VERSION "HIPBNNNYNNNNNNNNNNNNNNNNNNNNNNNNNNYYNNNNNN/4>%%%/4/'%**4NNN///"

NS_ :

BS_:

BU_: ADC BDF BDL BDR BGW CDC DDM VNC Vector_XXX

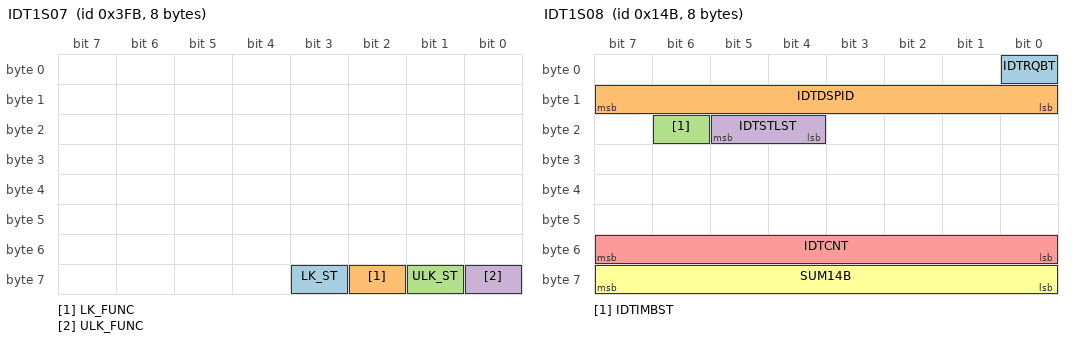
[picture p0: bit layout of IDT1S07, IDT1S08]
BO_ 1019 IDT1S07: 8 BDL
 SG_ LK_ST : 59|1@0+ (1,0) [0|0] "-"  CDC
 SG_ LK_FUNC : 58|1@0+ (1,0) [0|0] "-"  CDC
 SG_ ULK_ST : 57|1@0+ (1,0) [0|0] "-"  CDC
 SG_ ULK_FUNC : 56|1@0+ (1,0) [0|0] "-"  CDC

BO_ 331 IDT1S08: 8 BDL
 SG_ IDTRQBT : 0|1@0+ (1,0) [0|0] "-"  BGW,CDC,DDM
 SG_ IDTDSPID : 15|8@0+ (1,0) [0|0] "-"  BGW,CDC,DDM
 SG_ IDTIMBST : 22|1@0+ (1,0) [0|0] "-"  BGW,CDC,DDM
 SG_ IDTSTLST : 21|2@0+ (1,0) [0|0] "-"  BGW,CDC,DDM
 SG_ IDTCNT : 55|8@0+ (1,0) [0|0] "-"  BGW,CDC,DDM
 SG_ SUM14B : 63|8@0+ (1,0) [0|0] "-"  BGW,CDC,DDM

BO_ 1330 IDT1S15: 8 BDL
 SG_ RSISIDME : 7|2@0+ (1,0) [0|0] "-"  CDC
 SG_ RSISIDID : 5|5@0+ (1,0) [0|0] "-"  CDC

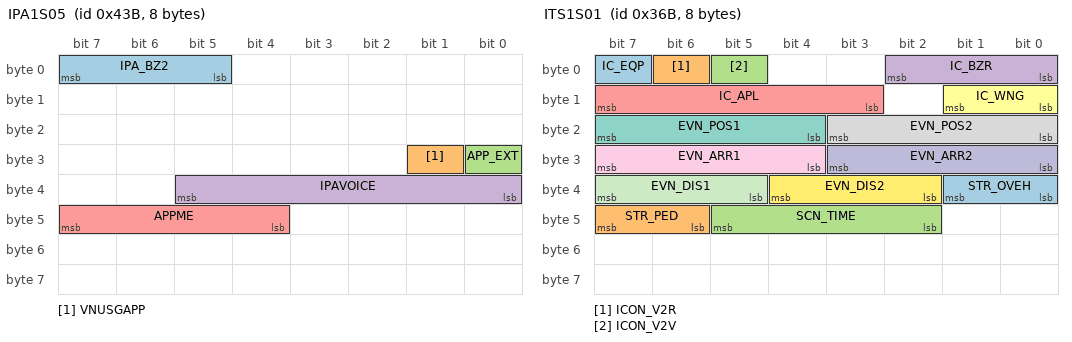
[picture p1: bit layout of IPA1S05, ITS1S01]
BO_ 1083 IPA1S05: 8 ADC
 SG_ IPA_BZ2 : 7|3@0+ (1,0) [0|0] "-"  CDC
 SG_ VNUSGAPP : 25|1@0+ (1,0) [0|0] "-"  CDC
 SG_ APP_EXT : 24|1@0+ (1,0) [0|0] "-"  CDC
 SG_ IPAVOICE : 37|6@0+ (1,0) [0|0] "-"  CDC
 SG_ APPME : 47|4@0+ (1,0) [0|0] "-"  CDC

BO_ 875 ITS1S01: 8 BGW
 SG_ IC_EQP : 7|1@0+ (1,0) [0|0] "-"  CDC
 SG_ ICON_V2R : 6|1@0+ (1,0) [0|0] "-"  CDC
 SG_ ICON_V2V : 5|1@0+ (1,0) [0|0] "-"  CDC
 SG_ IC_BZR : 2|3@0+ (1,0) [0|0] "-"  CDC
 SG_ IC_APL : 15|5@0+ (1,0) [0|0] "-"  CDC
 SG_ IC_WNG : 9|2@0+ (1,0) [0|0] "-"  CDC
 SG_ EVN_POS1 : 23|4@0+ (1,0) [0|0] "-"  CDC
 SG_ EVN_POS2 : 19|4@0+ (1,0) [0|0] "-"  CDC
 SG_ EVN_ARR1 : 31|4@0+ (1,0) [0|0] "-"  CDC
 SG_ EVN_ARR2 : 27|4@0+ (1,0) [0|0] "-"  CDC
 SG_ EVN_DIS1 : 39|3@0+ (1,0) [0|0] "-"  CDC
 SG_ EVN_DIS2 : 36|3@0+ (1,0) [0|0] "-"  CDC
 SG_ STR_OVEH : 33|2@0+ (1,0) [0|0] "-"  CDC
 SG_ STR_PED : 47|2@0+ (1,0) [0|0] "-"  CDC
 SG_ SCN_TIME : 45|4@0+ (1,0) [0|0] "-"  CDC

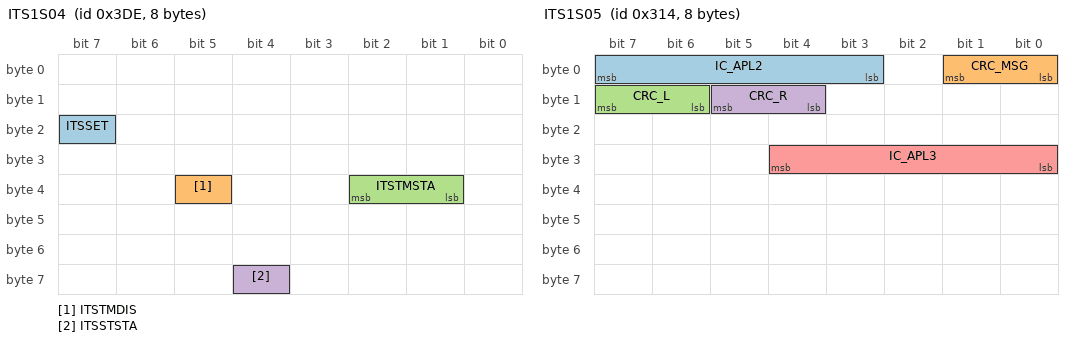
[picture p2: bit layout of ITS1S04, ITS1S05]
BO_ 990 ITS1S04: 8 BGW
 SG_ ITSSET : 23|1@0+ (1,0) [0|0] "-"  CDC
 SG_ ITSTMDIS : 37|1@0+ (1,0) [0|0] "-"  CDC
 SG_ ITSTMSTA : 34|2@0+ (1,0) [0|0] "-"  CDC
 SG_ ITSSTSTA : 60|1@0+ (1,0) [0|0] "-"  CDC

BO_ 788 ITS1S05: 8 BGW
 SG_ IC_APL2 : 7|5@0+ (1,0) [0|0] "-"  CDC
 SG_ CRC_MSG : 1|2@0+ (1,0) [0|0] "-"  CDC
 SG_ CRC_L : 15|2@0+ (1,0) [0|0] "-"  CDC
 SG_ CRC_R : 13|2@0+ (1,0) [0|0] "-"  CDC
 SG_ IC_APL3 : 28|5@0+ (1,0) [0|0] "-"  CDC

BO_ 635 ITS1S08: 8 BGW
 SG_ ITSVOI01 : 40|2@0+ (1,0) [0|0] "-"  CDC

BO_ 371 LRS1S01: 8 BDL
 SG_ LR_RC_PS : 46|8@0+ (0.5,0) [0|0] "deg"  CDC

BO_ 377 LRS1S03: 8 BDL
 SG_ LR_SL_PS : 7|10@0+ (1,0) [0|0] "mm"  CDC

BO_ 378 LRS1S04: 8 BDL
 SG_ LR_LF_PS : 7|8@0+ (0.5,0) [0|0] "deg"  CDC

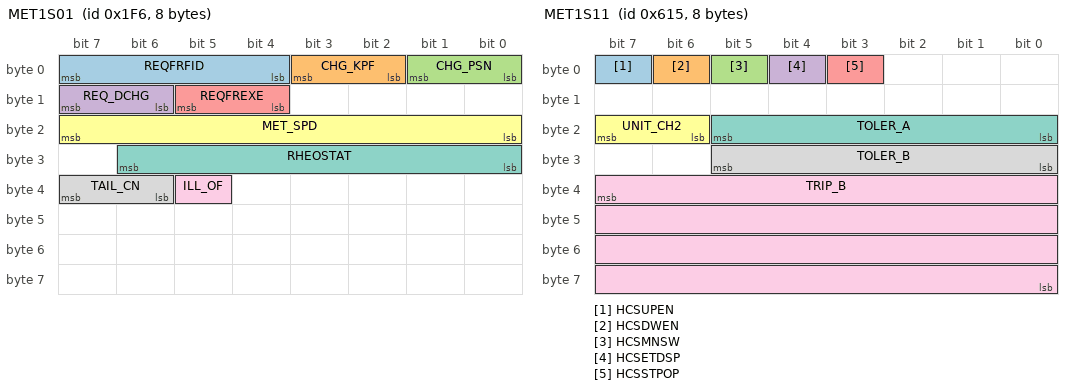
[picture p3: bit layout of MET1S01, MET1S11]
BO_ 502 MET1S01: 8 CDC
 SG_ REQFRFID : 7|4@0+ (1,0) [0|0] "-"  BDL,BGW,DDM
 SG_ CHG_KPF : 3|2@0+ (1,0) [0|0] "-"  BDL,BGW,DDM
 SG_ CHG_PSN : 1|2@0+ (1,0) [0|0] "-"  BDL,BGW,DDM
 SG_ REQ_DCHG : 15|2@0+ (1,0) [0|0] "-"  BDL,BGW,DDM
 SG_ REQFREXE : 13|2@0+ (1,0) [0|0] "-"  BDL,BGW,DDM
 SG_ MET_SPD : 23|8@0+ (1,0) [0|0] "km/h"  BDF,BDL,BDR,BGW,DDM
 SG_ RHEOSTAT : 30|7@0+ (1,0) [0|0] "%"  BDF,BDL,BGW,DDM
 SG_ TAIL_CN : 39|2@0+ (1,0) [0|0] "-"  BDF,BDL,BGW,DDM
 SG_ ILL_OF : 37|1@0+ (1,0) [0|0] "-"  BDF,BDL,BGW,DDM

BO_ 1553 MET1S02: 8 CDC
 SG_ ODO_UNIT : 29|2@0+ (1,0) [0|0] "-"  ADC,BDF,BDL,BGW,DDM,VNC
 SG_ ODO : 39|32@0+ (1,0) [0|0] "km/mile"  ADC,BDF,BDL,BGW,DDM,VNC

BO_ 1560 MET1S03: 8 CDC
 SG_ AS_DT : 47|16@0+ (0.1,0) [0|0] "km,mile"  BGW
 SG_ UNIT_2 : 63|2@0+ (1,0) [0|0] "-"  BGW

BO_ 1556 MET1S10: 8 CDC
 SG_ TRIP_A : 39|32@0+ (0.1,0) [0|0] "km/mile"  BGW

BO_ 1557 MET1S11: 8 CDC
 SG_ HCSUPEN : 7|1@0+ (1,0) [0|0] "-"  BGW,DDM
 SG_ HCSDWEN : 6|1@0+ (1,0) [0|0] "-"  BGW,DDM
 SG_ HCSMNSW : 5|1@0+ (1,0) [0|0] "-"  BGW,DDM
 SG_ HCSETDSP : 4|1@0+ (1,0) [0|0] "-"  BGW,DDM
 SG_ HCSSTPOP : 3|1@0+ (1,0) [0|0] "-"  BGW,DDM
 SG_ UNIT_CH2 : 23|2@0+ (1,0) [0|0] "-"  ADC,BGW,DDM
 SG_ TOLER_A : 21|6@0+ (0.002,0.94) [0|0] "-"  ADC,BGW,DDM
 SG_ TOLER_B : 29|6@0- (0.2,0) [0|0] "km/h"  ADC,BGW,DDM
 SG_ TRIP_B : 39|32@0+ (0.1,0) [0|0] "km/mile"  BGW,DDM

BO_ 1421 MET1S25: 8 CDC
 SG_ PSRSP1 : 23|8@0+ (1,0) [0|0] "-"  BDL
 SG_ PSRSP2 : 31|8@0+ (1,0) [0|0] "-"  BDL
 SG_ PSRSP3 : 39|8@0+ (1,0) [0|0] "-"  BDL

BO_ 1002 MET1S27: 8 CDC
 SG_ CSR_MUTE : 7|1@0+ (1,0) [0|0] "-"  ADC,BGW
 SG_ SW_LTC01 : 2|1@0+ (1,0) [0|0] "-"  ADC,BGW
 SG_ SW_RCD01 : 0|1@0+ (1,0) [0|0] "-"  ADC,BGW
 SG_ TSR_OSL : 13|3@0+ (1,0) [0|0] "-"  ADC,BGW
 SG_ TSR_SNM : 18|2@0+ (1,0) [0|0] "-"  ADC,BGW
 SG_ FCMUSER : 27|1@0+ (1,0) [0|0] "-"  ADC,BGW
 SG_ ITSSETSW : 26|1@0+ (1,0) [0|0] "-"  BGW
 SG_ RCTAMSW : 39|1@0+ (1,0) [0|0] "-"  ADC,BGW
 SG_ ICSMSW : 38|1@0+ (1,0) [0|0] "-"  ADC,BGW
 SG_ BSMMSW : 37|1@0+ (1,0) [0|0] "-"  ADC,BGW
 SG_ CSRMSW : 34|1@0+ (1,0) [0|0] "-"  ADC,BGW
 SG_ SW_ITS04 : 33|1@0+ (1,0) [0|0] "-"  BGW
 SG_ TSR_MAIN : 32|1@0+ (1,0) [0|0] "-"  ADC,BGW
 SG_ LDAMCUS : 47|2@0+ (1,0) [0|0] "-"  ADC,BGW
 SG_ PCSMSW : 40|1@0+ (1,0) [0|0] "-"  ADC,BGW
 SG_ FCMMSW : 52|1@0+ (1,0) [0|0] "-"  ADC,BGW
 SG_ LDA_SFB : 50|3@0+ (1,0) [0|0] "-"  ADC,BGW

BO_ 894 MET1S28: 8 CDC
 SG_ ACINV_SW : 7|1@0+ (1,0) [0|0] "-"  DDM
 SG_ RSCSW_OP : 8|1@0+ (1,0) [0|0] "-"  DDM

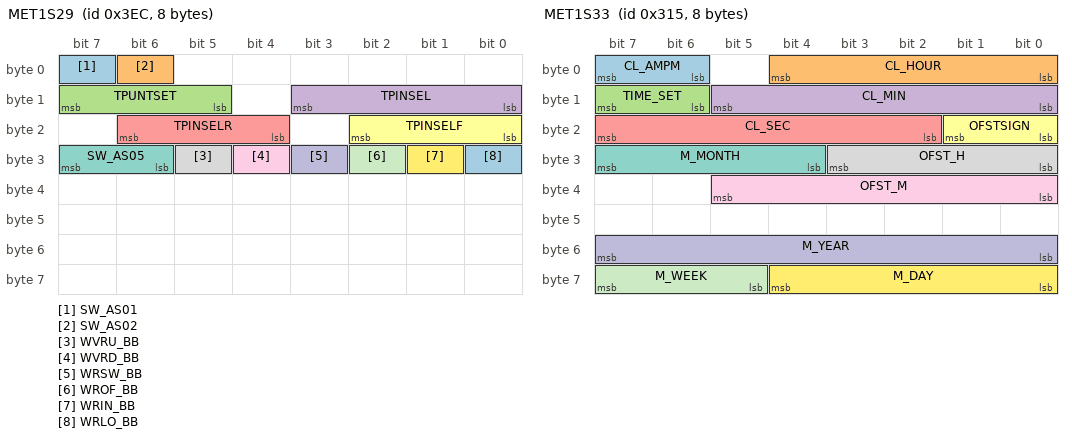
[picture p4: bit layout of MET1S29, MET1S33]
BO_ 1004 MET1S29: 8 CDC
 SG_ SW_AS01 : 7|1@0+ (1,0) [0|0] "-"  BDL,DDM
 SG_ SW_AS02 : 6|1@0+ (1,0) [0|0] "-"  BDL,DDM
 SG_ TPUNTSET : 15|3@0+ (1,0) [0|0] "-"  BDL,DDM
 SG_ TPINSEL : 11|4@0+ (1,0) [0|0] "-"  BDL,DDM
 SG_ TPINSELR : 22|3@0+ (1,0) [0|0] "-"  BDL,DDM
 SG_ TPINSELF : 18|3@0+ (1,0) [0|0] "-"  BDL,DDM
 SG_ SW_AS05 : 31|2@0+ (1,0) [0|0] "-"  BDL,DDM
 SG_ WVRU_BB : 29|1@0+ (1,0) [0|0] "-"  BDL,DDM
 SG_ WVRD_BB : 28|1@0+ (1,0) [0|0] "-"  BDL,DDM
 SG_ WRSW_BB : 27|1@0+ (1,0) [0|0] "-"  BDL,DDM
 SG_ WROF_BB : 26|1@0+ (1,0) [0|0] "-"  BDL,DDM
 SG_ WRIN_BB : 25|1@0+ (1,0) [0|0] "-"  BDL,DDM
 SG_ WRLO_BB : 24|1@0+ (1,0) [0|0] "-"  BDL,DDM

BO_ 1006 MET1S30: 8 CDC
 SG_ PBDKSW : 6|1@0+ (1,0) [0|0] "-"  BDL
 SG_ TITE_BB : 5|4@0+ (1,0) [0|0] "-"  BDL
 SG_ ASD_CANC : 1|1@0+ (1,0) [0|0] "-"  BDL
 SG_ ASD_CONT : 0|1@0+ (1,0) [0|0] "-"  BDL
 SG_ RSRMSW : 15|1@0+ (1,0) [0|0] "-"  BDL
 SG_ SRPMSW : 14|1@0+ (1,0) [0|0] "-"  ADC
 SG_ RSRCANSW : 13|1@0+ (1,0) [0|0] "-"  BDL
 SG_ VRAPRDIS : 12|1@0+ (1,0) [0|0] "-"  ADC
 SG_ PWLSW : 11|1@0+ (1,0) [0|0] "-"  BDL
 SG_ MLR_BB : 10|2@0+ (1,0) [0|0] "-"  BDL
 SG_ DPMS_BB : 8|1@0+ (1,0) [0|0] "-"  BDL
 SG_ LSW_BB : 23|3@0+ (1,0) [0|0] "-"  BDL
 SG_ WSVS_BB : 20|1@0+ (1,0) [0|0] "-"  BDL
 SG_ M_BB : 19|3@0+ (1,0) [0|0] "-"  BDL
 SG_ VRESTPSW : 31|1@0+ (1,0) [0|0] "-"  BDL
 SG_ MRT_BB : 30|2@0+ (1,0) [0|0] "-"  BDL
 SG_ RLM_BB : 28|2@0+ (1,0) [0|0] "-"  BDL
 SG_ FOG_BB : 26|2@0+ (1,0) [0|0] "-"  BDL
 SG_ MINTRSOF : 39|1@0+ (1,0) [0|0] "-"  BDL
 SG_ RFG_BB : 38|2@0+ (1,0) [0|0] "-"  BDL
 SG_ ART_BB : 36|2@0+ (1,0) [0|0] "-"  BDL
 SG_ PBD_BB : 34|3@0+ (1,0) [0|0] "-"  BDL
 SG_ POS_REG : 47|2@0+ (1,0) [0|0] "-"  BDL
 SG_ PBDBZMVL : 45|2@0+ (1,0) [0|0] "-"  BDL
 SG_ POS_CALL : 43|2@0+ (1,0) [0|0] "-"  BDL
 SG_ PBDMSW : 55|1@0+ (1,0) [0|0] "-"  BDL
 SG_ PBDMCUS : 54|3@0+ (1,0) [0|0] "-"  BDL
 SG_ ULKMSW : 51|1@0+ (1,0) [0|0] "-"  BDL
 SG_ LKMSW : 50|1@0+ (1,0) [0|0] "-"  BDL
 SG_ VRAPRMSW : 63|2@0+ (1,0) [0|0] "-"  ADC

BO_ 789 MET1S33: 8 CDC
 SG_ CL_AMPM : 7|2@0+ (1,0) [0|0] "-"  BDL,DDM
 SG_ CL_HOUR : 4|5@0+ (1,0) [0|0] "hour"  BDL,DDM
 SG_ TIME_SET : 15|2@0+ (1,0) [0|0] "-"  BDL
 SG_ CL_MIN : 13|6@0+ (1,0) [0|0] "minute"  BDL,DDM
 SG_ CL_SEC : 23|6@0+ (1,0) [0|0] "sec"  BDL,DDM
 SG_ OFSTSIGN : 17|2@0+ (1,0) [0|0] "-"  BDL
 SG_ M_MONTH : 31|4@0+ (1,0) [0|0] "-"  BDL
 SG_ OFST_H : 27|4@0+ (1,0) [0|0] "hour"  BDL
 SG_ OFST_M : 37|6@0+ (1,0) [0|0] "minute"  BDL
 SG_ M_YEAR : 55|8@0+ (1,2000) [0|0] "year"  BDL
 SG_ M_WEEK : 63|3@0+ (1,0) [0|0] "-"  BDL,DDM
 SG_ M_DAY : 60|5@0+ (1,0) [0|0] "-"  BDL

BO_ 1316 MET1S38: 32 CDC
 SG_ AS_TM : 7|16@0+ (1,0) [0|0] "min"  BGW
 SG_ EC_SCL : 20|3@0+ (1,0) [0|0] "-"  BGW
 SG_ TR2_DUTY : 17|10@0+ (0.1,0) [0|0] "%"  BDL,BGW
 SG_ IL2_DUTY : 55|10@0+ (0.1,0) [0|0] "%"  BDL,BGW
 SG_ RANGE : 71|16@0+ (1,0) [0|0] "Note"  BGW
 SG_ AS_SP : 87|16@0+ (0.1,0) [0|0] "km/h,mph"  BGW
 SG_ UNIT_1 : 103|2@0+ (1,0) [0|0] "-"  BGW
 SG_ UNIT_6 : 101|3@0+ (1,0) [0|0] "-"  BGW
 SG_ NFCS : 98|2@0+ (1,0) [0|0] "-"  BGW
 SG_ RHEO_POS : 96|5@0+ (1,0) [0|0] "-"  BDL,BGW

BO_ 1319 MET1S41: 8 CDC
 SG_ ST_ACOFF : 32|1@0+ (1,0) [0|0] "-"  BDF,BDL
 SG_ ST_TDEF : 55|1@0+ (1,0) [0|0] "-"  BDF,BDL
 SG_ ST_TAUTO : 54|1@0+ (1,0) [0|0] "-"  BDF,BDL

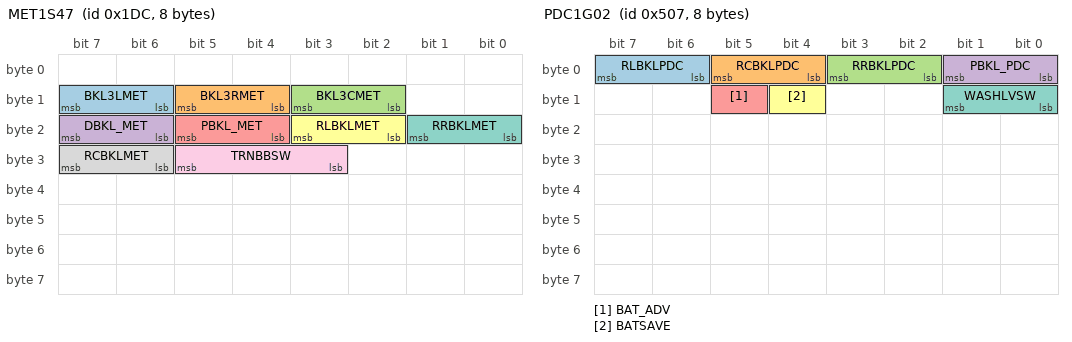
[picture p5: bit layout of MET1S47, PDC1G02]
BO_ 476 MET1S47: 8 CDC
 SG_ BKL3LMET : 15|2@0+ (1,0) [0|0] "-"  BGW,DDM
 SG_ BKL3RMET : 13|2@0+ (1,0) [0|0] "-"  BGW,DDM
 SG_ BKL3CMET : 11|2@0+ (1,0) [0|0] "-"  BGW,DDM
 SG_ DBKL_MET : 23|2@0+ (1,0) [0|0] "-"  ADC,BDL,BDR,BGW,DDM,VNC
 SG_ PBKL_MET : 21|2@0+ (1,0) [0|0] "-"  ADC,BDL,BDR,BGW,DDM,VNC
 SG_ RLBKLMET : 19|2@0+ (1,0) [0|0] "-"  BDL,BDR,BGW,DDM,VNC
 SG_ RRBKLMET : 17|2@0+ (1,0) [0|0] "-"  BDL,BDR,BGW,DDM,VNC
 SG_ RCBKLMET : 31|2@0+ (1,0) [0|0] "-"  BGW,DDM,VNC
 SG_ TRNBBSW : 29|3@0+ (1,0) [0|0] "-"  ADC,BGW,DDM

BO_ 781 MET1S52: 8 CDC
 SG_ ODO_UNI2 : 31|2@0+ (1,0) [0|0] "-"  BGW
 SG_ ODO_01 : 39|32@0+ (0.1,0) [0|0] "km"  BGW

BO_ 503 MET1S55: 32 CDC
 SG_ IN_EC : 7|16@0+ (0.1,0) [0|0] "Note"  BGW
 SG_ M1_EC1 : 23|16@0+ (0.1,0) [0|0] "km/kW, mile/kW(US), mile/kW(UK),"  BGW
 SG_ M1_EC_R : 55|1@0+ (1,0) [0|0] "-"  BGW
 SG_ EV_RANGE : 63|16@0+ (1,0) [0|0] "Note"  BGW,VNC
 SG_ TO_EC : 79|16@0+ (0.1,0) [0|0] "km/kW, mile/kW(US), mile/kW(UK),"  BGW
 SG_ AS_EC : 95|16@0+ (0.1,0) [0|0] "km/kW, mile/kW(US), mile/kW(UK),"  BGW
 SG_ AS_TOEC : 111|16@0+ (0.1,0) [0|0] "kWh"  BGW
 SG_ AS_EVDT : 127|16@0+ (0.1,0) [0|0] "km,mile"  BGW

BO_ 1050 MET1S62: 8 CDC
 SG_ RNGMSW : 35|1@0+ (1,0) [0|0] "-"  DDM
 SG_ TBCSW : 41|1@0+ (1,0) [0|0] "-"  DDM
 SG_ TBWSW : 40|1@0+ (1,0) [0|0] "-"  DDM

BO_ 957 PCN1S01: 32 DDM
 SG_ MSG_NSFT : 9|2@0+ (1,0) [0|0] "-"  CDC
 SG_ MSG_CHK : 21|1@0+ (1,0) [0|0] "-"  CDC
 SG_ MSG_SFTF : 31|1@0+ (1,0) [0|0] "-"  CDC
 SG_ B_SLUP_S : 30|1@0+ (1,0) [0|0] "-"  CDC
 SG_ B_SLDN_S : 29|1@0+ (1,0) [0|0] "-"  CDC
 SG_ MSG_RI_S : 28|5@0+ (1,0) [0|0] "-"  CDC
 SG_ BZR_SFT1 : 55|4@0+ (1,0) [0|0] "-"  CDC
 SG_ B_GEAR_S : 51|4@0+ (1,0) [0|0] "-"  CDC
 SG_ MSG_SFPF : 61|1@0+ (1,0) [0|0] "-"  CDC
 SG_ SBWFUNC : 60|1@0+ (1,0) [0|0] "-"  CDC
 SG_ SFT_BLKS : 59|2@0+ (1,0) [0|0] "-"  CDC
 SG_ SFT_METS : 57|4@0+ (1,0) [0|0] "-"  CDC
 SG_ SILUASBW : 69|1@0+ (1,0) [0|0] "-"  CDC
 SG_ MSG_DAP : 68|1@0+ (1,0) [0|0] "-"  CDC
 SG_ MSG_ACCN : 67|1@0+ (1,0) [0|0] "-"  CDC
 SG_ FV3BD : 175|56@0+ (1,0) [0|0] "-"  CDC
 SG_ KZK3BD : 231|32@0+ (1,0) [0|0] "-"  CDC

BO_ 460 PDC1G01: 8 BDL
 SG_ BAOF_PDC : 25|1@0+ (1,0) [0|0] "-"  CDC,DDM

BO_ 1287 PDC1G02: 8 BDF
 SG_ RLBKLPDC : 7|2@0+ (1,0) [0|0] "-"  CDC
 SG_ RCBKLPDC : 5|2@0+ (1,0) [0|0] "-"  CDC
 SG_ RRBKLPDC : 3|2@0+ (1,0) [0|0] "-"  CDC
 SG_ PBKL_PDC : 1|2@0+ (1,0) [0|0] "-"  CDC
 SG_ BAT_ADV : 13|1@0+ (1,0) [0|0] "-"  CDC
 SG_ BATSAVE : 12|1@0+ (1,0) [0|0] "-"  CDC
 SG_ WASHLVSW : 9|2@0+ (1,0) [0|0] "-"  CDC

BO_ 661 PLG1G15: 32 DDM
 SG_ OTACHGWT : 31|2@0+ (1,0) [0|0] "-"  BGW,CDC
 SG_ P_SPLNSO : 47|1@0+ (1,0) [0|0] "-"  BGW,CDC
 SG_ P_DVOAVA : 71|2@0+ (1,0) [0|0] "-"  BGW,CDC
 SG_ P_DVOSL1 : 69|1@0+ (1,0) [0|0] "-"  BGW,CDC
 SG_ P_WLCEQP : 72|1@0+ (1,0) [0|0] "-"  BGW,CDC
 SG_ P_SETID : 87|6@0+ (1,0) [0|0] "-"  BGW,CDC
 SG_ P_SETON : 95|1@0+ (1,0) [0|0] "-"  BGW,CDC
 SG_ P_SETWKD : 94|7@0+ (1,0) [0|0] "-"  BGW,CDC
 SG_ P_SETTYP : 103|4@0+ (1,0) [0|0] "-"  BGW,CDC
 SG_ P_SETSTM : 96|9@0+ (5,0) [0|0] "min"  BGW,CDC
 SG_ P_SETNXT : 119|6@0+ (1,0) [0|0] "-"  BGW,CDC
 SG_ P_SETFTM : 112|9@0+ (5,0) [0|0] "min"  BGW,CDC
 SG_ P_TMPID : 135|6@0+ (1,0) [0|0] "-"  BGW,CDC
 SG_ P_TMPSWK : 142|7@0+ (1,0) [0|0] "-"  BGW,CDC
 SG_ P_TMPSTM : 151|9@0+ (5,0) [0|0] "min"  BGW,CDC
 SG_ P_ADDDSP : 158|1@0+ (1,0) [0|0] "-"  BGW,CDC
 SG_ PCNOWDSP : 155|2@0+ (1,0) [0|0] "-"  BGW,CDC
 SG_ P_EDTDSP : 153|1@0+ (1,0) [0|0] "-"  BGW,CDC
 SG_ P_TMPTYP : 167|4@0+ (1,0) [0|0] "-"  BGW,CDC
 SG_ P_TMPNWK : 163|3@0+ (1,0) [0|0] "-"  BGW,CDC
 SG_ P_TMPFTM : 160|9@0+ (5,0) [0|0] "min"  BGW,CDC
 SG_ P_DPWAVA : 177|2@0+ (1,0) [0|0] "-"  BGW,CDC
 SG_ P_DPWSL : 198|4@0+ (1,0) [0|0] "-"  BGW,CDC

BO_ 662 PLG1G16: 32 DDM
 SG_ PLGSTS : 103|8@0+ (1,0) [0|0] "-"  BGW,CDC
 SG_ PIINFD08 : 111|8@0+ (1,0) [0|0] "-"  BGW,CDC
 SG_ PIINFDSP : 119|1@0+ (1,0) [0|0] "-"  BGW,CDC
 SG_ PSDSPRQ2 : 118|1@0+ (1,0) [0|0] "-"  BGW,CDC
 SG_ PSDSPRQ : 117|1@0+ (1,0) [0|0] "-"  BGW,CDC
 SG_ P_CLCSL4 : 115|1@0+ (1,0) [0|0] "-"  BGW,CDC
 SG_ P_CLCSL3 : 114|1@0+ (1,0) [0|0] "-"  BGW,CDC
 SG_ P_CLCSL2 : 113|1@0+ (1,0) [0|0] "-"  BGW,CDC
 SG_ P_CLCSL1 : 112|1@0+ (1,0) [0|0] "-"  BGW,CDC
 SG_ P_LMDAVA : 126|2@0+ (1,0) [0|0] "-"  BGW,CDC
 SG_ PLID_DSP : 124|1@0+ (1,0) [0|0] "-"  BGW,CDC
 SG_ P_LMDNW : 123|1@0+ (1,0) [0|0] "-"  BGW,CDC
 SG_ DCRCKDSP : 122|3@0+ (1,0) [0|0] "-"  BGW,CDC
 SG_ P_SETSTS : 131|4@0+ (1,0) [0|0] "-"  BGW,CDC
 SG_ P_DPW : 139|4@0+ (1,0) [0|0] "-"  BGW,CDC
 SG_ P_NCTYP : 151|4@0+ (1,0) [0|0] "-"  BGW,CDC
 SG_ P_NCWKD : 147|3@0+ (1,0) [0|0] "-"  BGW,CDC
 SG_ P_NCSTM : 144|9@0+ (5,0) [0|0] "min"  BGW,CDC
 SG_ P_SLMSL1 : 166|1@0+ (1,0) [0|0] "-"  BGW,CDC
 SG_ P_NCDSP : 162|2@0+ (1,0) [0|0] "-"  BGW,CDC
 SG_ P_NCFTM : 160|9@0+ (5,0) [0|0] "min"  BGW,CDC
 SG_ P_SLMSL3 : 183|1@0+ (1,0) [0|0] "-"  BGW,CDC
 SG_ P_SLMSL2 : 182|1@0+ (1,0) [0|0] "-"  BGW,CDC
 SG_ P_NCLMT : 181|3@0+ (1,0) [0|0] "-"  BGW,CDC
 SG_ P_NCCUR : 178|3@0+ (1,0) [0|0] "-"  BGW,CDC
 SG_ P_SLMSL5 : 191|1@0+ (1,0) [0|0] "-"  BGW,CDC
 SG_ P_SLMSL4 : 190|1@0+ (1,0) [0|0] "-"  BGW,CDC
 SG_ P_SLMNOW : 186|3@0+ (1,0) [0|0] "-"  BGW,CDC
 SG_ PCHGTM07 : 199|16@0+ (1,0) [0|0] "min"  BGW,CDC
 SG_ P_TMRAVA : 215|2@0+ (1,0) [0|0] "-"  BGW,CDC
 SG_ P_CURAVA : 213|2@0+ (1,0) [0|0] "-"  BGW,CDC
 SG_ P_LMTAVA : 211|2@0+ (1,0) [0|0] "-"  BGW,CDC
 SG_ P_CLCAVA : 209|2@0+ (1,0) [0|0] "-"  BGW,CDC
 SG_ P_LMTDSP : 222|3@0+ (1,0) [0|0] "-"  BGW,CDC
 SG_ P_SPLAVA : 219|2@0+ (1,0) [0|0] "-"  BGW,CDC
 SG_ P_SLMAVA : 217|2@0+ (1,0) [0|0] "-"  BGW,CDC
 SG_ P_TMRSTR : 231|2@0+ (1,0) [0|0] "-"  BGW,CDC
 SG_ P_TMRSST : 227|2@0+ (1,0) [0|0] "-"  BGW,CDC
 SG_ P_SPLEVA : 239|2@0+ (1,0) [0|0] "-"  BGW,CDC
 SG_ P_SPLHVA : 247|2@0+ (1,0) [0|0] "-"  BGW,CDC
 SG_ P_LMTSEL : 245|3@0+ (1,0) [0|0] "-"  BGW,CDC
 SG_ P_LMTNOW : 242|3@0+ (1,0) [0|0] "-"  BGW,CDC
 SG_ P_SPLDSP : 255|2@0+ (1,0) [0|0] "-"  BGW,CDC
 SG_ P_SPLEVW : 253|1@0+ (1,0) [0|0] "-"  BGW,CDC
 SG_ P_SPLACA : 252|1@0+ (1,0) [0|0] "-"  BGW,CDC
 SG_ P_SPLDCA : 251|1@0+ (1,0) [0|0] "-"  BGW,CDC

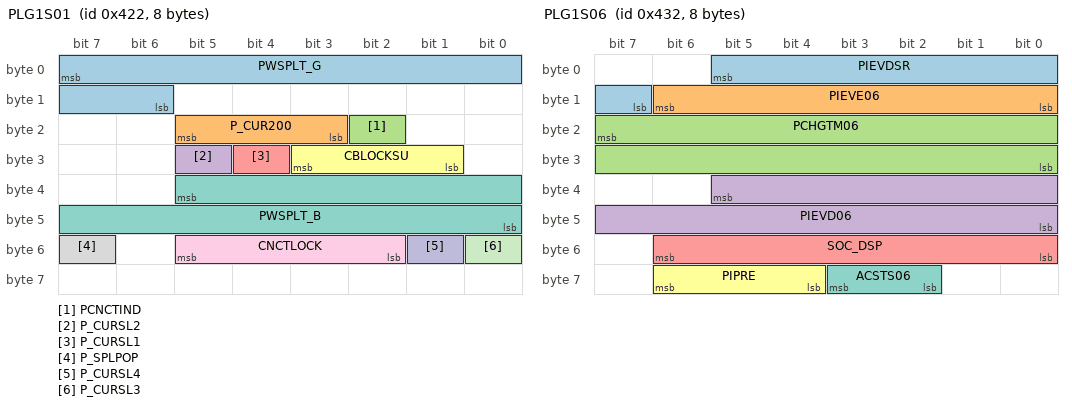
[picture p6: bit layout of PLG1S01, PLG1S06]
BO_ 1058 PLG1S01: 8 DDM
 SG_ PWSPLT_G : 7|10@0+ (1,0) [0|0] "hour"  BGW,CDC
 SG_ P_CUR200 : 21|3@0+ (1,0) [0|0] "-"  BGW,CDC
 SG_ PCNCTIND : 18|1@0+ (1,0) [0|0] "-"  BGW,CDC
 SG_ P_CURSL2 : 29|1@0+ (1,0) [0|0] "-"  BGW,CDC
 SG_ P_CURSL1 : 28|1@0+ (1,0) [0|0] "-"  BGW,CDC
 SG_ CBLOCKSU : 27|3@0+ (1,0) [0|0] "-"  BGW,CDC
 SG_ PWSPLT_B : 37|14@0+ (10,0) [0|0] "min"  BGW,CDC
 SG_ P_SPLPOP : 55|1@0+ (1,0) [0|0] "-"  BGW,CDC
 SG_ CNCTLOCK : 53|4@0+ (1,0) [0|0] "-"  BGW,CDC
 SG_ P_CURSL4 : 49|1@0+ (1,0) [0|0] "-"  BGW,CDC
 SG_ P_CURSL3 : 48|1@0+ (1,0) [0|0] "-"  BGW,CDC

BO_ 1073 PLG1S05: 8 DDM
 SG_ MRMMSG : 20|3@0+ (1,0) [0|0] "-"  CDC

BO_ 1074 PLG1S06: 8 DDM
 SG_ PIEVDSR : 5|7@0+ (1,0) [0|0] "%"  BGW,CDC
 SG_ PIEVE06 : 14|7@0+ (1,0) [0|0] "%"  BGW,CDC
 SG_ PCHGTM06 : 23|16@0+ (1,0) [0|0] "min"  BGW,CDC
 SG_ PIEVD06 : 37|14@0+ (0.1,0) [0|0] "km"  BGW,CDC
 SG_ SOC_DSP : 54|7@0+ (1,0) [0|0] "%"  BGW,CDC
 SG_ PIPRE : 62|3@0+ (1,0) [0|0] "-"  BGW,CDC
 SG_ ACSTS06 : 59|2@0+ (1,0) [0|0] "-"  BGW,CDC

BO_ 678 PLG1S20: 32 DDM
 SG_ R_NBPSET : 7|1@0+ (1,0) [0|0] "-"  BGW,CDC
 SG_ R_NACSET : 6|1@0+ (1,0) [0|0] "-"  BGW,CDC
 SG_ R_ADDDSP : 5|1@0+ (1,0) [0|0] "-"  BGW,CDC
 SG_ R_BPEXST : 4|1@0+ (1,0) [0|0] "-"  BGW,CDC
 SG_ R_BPON : 3|1@0+ (1,0) [0|0] "-"  BGW,CDC
 SG_ R_BPSET : 2|1@0+ (1,0) [0|0] "-"  BGW,CDC
 SG_ R_ACSET : 1|1@0+ (1,0) [0|0] "-"  BGW,CDC
 SG_ R_NDEPTM : 0|9@0+ (5,0) [0|0] "min"  BGW,CDC
 SG_ P_VPAVST : 23|1@0+ (1,0) [0|0] "-"  BGW,CDC
 SG_ R_NBPWKD : 22|3@0+ (1,0) [0|0] "-"  BGW,CDC
 SG_ R_BPID : 19|3@0+ (1,0) [0|0] "-"  BGW,CDC
 SG_ R_DEPTM : 16|9@0+ (5,0) [0|0] "min"  BGW,CDC
 SG_ R_BPWKD : 39|7@0+ (1,0) [0|0] "-"  BGW,CDC
 SG_ P_VPVGST : 32|1@0+ (1,0) [0|0] "-"  BGW,CDC
 SG_ P_OCTAVA : 47|3@0+ (1,0) [0|0] "-"  BGW,CDC
 SG_ P_OCTID : 41|2@0+ (1,0) [0|0] "-"  BGW,CDC
 SG_ P_LMTNO2 : 55|3@0+ (1,0) [0|0] "-"  BGW,CDC
 SG_ P_OCTON : 52|1@0+ (1,0) [0|0] "-"  BGW,CDC
 SG_ P_OCTTYP : 51|2@0+ (1,0) [0|0] "-"  BGW,CDC
 SG_ P_OCTON2 : 49|1@0+ (1,0) [0|0] "-"  BGW,CDC
 SG_ P_OCTSTM : 48|9@0+ (5,0) [0|0] "minute"  BGW,CDC
 SG_ P_OCTWKD : 71|7@0+ (1,0) [0|0] "-"  BGW,CDC
 SG_ P_OCTFTM : 64|9@0+ (5,0) [0|0] "minute"  BGW,CDC
 SG_ P_OCTWK2 : 87|7@0+ (1,0) [0|0] "-"  BGW,CDC
 SG_ P_OCTST2 : 80|9@0+ (5,0) [0|0] "minute"  BGW,CDC
 SG_ P_USOC2A : 103|7@0+ (1,0) [0|0] "percent"  BGW,CDC
 SG_ P_OCTFT2 : 96|9@0+ (5,0) [0|0] "minute"  BGW,CDC
 SG_ P_USOC1A : 119|7@0+ (1,0) [0|0] "percent"  BGW,CDC
 SG_ P_LMDSTM : 112|9@0+ (5,0) [0|0] "minute"  BGW,CDC
 SG_ P_USOC0A : 135|7@0+ (1,0) [0|0] "percent"  BGW,CDC
 SG_ P_LMDFTM : 128|9@0+ (5,0) [0|0] "minute"  BGW,CDC
 SG_ P_LMDLMT : 151|7@0+ (1,0) [0|0] "percent"  BGW,CDC
 SG_ P_LMDST2 : 144|9@0+ (5,0) [0|0] "minute"  BGW,CDC
 SG_ P_LMDWKD : 167|7@0+ (1,0) [0|0] "-"  BGW,CDC
 SG_ P_LMDFT2 : 160|9@0+ (5,0) [0|0] "minute"  BGW,CDC
 SG_ P_LMDLM2 : 183|7@0+ (1,0) [0|0] "percent"  BGW,CDC
 SG_ P_OCADFL : 176|1@0+ (1,0) [0|0] "-"  BGW,CDC
 SG_ P_LMDWK2 : 191|7@0+ (1,0) [0|0] "-"  BGW,CDC
 SG_ P_OCFLFL : 184|1@0+ (1,0) [0|0] "-"  BGW,CDC
 SG_ P_OCTTY2 : 199|2@0+ (1,0) [0|0] "-"  BGW,CDC
 SG_ P_OCRQFL : 197|2@0+ (1,0) [0|0] "-"  BGW,CDC
 SG_ P_OCNFFL : 195|1@0+ (1,0) [0|0] "-"  BGW,CDC
 SG_ EV_CON_N : 207|4@0+ (1,0) [0|0] "-"  BGW,CDC
 SG_ EV_CON_Q : 203|4@0+ (1,0) [0|0] "-"  BGW,CDC
 SG_ P_VPSOCT : 222|7@0+ (1,0) [0|0] "%"  BGW,CDC
 SG_ P_VPSOCL : 230|7@0+ (1,0) [0|0] "%"  BGW,CDC

BO_ 516 PLG1S21: 32 DDM
 SG_ P_PNC : 7|1@0+ (1,0) [0|0] "-"  BGW,CDC
 SG_ P_ACINST : 12|3@0+ (1,0) [0|0] "-"  BGW,CDC
 SG_ P_PNCAVA : 9|2@0+ (1,0) [0|0] "-"  BGW,CDC
 SG_ P_CEIBRQ : 23|2@0+ (1,0) [0|0] "-"  BGW,CDC
 SG_ P_CEEXPD : 21|5@0+ (1,0) [0|0] "-"  BGW,CDC
 SG_ ACTCHGRT : 37|14@0+ (0.05,0) [0|0] "kW"  BGW,CDC
 SG_ CRTDSPRQ : 55|2@0+ (0.05,0) [0|0] "kW"  BGW,CDC
 SG_ MXCHGRT : 53|14@0+ (0.05,0) [0|0] "kW"  BGW,CDC
 SG_ ACTOPSPW : 71|8@0+ (0.1,0) [0|0] "kW"  BGW,CDC
 SG_ MXOPSPW : 79|8@0+ (0.1,0) [0|0] "kW"  BGW,CDC
 SG_ SPWDSPRQ : 84|2@0+ (1,0) [0|0] "-"  BGW,CDC
 SG_ PSPLTAVA : 82|3@0+ (1,0) [0|0] "-"  BGW,CDC
 SG_ P_CEEXPY : 95|8@0+ (1,0) [0|0] "-"  BGW,CDC
 SG_ P_CEEXPM : 103|4@0+ (1,0) [0|0] "-"  BGW,CDC

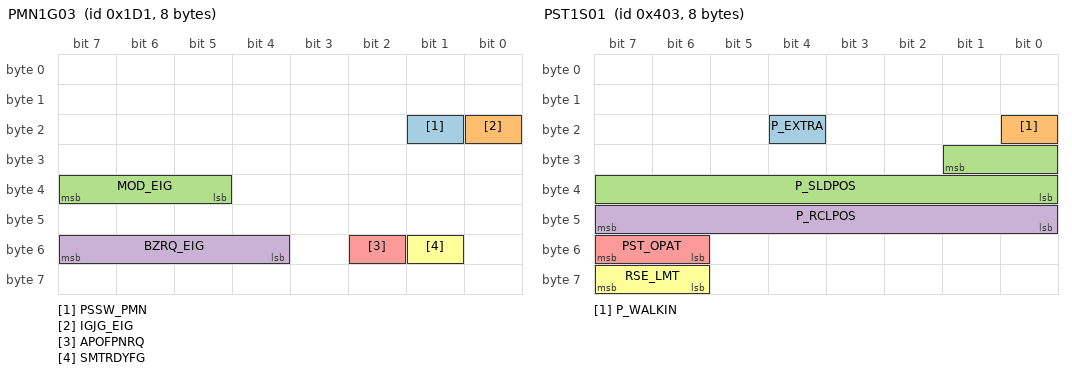
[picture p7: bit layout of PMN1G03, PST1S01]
BO_ 465 PMN1G03: 8 BDL
 SG_ PSSW_PMN : 17|1@0+ (1,0) [0|0] "-"  BGW,CDC
 SG_ IGJG_EIG : 16|1@0+ (1,0) [0|0] "-"  BGW,CDC,DDM
 SG_ MOD_EIG : 39|3@0+ (1,0) [0|0] "-"  BGW,CDC,DDM
 SG_ BZRQ_EIG : 55|4@0+ (1,0) [0|0] "-"  BGW,CDC,DDM
 SG_ APOFPNRQ : 50|1@0+ (1,0) [0|0] "-"  BGW,CDC,DDM
 SG_ SMTRDYFG : 49|1@0+ (1,0) [0|0] "-"  BGW,CDC,DDM

BO_ 1027 PST1S01: 8 BDL
 SG_ P_EXTRA : 20|1@0+ (1,0) [0|0] "-"  CDC
 SG_ P_WALKIN : 16|1@0+ (1,0) [0|0] "-"  CDC
 SG_ P_SLDPOS : 25|10@0+ (1,0) [0|0] "mm"  CDC
 SG_ P_RCLPOS : 47|8@0+ (0.5,0) [0|0] "deg"  CDC
 SG_ PST_OPAT : 55|2@0+ (1,0) [0|0] "-"  CDC
 SG_ RSE_LMT : 63|2@0+ (1,0) [0|0] "-"  CDC

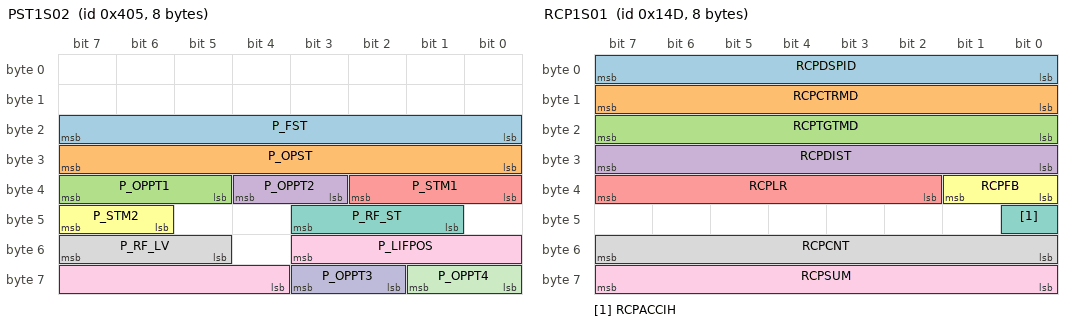
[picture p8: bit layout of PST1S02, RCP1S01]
BO_ 1029 PST1S02: 8 BDL
 SG_ P_FST : 23|8@0+ (1,0) [0|0] "-"  CDC
 SG_ P_OPST : 31|8@0+ (1,0) [0|0] "-"  CDC
 SG_ P_OPPT1 : 39|3@0+ (1,0) [0|0] "-"  CDC
 SG_ P_OPPT2 : 36|2@0+ (1,0) [0|0] "-"  CDC
 SG_ P_STM1 : 34|3@0+ (1,0) [0|0] "-"  CDC
 SG_ P_STM2 : 47|2@0+ (1,0) [0|0] "-"  CDC
 SG_ P_RF_ST : 43|3@0+ (1,0) [0|0] "-"  CDC
 SG_ P_RF_LV : 55|3@0+ (1,0) [0|0] "-"  CDC
 SG_ P_LIFPOS : 51|8@0+ (1,0) [0|0] "mm"  CDC
 SG_ P_OPPT3 : 59|2@0+ (1,0) [0|0] "-"  CDC
 SG_ P_OPPT4 : 57|2@0+ (1,0) [0|0] "-"  CDC

BO_ 333 RCP1S01: 8 ADC
 SG_ RCPDSPID : 7|8@0+ (1,0) [0|0] "-"  BGW,CDC
 SG_ RCPCTRMD : 15|8@0+ (1,0) [0|0] "-"  BGW,CDC
 SG_ RCPTGTMD : 23|8@0+ (1,0) [0|0] "-"  BGW,CDC
 SG_ RCPDIST : 31|8@0+ (1,0) [0|0] "-"  BGW,CDC
 SG_ RCPLR : 39|6@0+ (1,0) [0|0] "-"  BGW,CDC
 SG_ RCPFB : 33|2@0+ (1,0) [0|0] "-"  BGW,CDC
 SG_ RCPACCIH : 40|1@0+ (1,0) [0|0] "-"  BGW,CDC
 SG_ RCPCNT : 55|8@0+ (1,0) [0|0] "-"  BGW,CDC
 SG_ RCPSUM : 63|8@0+ (1,0) [0|0] "-"  BGW,CDC

BO_ 335 RCP1S03: 8 ADC
 SG_ RCPMD : 31|3@0+ (1,0) [0|0] "-"  CDC
 SG_ RCPFAIL : 27|1@0+ (1,0) [0|0] "-"  CDC
 SG_ RCPONST : 36|1@0+ (1,0) [0|0] "-"  CDC

BO_ 386 RRS1S01: 8 BDL
 SG_ RR_RC_PS : 46|8@0+ (0.5,0) [0|0] "deg"  CDC

BO_ 393 RRS1S03: 8 BDL
 SG_ RR_SL_PS : 7|10@0+ (1,0) [0|0] "mm"  CDC

BO_ 396 RRS1S04: 8 BDL
 SG_ RR_LF_PS : 7|8@0+ (0.5,0) [0|0] "deg"  CDC

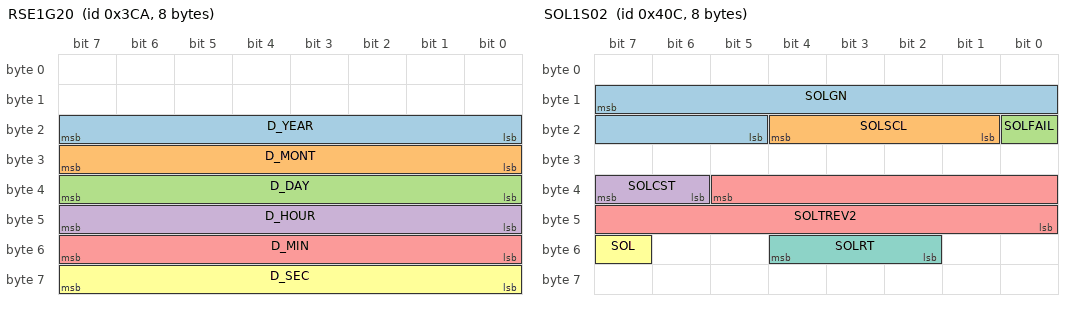
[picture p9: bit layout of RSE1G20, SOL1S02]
BO_ 970 RSE1G20: 8 BGW
 SG_ D_YEAR : 23|8@0+ (1,0) [0|0] "-"  CDC
 SG_ D_MONT : 31|8@0+ (1,0) [0|0] "-"  CDC
 SG_ D_DAY : 39|8@0+ (1,0) [0|0] "-"  CDC
 SG_ D_HOUR : 47|8@0+ (1,0) [0|0] "-"  CDC
 SG_ D_MIN : 55|8@0+ (1,0) [0|0] "-"  CDC
 SG_ D_SEC : 63|8@0+ (1,0) [0|0] "-"  CDC

BO_ 815 RSE1G24: 8 BGW
 SG_ LATUDE : 13|1@0+ (1,0) [0|0] "-"  CDC,DDM
 SG_ LOTUDE1 : 12|1@0+ (1,0) [0|0] "-"  CDC,DDM
 SG_ D_LAT1 : 39|8@0+ (1,0) [0|0] "deg"  CDC,DDM
 SG_ D_LAT2 : 47|24@0+ (5.96046447753906E-008,0) [0|0] "deg"  CDC,DDM

BO_ 822 RSE1G25: 8 BGW
 SG_ D_LON1 : 39|8@0+ (1,0) [0|0] "deg"  CDC,DDM
 SG_ D_LON2 : 47|24@0+ (5.96046447753906E-008,0) [0|0] "deg"  CDC,DDM

BO_ 845 RSE1G26: 8 BGW
 SG_ ALTITUDE : 47|24@0- (0.01,0) [0|0] "m"  CDC,DDM

BO_ 901 RSE1G29: 8 BGW
 SG_ OTADTYPE : 7|4@0+ (1,0) [0|0] "-"  CDC
 SG_ OTADSTAT : 3|4@0+ (1,0) [0|0] "-"  CDC
 SG_ OTADPROG : 15|8@0+ (1,0) [0|0] "%"  CDC
 SG_ OTADERR : 23|8@0+ (1,0) [0|0] "-"  CDC

BO_ 968 RSE1S02: 8 BGW
 SG_ RSCYCL11 : 23|8@0+ (1,0) [0|0] "-"  CDC,DDM
 SG_ RSCYCL12 : 31|8@0+ (1,0) [0|0] "-"  CDC,DDM
 SG_ RSCYCL13 : 39|8@0+ (1,0) [0|0] "-"  CDC,DDM
 SG_ RSCYCL14 : 47|8@0+ (1,0) [0|0] "-"  CDC,DDM
 SG_ RSCYCL15 : 55|8@0+ (1,0) [0|0] "-"  CDC,DDM
 SG_ RSCYCL16 : 63|8@0+ (1,0) [0|0] "-"  CDC,DDM

BO_ 808 RST1S03: 8 BDL
 SG_ S_RTST_L : 31|1@0+ (1,0) [0|0] "-"  CDC
 SG_ S_RTST_R : 30|1@0+ (1,0) [0|0] "-"  CDC
 SG_ RR_FST : 29|2@0+ (1,0) [0|0] "-"  CDC
 SG_ RL_FST : 27|2@0+ (1,0) [0|0] "-"  CDC
 SG_ RR_OPST : 25|2@0+ (1,0) [0|0] "-"  CDC
 SG_ RL_OPST : 39|2@0+ (1,0) [0|0] "-"  CDC
 SG_ RR_STM1 : 37|3@0+ (1,0) [0|0] "-"  CDC
 SG_ RL_STM1 : 34|3@0+ (1,0) [0|0] "-"  CDC
 SG_ SEAR_ST1 : 46|2@0+ (1,0) [0|0] "-"  CDC
 SG_ SEAR_ST2 : 44|2@0+ (1,0) [0|0] "-"  CDC
 SG_ SEAT_AR : 42|3@0+ (1,0) [0|0] "-"  CDC
 SG_ WIR_ST : 55|2@0+ (1,0) [0|0] "-"  CDC
 SG_ WIR_OPST : 53|2@0+ (1,0) [0|0] "-"  CDC
 SG_ WIL_ST : 51|2@0+ (1,0) [0|0] "-"  CDC
 SG_ WIL_OPST : 49|2@0+ (1,0) [0|0] "-"  CDC
 SG_ FOR_ST : 63|2@0+ (1,0) [0|0] "-"  CDC
 SG_ FOR_OPST : 61|2@0+ (1,0) [0|0] "-"  CDC
 SG_ FOL_ST : 59|2@0+ (1,0) [0|0] "-"  CDC
 SG_ FOL_OPST : 57|2@0+ (1,0) [0|0] "-"  CDC

BO_ 1081 SCN1S01: 8 BDL
 SG_ DRVCLS : 23|3@0+ (1,0) [0|0] "-"  CDC,DDM

BO_ 885 SCN1S02: 8 BDL
 SG_ PARK_S : 15|6@0+ (1,0) [0|0] "-"  CDC,DDM

BO_ 765 SCS1S11: 32 DDM
 SG_ ASCEXT : 7|3@0+ (1,0) [0|0] "-"  CDC
 SG_ ASCMINF : 3|4@0+ (1,0) [0|0] "-"  CDC
 SG_ ASCVFST : 15|2@0+ (1,0) [0|0] "-"  CDC
 SG_ ASCVHIST : 13|3@0+ (1,0) [0|0] "-"  CDC
 SG_ ASCVHCST : 9|2@0+ (1,0) [0|0] "-"  CDC
 SG_ ASCUPST : 23|2@0+ (1,0) [0|0] "-"  CDC
 SG_ ASCDNST : 21|2@0+ (1,0) [0|0] "-"  CDC
 SG_ ASCOFFST : 19|2@0+ (1,0) [0|0] "-"  CDC
 SG_ ASCMST : 17|2@0+ (1,0) [0|0] "-"  CDC
 SG_ B_LSUS10 : 31|2@0+ (1,0) [0|0] "-"  CDC
 SG_ B_LSUS18 : 29|2@0+ (1,0) [0|0] "-"  CDC
 SG_ LFTIND : 25|2@0+ (1,0) [0|0] "-"  CDC
 SG_ ASCCUSF : 39|1@0+ (1,0) [0|0] "-"  CDC
 SG_ ASCCUS : 38|2@0+ (1,0) [0|0] "-"  CDC
 SG_ ASCSTPF1 : 36|1@0+ (1,0) [0|0] "-"  CDC
 SG_ ASCSTOP1 : 35|1@0+ (1,0) [0|0] "-"  CDC
 SG_ ASCSTPF2 : 34|1@0+ (1,0) [0|0] "-"  CDC
 SG_ ASCSTOP2 : 33|1@0+ (1,0) [0|0] "-"  CDC
 SG_ REGSELRQ : 54|3@0+ (1,0) [0|0] "-"  CDC
 SG_ GPSSWRQ : 51|1@0+ (1,0) [0|0] "-"  CDC
 SG_ GPSCHGRQ : 50|1@0+ (1,0) [0|0] "-"  CDC
 SG_ ALLDELRQ : 49|2@0+ (1,0) [0|0] "-"  CDC
 SG_ VHUPSWST : 71|2@0+ (1,0) [0|0] "-"  CDC
 SG_ VHDWSWST : 69|2@0+ (1,0) [0|0] "-"  CDC
 SG_ MASWRQ : 67|1@0+ (1,0) [0|0] "-"  CDC
 SG_ MASWST : 66|2@0+ (1,0) [0|0] "-"  CDC
 SG_ HCOPMEXT : 64|1@0+ (1,0) [0|0] "-"  CDC
 SG_ METFSIRQ : 79|1@0+ (1,0) [0|0] "-"  CDC
 SG_ VHDFSINF : 78|3@0+ (1,0) [0|0] "-"  CDC
 SG_ VHSMINF : 74|3@0+ (1,0) [0|0] "-"  CDC
 SG_ VHSVINF : 87|8@0- (1,0) [0|0] "mm"  CDC
 SG_ VEVWDTYP : 95|2@0+ (1,0) [0|0] "-"  CDC
 SG_ HCOPSD : 93|2@0+ (1,0) [0|0] "-"  CDC
 SG_ CPUPMDRQ : 91|4@0+ (1,0) [0|0] "-"  CDC

BO_ 1036 SOL1S02: 8 BDL
 SG_ SOLGN : 15|11@0+ (1,0) [0|0] "W"  BGW,CDC
 SG_ SOLSCL : 20|4@0+ (1,0) [0|0] "-"  BGW,CDC
 SG_ SOLFAIL : 16|1@0+ (1,0) [0|0] "-"  BGW,CDC
 SG_ SOLCST : 39|2@0+ (1,0) [0|0] "-"  BGW,CDC
 SG_ SOLTREV2 : 37|14@0+ (0.1,0) [0|0] "km"  BGW,CDC
 SG_ SOL : 55|1@0+ (1,0) [0|0] "-"  BGW,CDC
 SG_ SOLRT : 52|3@0+ (1,0) [0|0] "-"  BGW,CDC

BO_ 1037 SOL1S03: 8 BDL
 SG_ SOLAGN : 7|32@0+ (1,0) [0|0] "Wh"  BGW,CDC
 SG_ SOLEV : 39|32@0+ (0.1,0) [0|0] "km"  BGW,CDC

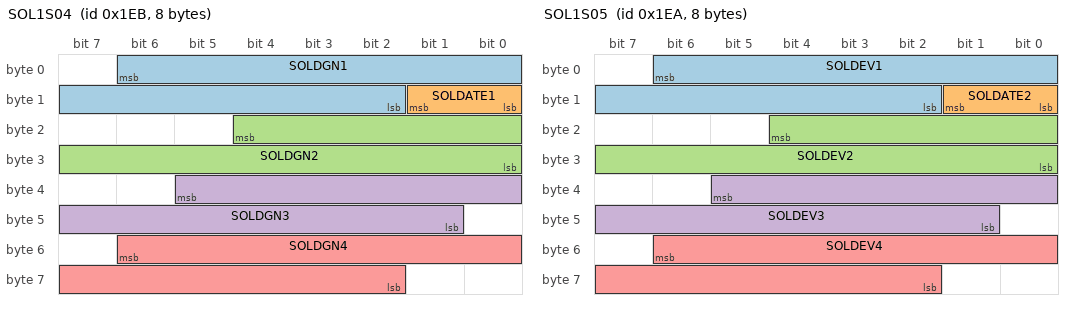
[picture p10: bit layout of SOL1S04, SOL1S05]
BO_ 491 SOL1S04: 8 BDL
 SG_ SOLDGN1 : 6|13@0+ (1,0) [0|0] "Wh"  BGW,CDC
 SG_ SOLDATE1 : 9|2@0+ (1,0) [0|0] "-"  BGW,CDC
 SG_ SOLDGN2 : 20|13@0+ (1,0) [0|0] "Wh"  BGW,CDC
 SG_ SOLDGN3 : 37|13@0+ (1,0) [0|0] "Wh"  BGW,CDC
 SG_ SOLDGN4 : 54|13@0+ (1,0) [0|0] "Wh"  BGW,CDC

BO_ 490 SOL1S05: 8 BDL
 SG_ SOLDEV1 : 6|13@0+ (0.1,0) [0|0] "km"  BGW,CDC
 SG_ SOLDATE2 : 9|2@0+ (1,0) [0|0] "-"  BGW,CDC
 SG_ SOLDEV2 : 20|13@0+ (0.1,0) [0|0] "km"  BGW,CDC
 SG_ SOLDEV3 : 37|13@0+ (0.1,0) [0|0] "km"  BGW,CDC
 SG_ SOLDEV4 : 54|13@0+ (0.1,0) [0|0] "km"  BGW,CDC

BO_ 443 SOL1S06: 8 BDL
 SG_ SOLRT2 : 7|7@0+ (1,0) [0|0] "%"  CDC

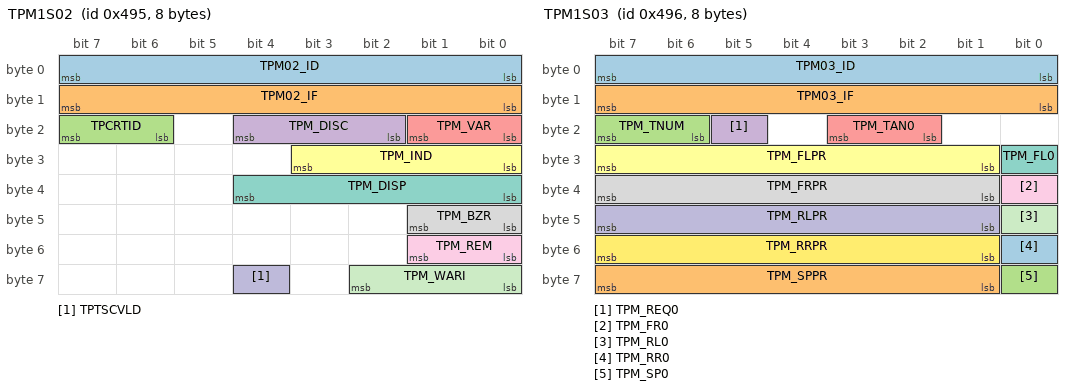
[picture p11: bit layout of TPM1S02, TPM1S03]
BO_ 1173 TPM1S02: 8 BDL
 SG_ TPM02_ID : 7|8@0+ (1,0) [0|0] "-"  CDC,DDM
 SG_ TPM02_IF : 15|8@0+ (1,0) [0|0] "-"  CDC,DDM
 SG_ TPCRTID : 23|2@0+ (1,0) [0|0] "-"  CDC,DDM
 SG_ TPM_DISC : 20|3@0+ (1,0) [0|0] "-"  CDC,DDM
 SG_ TPM_VAR : 17|2@0+ (1,0) [0|0] "-"  CDC,DDM
 SG_ TPM_IND : 27|4@0+ (1,0) [0|0] "-"  CDC,DDM
 SG_ TPM_DISP : 36|5@0+ (1,0) [0|0] "-"  CDC,DDM
 SG_ TPM_BZR : 41|2@0+ (1,0) [0|0] "-"  CDC,DDM
 SG_ TPM_REM : 49|2@0+ (1,0) [0|0] "-"  CDC,DDM
 SG_ TPTSCVLD : 60|1@0+ (1,0) [0|0] "-"  CDC,DDM
 SG_ TPM_WARI : 58|3@0+ (1,0) [0|0] "-"  CDC,DDM

BO_ 1174 TPM1S03: 8 BDL
 SG_ TPM03_ID : 7|8@0+ (1,0) [0|0] "-"  BGW,CDC
 SG_ TPM03_IF : 15|8@0+ (1,0) [0|0] "-"  BGW,CDC
 SG_ TPM_TNUM : 23|2@0+ (1,0) [0|0] "-"  BGW,CDC
 SG_ TPM_REQ0 : 21|1@0+ (1,0) [0|0] "-"  BGW,CDC
 SG_ TPM_TAN0 : 19|2@0+ (1,0) [0|0] "-"  BGW,CDC
 SG_ TPM_FLPR : 31|7@0+ (1,0) [0|0] "kpa/psi/bar"  BGW,CDC
 SG_ TPM_FL0 : 24|1@0+ (1,0) [0|0] "-"  BGW,CDC
 SG_ TPM_FRPR : 39|7@0+ (1,0) [0|0] "kpa/psi/bar"  BGW,CDC
 SG_ TPM_FR0 : 32|1@0+ (1,0) [0|0] "-"  BGW,CDC
 SG_ TPM_RLPR : 47|7@0+ (1,0) [0|0] "kpa/psi/bar"  BGW,CDC
 SG_ TPM_RL0 : 40|1@0+ (1,0) [0|0] "-"  BGW,CDC
 SG_ TPM_RRPR : 55|7@0+ (1,0) [0|0] "kpa/psi/bar"  BGW,CDC
 SG_ TPM_RR0 : 48|1@0+ (1,0) [0|0] "-"  BGW,CDC
 SG_ TPM_SPPR : 63|7@0+ (1,0) [0|0] "kpa/psi/bar"  BGW,CDC
 SG_ TPM_SP0 : 56|1@0+ (1,0) [0|0] "-"  BGW,CDC

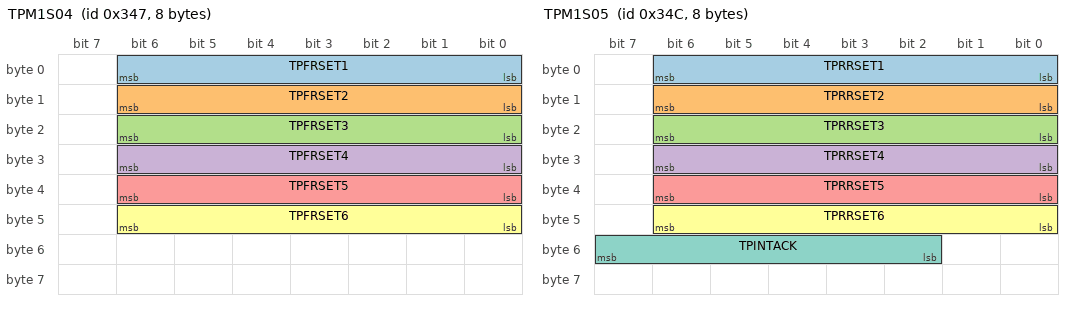
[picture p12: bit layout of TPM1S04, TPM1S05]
BO_ 839 TPM1S04: 8 BDL
 SG_ TPFRSET1 : 6|7@0+ (1,0) [0|0] "-"  CDC
 SG_ TPFRSET2 : 14|7@0+ (1,0) [0|0] "-"  CDC
 SG_ TPFRSET3 : 22|7@0+ (1,0) [0|0] "-"  CDC
 SG_ TPFRSET4 : 30|7@0+ (1,0) [0|0] "-"  CDC
 SG_ TPFRSET5 : 38|7@0+ (1,0) [0|0] "-"  CDC
 SG_ TPFRSET6 : 46|7@0+ (1,0) [0|0] "-"  CDC

BO_ 844 TPM1S05: 8 BDL
 SG_ TPRRSET1 : 6|7@0+ (1,0) [0|0] "-"  CDC
 SG_ TPRRSET2 : 14|7@0+ (1,0) [0|0] "-"  CDC
 SG_ TPRRSET3 : 22|7@0+ (1,0) [0|0] "-"  CDC
 SG_ TPRRSET4 : 30|7@0+ (1,0) [0|0] "-"  CDC
 SG_ TPRRSET5 : 38|7@0+ (1,0) [0|0] "-"  CDC
 SG_ TPRRSET6 : 46|7@0+ (1,0) [0|0] "-"  CDC
 SG_ TPINTACK : 55|6@0+ (1,0) [0|0] "-"  CDC

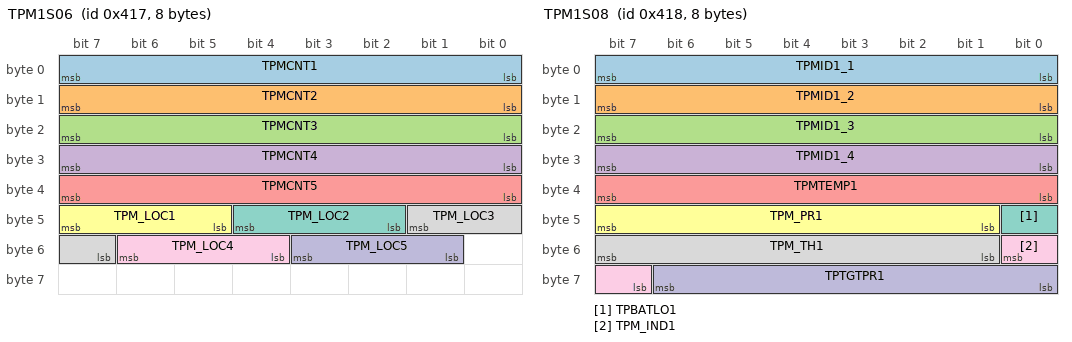
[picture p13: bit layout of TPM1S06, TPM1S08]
BO_ 1047 TPM1S06: 8 BDL
 SG_ TPMCNT1 : 7|8@0+ (1,0) [0|0] "-"  CDC
 SG_ TPMCNT2 : 15|8@0+ (1,0) [0|0] "-"  CDC
 SG_ TPMCNT3 : 23|8@0+ (1,0) [0|0] "-"  CDC
 SG_ TPMCNT4 : 31|8@0+ (1,0) [0|0] "-"  CDC
 SG_ TPMCNT5 : 39|8@0+ (1,0) [0|0] "-"  CDC
 SG_ TPM_LOC1 : 47|3@0+ (1,0) [0|0] "-"  CDC
 SG_ TPM_LOC2 : 44|3@0+ (1,0) [0|0] "-"  CDC
 SG_ TPM_LOC3 : 41|3@0+ (1,0) [0|0] "-"  CDC
 SG_ TPM_LOC4 : 54|3@0+ (1,0) [0|0] "-"  CDC
 SG_ TPM_LOC5 : 51|3@0+ (1,0) [0|0] "-"  CDC

BO_ 879 TPM1S07: 8 BDL
 SG_ TPTEMPFL : 7|8@0+ (1,-40) [0|0] "-"  CDC
 SG_ TPTEMPFR : 15|8@0+ (1,-40) [0|0] "-"  CDC
 SG_ TPTEMPRL : 23|8@0+ (1,-40) [0|0] "-"  CDC
 SG_ TPTEMPRR : 31|8@0+ (1,-40) [0|0] "-"  CDC
 SG_ TPTEMPSP : 39|8@0+ (1,-40) [0|0] "-"  CDC

BO_ 1048 TPM1S08: 8 BDL
 SG_ TPMID1_1 : 7|8@0+ (1,0) [0|0] "-"  CDC
 SG_ TPMID1_2 : 15|8@0+ (1,0) [0|0] "-"  CDC
 SG_ TPMID1_3 : 23|8@0+ (1,0) [0|0] "-"  CDC
 SG_ TPMID1_4 : 31|8@0+ (1,0) [0|0] "-"  CDC
 SG_ TPMTEMP1 : 39|8@0+ (1,-40) [0|0] "-"  CDC
 SG_ TPM_PR1 : 47|7@0+ (1,0) [0|0] "kpa/psi/bar"  CDC
 SG_ TPBATLO1 : 40|1@0+ (1,0) [0|0] "-"  CDC
 SG_ TPM_TH1 : 55|7@0+ (1,0) [0|0] "kpa/psi/bar"  CDC
 SG_ TPM_IND1 : 48|2@0+ (1,0) [0|0] "-"  CDC
 SG_ TPTGTPR1 : 62|7@0+ (1,0) [0|0] "kpa/psi/bar"  CDC

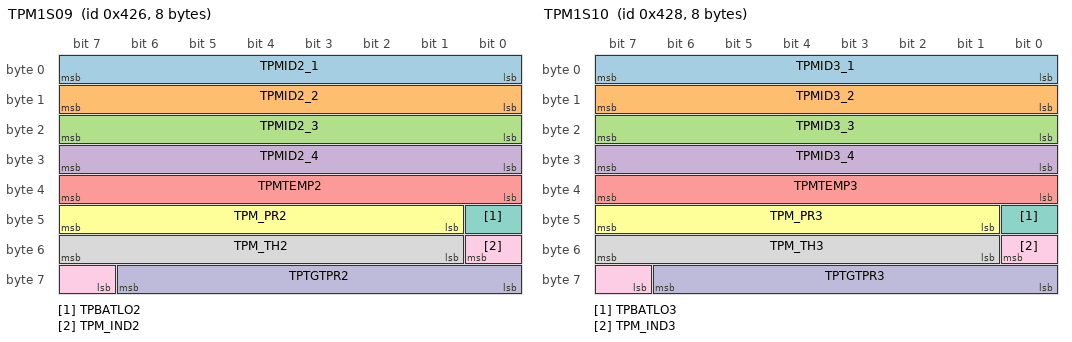
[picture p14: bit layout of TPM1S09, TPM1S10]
BO_ 1062 TPM1S09: 8 BDL
 SG_ TPMID2_1 : 7|8@0+ (1,0) [0|0] "-"  CDC
 SG_ TPMID2_2 : 15|8@0+ (1,0) [0|0] "-"  CDC
 SG_ TPMID2_3 : 23|8@0+ (1,0) [0|0] "-"  CDC
 SG_ TPMID2_4 : 31|8@0+ (1,0) [0|0] "-"  CDC
 SG_ TPMTEMP2 : 39|8@0+ (1,-40) [0|0] "-"  CDC
 SG_ TPM_PR2 : 47|7@0+ (1,0) [0|0] "kpa/psi/bar"  CDC
 SG_ TPBATLO2 : 40|1@0+ (1,0) [0|0] "-"  CDC
 SG_ TPM_TH2 : 55|7@0+ (1,0) [0|0] "kpa/psi/bar"  CDC
 SG_ TPM_IND2 : 48|2@0+ (1,0) [0|0] "-"  CDC
 SG_ TPTGTPR2 : 62|7@0+ (1,0) [0|0] "kpa/psi/bar"  CDC

BO_ 1064 TPM1S10: 8 BDL
 SG_ TPMID3_1 : 7|8@0+ (1,0) [0|0] "-"  CDC
 SG_ TPMID3_2 : 15|8@0+ (1,0) [0|0] "-"  CDC
 SG_ TPMID3_3 : 23|8@0+ (1,0) [0|0] "-"  CDC
 SG_ TPMID3_4 : 31|8@0+ (1,0) [0|0] "-"  CDC
 SG_ TPMTEMP3 : 39|8@0+ (1,-40) [0|0] "-"  CDC
 SG_ TPM_PR3 : 47|7@0+ (1,0) [0|0] "kpa/psi/bar"  CDC
 SG_ TPBATLO3 : 40|1@0+ (1,0) [0|0] "-"  CDC
 SG_ TPM_TH3 : 55|7@0+ (1,0) [0|0] "kpa/psi/bar"  CDC
 SG_ TPM_IND3 : 48|2@0+ (1,0) [0|0] "-"  CDC
 SG_ TPTGTPR3 : 62|7@0+ (1,0) [0|0] "kpa/psi/bar"  CDC

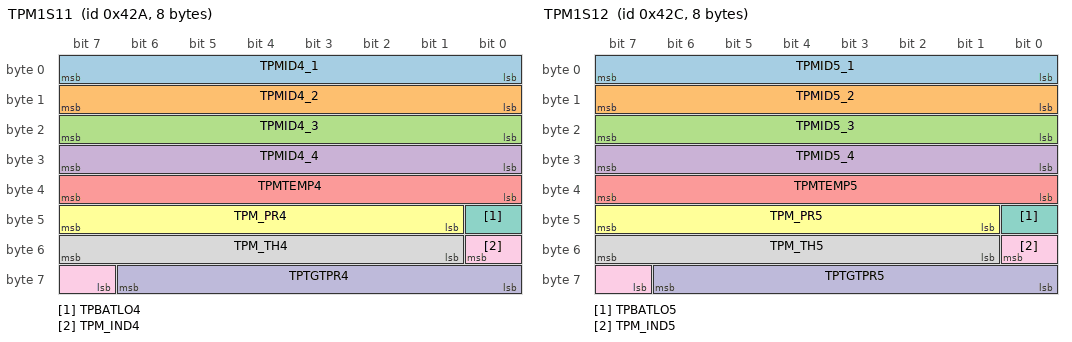
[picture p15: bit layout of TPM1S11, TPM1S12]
BO_ 1066 TPM1S11: 8 BDL
 SG_ TPMID4_1 : 7|8@0+ (1,0) [0|0] "-"  CDC
 SG_ TPMID4_2 : 15|8@0+ (1,0) [0|0] "-"  CDC
 SG_ TPMID4_3 : 23|8@0+ (1,0) [0|0] "-"  CDC
 SG_ TPMID4_4 : 31|8@0+ (1,0) [0|0] "-"  CDC
 SG_ TPMTEMP4 : 39|8@0+ (1,-40) [0|0] "-"  CDC
 SG_ TPM_PR4 : 47|7@0+ (1,0) [0|0] "kpa/psi/bar"  CDC
 SG_ TPBATLO4 : 40|1@0+ (1,0) [0|0] "-"  CDC
 SG_ TPM_TH4 : 55|7@0+ (1,0) [0|0] "kpa/psi/bar"  CDC
 SG_ TPM_IND4 : 48|2@0+ (1,0) [0|0] "-"  CDC
 SG_ TPTGTPR4 : 62|7@0+ (1,0) [0|0] "kpa/psi/bar"  CDC

BO_ 1068 TPM1S12: 8 BDL
 SG_ TPMID5_1 : 7|8@0+ (1,0) [0|0] "-"  CDC
 SG_ TPMID5_2 : 15|8@0+ (1,0) [0|0] "-"  CDC
 SG_ TPMID5_3 : 23|8@0+ (1,0) [0|0] "-"  CDC
 SG_ TPMID5_4 : 31|8@0+ (1,0) [0|0] "-"  CDC
 SG_ TPMTEMP5 : 39|8@0+ (1,-40) [0|0] "-"  CDC
 SG_ TPM_PR5 : 47|7@0+ (1,0) [0|0] "kpa/psi/bar"  CDC
 SG_ TPBATLO5 : 40|1@0+ (1,0) [0|0] "-"  CDC
 SG_ TPM_TH5 : 55|7@0+ (1,0) [0|0] "kpa/psi/bar"  CDC
 SG_ TPM_IND5 : 48|2@0+ (1,0) [0|0] "-"  CDC
 SG_ TPTGTPR5 : 62|7@0+ (1,0) [0|0] "kpa/psi/bar"  CDC

BO_ 999 UCB1S01: 32 BDL
 SG_ SPDL_SR : 23|1@0+ (1,0) [0|0] "-"  CDC
 SG_ SPDL_MR : 22|1@0+ (1,0) [0|0] "-"  CDC
 SG_ SFTL_SR : 21|1@0+ (1,0) [0|0] "-"  CDC
 SG_ SFTL_MR : 20|1@0+ (1,0) [0|0] "-"  CDC
 SG_ DOUL_SR : 17|1@0+ (1,0) [0|0] "-"  CDC
 SG_ DOUL_MR : 16|1@0+ (1,0) [0|0] "-"  CDC
 SG_ A_L_SR : 31|1@0+ (1,0) [0|0] "-"  CDC
 SG_ A_L_MR : 30|2@0+ (1,0) [0|0] "-"  CDC
 SG_ A_UL_SR : 28|1@0+ (1,0) [0|0] "-"  CDC
 SG_ A_UL_MR : 27|2@0+ (1,0) [0|0] "-"  CDC
 SG_ R2PUL_SR : 25|1@0+ (1,0) [0|0] "-"  CDC
 SG_ R2PUL_MR : 24|1@0+ (1,0) [0|0] "-"  CDC
 SG_ WLDO_SR : 39|1@0+ (1,0) [0|0] "-"  CDC
 SG_ WLDO_MR : 38|1@0+ (1,0) [0|0] "-"  CDC
 SG_ LU_FL_SR : 37|1@0+ (1,0) [0|0] "-"  CDC
 SG_ LU_FL_MR : 36|1@0+ (1,0) [0|0] "-"  CDC
 SG_ ARL_T_SR : 35|1@0+ (1,0) [0|0] "-"  CDC
 SG_ ARL_T_MR : 34|3@0+ (1,0) [0|0] "-"  CDC
 SG_ LU_FT_SR : 47|1@0+ (1,0) [0|0] "-"  CDC
 SG_ LU_FT_MR : 46|3@0+ (1,0) [0|0] "-"  CDC
 SG_ SDU_SR : 43|1@0+ (1,0) [0|0] "-"  CDC
 SG_ SDU_MR : 42|2@0+ (1,0) [0|0] "-"  CDC
 SG_ SESS_SR : 40|1@0+ (1,0) [0|0] "-"  CDC
 SG_ SESS_MR : 55|1@0+ (1,0) [0|0] "-"  CDC
 SG_ LSS_SR : 54|1@0+ (1,0) [0|0] "-"  CDC
 SG_ LSS_MR : 53|3@0+ (1,0) [0|0] "-"  CDC
 SG_ HL_T_SR : 50|1@0+ (1,0) [0|0] "-"  CDC
 SG_ HL_T_MR : 49|2@0+ (1,0) [0|0] "-"  CDC
 SG_ DRL_SR : 63|1@0+ (1,0) [0|0] "-"  CDC
 SG_ DRL_MR : 62|1@0+ (1,0) [0|0] "-"  CDC
 SG_ IL_T_SR : 61|1@0+ (1,0) [0|0] "-"  CDC
 SG_ IL_T_MR : 60|2@0+ (1,0) [0|0] "-"  CDC
 SG_ TITEC1SR : 71|1@0+ (1,0) [0|0] "-"  CDC
 SG_ TITEC1MR : 70|3@0+ (1,0) [0|0] "-"  CDC
 SG_ DSEE_SR : 67|1@0+ (1,0) [0|0] "-"  CDC
 SG_ DSEE_MR : 66|2@0+ (1,0) [0|0] "-"  CDC
 SG_ PBDOA_SR : 64|1@0+ (1,0) [0|0] "-"  CDC
 SG_ PBDOA_MR : 79|3@0+ (1,0) [0|0] "-"  CDC
 SG_ DSAL_SR : 76|1@0+ (1,0) [0|0] "-"  CDC
 SG_ DSAL_MR : 75|2@0+ (1,0) [0|0] "-"  CDC
 SG_ KPF_SR : 73|1@0+ (1,0) [0|0] "-"  CDC
 SG_ KPF_MR : 72|1@0+ (1,0) [0|0] "-"  CDC
 SG_ TEIAN1SR : 87|1@0+ (1,0) [0|0] "-"  CDC
 SG_ TEIAN1MR : 86|2@0+ (1,0) [0|0] "-"  CDC
 SG_ PSN_SR : 93|1@0+ (1,0) [0|0] "-"  CDC
 SG_ PSN_MR : 92|1@0+ (1,0) [0|0] "-"  CDC
 SG_ SFL_SR : 111|1@0+ (1,0) [0|0] "-"  CDC
 SG_ SFL_MR : 110|3@0+ (1,0) [0|0] "-"  CDC
 SG_ SFR_SR : 107|1@0+ (1,0) [0|0] "-"  CDC
 SG_ SFR_MR : 106|3@0+ (1,0) [0|0] "-"  CDC
 SG_ SHRL_SR : 127|1@0+ (1,0) [0|0] "-"  CDC
 SG_ SHRL_MR : 126|3@0+ (1,0) [0|0] "-"  CDC
 SG_ SHRR_SR : 123|1@0+ (1,0) [0|0] "-"  CDC
 SG_ SHRR_MR : 122|3@0+ (1,0) [0|0] "-"  CDC
 SG_ SWHTS_SR : 139|1@0+ (1,0) [0|0] "-"  CDC
 SG_ SWHTS_MR : 138|3@0+ (1,0) [0|0] "-"  CDC
 SG_ SSS_SR : 151|1@0+ (1,0) [0|0] "-"  CDC
 SG_ SSS_MR : 150|3@0+ (1,0) [0|0] "-"  CDC
 SG_ AACM_SR : 147|1@0+ (1,0) [0|0] "-"  CDC
 SG_ AACM_MR : 146|1@0+ (1,0) [0|0] "-"  CDC
 SG_ EVM_SR : 145|1@0+ (1,0) [0|0] "-"  CDC
 SG_ EVM_MR : 144|1@0+ (1,0) [0|0] "-"  CDC

BO_ 792 VAS1S01: 8 BDF
 SG_ SPWNGMID : 7|1@0+ (1,0) [0|0] "-"  CDC
 SG_ SPWNGTT : 6|1@0+ (1,0) [0|0] "-"  CDC

BO_ 106 VSC1F01: 32 DDM
 SG_ VXFREF : 31|1@0+ (1,0) [0|0] "-"  BGW,CDC
 SG_ VXFR : 30|15@0+ (0.01,-67.67) [0|0] "km/h"  BGW,CDC
 SG_ VXFLEF : 47|1@0+ (1,0) [0|0] "-"  BGW,CDC
 SG_ VXFL : 46|15@0+ (0.01,-67.67) [0|0] "km/h"  BGW,CDC
 SG_ VXRREF : 63|1@0+ (1,0) [0|0] "-"  BGW,CDC
 SG_ VXRR : 62|15@0+ (0.01,-67.67) [0|0] "km/h"  BGW,CDC
 SG_ VXRLEF : 79|1@0+ (1,0) [0|0] "-"  BGW,CDC
 SG_ VXRL : 78|15@0+ (0.01,-67.67) [0|0] "km/h"  BGW,CDC
 SG_ RRDLVL : 159|3@0+ (1,0) [0|0] "-"  BGW,CDC
 SG_ RRD_CRK : 156|5@0+ (1,0) [0|0] "-"  BGW,CDC
 SG_ RRDLVL_D : 167|3@0+ (1,0) [0|0] "-"  BGW,CDC
 SG_ RRD_STP : 164|5@0+ (1,0) [0|0] "-"  BGW,CDC

BO_ 105 VSC1G12: 32 DDM
 SG_ VSC_GXF : 31|1@0+ (1,0) [0|0] "-"  BGW,CDC
 SG_ VSC_GXIV : 30|1@0+ (1,0) [0|0] "-"  BGW,CDC
 SG_ VSC_GYF : 29|1@0+ (1,0) [0|0] "-"  BGW,CDC
 SG_ VSC_GYIV : 28|1@0+ (1,0) [0|0] "-"  BGW,CDC
 SG_ VSC_YAWS : 27|1@0+ (1,0) [0|0] "-"  BGW,CDC
 SG_ VSC_YAWF : 26|1@0+ (1,0) [0|0] "-"  BGW,CDC
 SG_ V_GXHR0 : 39|16@0- (1,0) [0|0] "mG"  BGW,CDC
 SG_ V_GYHR0 : 55|16@0- (1,0) [0|0] "mG"  BGW,CDC
 SG_ V_YR1HR0 : 71|16@0- (0.01,0) [0|0] "deg/sec"  BGW,CDC

BO_ 158 VSC1G13: 32 DDM
 SG_ SP1S : 31|1@0+ (1,0) [0|0] "-"  BGW,CDC
 SG_ GVSPDINV : 30|1@0+ (1,0) [0|0] "-"  CDC
 SG_ SP1P : 29|6@0+ (1,0) [0|0] "-"  BGW,CDC
 SG_ SP1 : 39|16@0+ (0.01,0) [0|0] "km/h"  BGW,CDC
 SG_ GVSPD : 55|16@0+ (0.01,0) [0|0] "km/h"  CDC
 SG_ PWCF : 67|1@0+ (1,0) [0|0] "-"  BGW,CDC
 SG_ PWC : 65|10@0+ (0.02,0) [0|0] "Mpa"  BGW,CDC
 SG_ PWCS : 85|1@0+ (1,0) [0|0] "-"  BGW,CDC
 SG_ PMCF : 84|1@0+ (1,0) [0|0] "-"  BGW,CDC
 SG_ PMCS : 83|1@0+ (1,0) [0|0] "-"  BGW,CDC
 SG_ PMC : 81|10@0+ (0.02,0) [0|0] "Mpa"  BGW,CDC

BO_ 183 VSC1G14: 32 DDM
 SG_ VWPSUMFR : 47|8@0+ (1,0) [0|0] "-"  BGW,CDC
 SG_ VWPSUMFL : 55|8@0+ (1,0) [0|0] "-"  BGW,CDC
 SG_ VWPSUMRR : 63|8@0+ (1,0) [0|0] "-"  BGW,CDC
 SG_ VWPSUMRL : 71|8@0+ (1,0) [0|0] "-"  BGW,CDC
 SG_ ABSOPE : 111|5@0+ (1,0) [0|0] "-"  BGW,CDC
 SG_ TRCOPE : 119|6@0+ (1,0) [0|0] "-"  BGW,CDC
 SG_ VSCACT : 125|1@0+ (1,0) [0|0] "-"  BGW,CDC

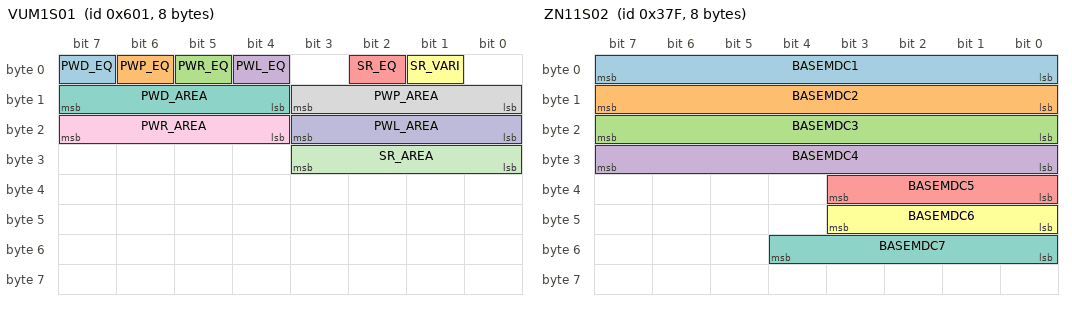
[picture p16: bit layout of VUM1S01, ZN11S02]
BO_ 1537 VUM1S01: 8 BDL
 SG_ PWD_EQ : 7|1@0+ (1,0) [0|0] "-"  BGW,CDC
 SG_ PWP_EQ : 6|1@0+ (1,0) [0|0] "-"  BGW,CDC
 SG_ PWR_EQ : 5|1@0+ (1,0) [0|0] "-"  BGW,CDC
 SG_ PWL_EQ : 4|1@0+ (1,0) [0|0] "-"  BGW,CDC
 SG_ SR_EQ : 2|1@0+ (1,0) [0|0] "-"  BGW,CDC
 SG_ SR_VARI : 1|1@0+ (1,0) [0|0] "-"  BGW,CDC
 SG_ PWD_AREA : 15|4@0+ (1,0) [0|0] "-"  BGW,CDC
 SG_ PWP_AREA : 11|4@0+ (1,0) [0|0] "-"  BGW,CDC
 SG_ PWR_AREA : 23|4@0+ (1,0) [0|0] "-"  BGW,CDC
 SG_ PWL_AREA : 19|4@0+ (1,0) [0|0] "-"  BGW,CDC
 SG_ SR_AREA : 27|4@0+ (1,0) [0|0] "-"  BGW,CDC

BO_ 761 WIP1S01: 8 BDL
 SG_ FRWIPOPE : 7|3@0+ (1,0) [0|0] "-"  CDC
 SG_ FRWASH : 4|1@0+ (1,0) [0|0] "-"  CDC
 SG_ RRWIPOPE : 15|2@0+ (1,0) [0|0] "-"  CDC
 SG_ RRWASH : 13|1@0+ (1,0) [0|0] "-"  CDC

BO_ 638 YGW1S01: 8 BGW
 SG_ YR_KLEG : 16|1@0+ (1,0) [0|0] "-"  CDC

BO_ 895 ZN11S02: 8 BDL
 SG_ BASEMDC1 : 7|8@0+ (1,0) [0|0] "-"  BGW,CDC
 SG_ BASEMDC2 : 15|8@0+ (1,0) [0|0] "-"  BGW,CDC
 SG_ BASEMDC3 : 23|8@0+ (1,0) [0|0] "-"  BGW,CDC
 SG_ BASEMDC4 : 31|8@0+ (1,0) [0|0] "-"  BGW,CDC
 SG_ BASEMDC5 : 35|4@0+ (1,0) [0|0] "-"  BGW,CDC
 SG_ BASEMDC6 : 43|4@0+ (1,0) [0|0] "-"  BGW,CDC
 SG_ BASEMDC7 : 52|5@0+ (1,0) [0|0] "-"  BGW,CDC

BO_ 906 ZN11S03: 8 BDL
 SG_ BODY : 7|8@0+ (1,0) [0|0] "-"  BGW,CDC
 SG_ ENGINE : 15|8@0+ (1,0) [0|0] "-"  BGW,CDC
 SG_ GEAR : 23|8@0+ (1,0) [0|0] "-"  BGW,CDC
 SG_ GRADE : 31|8@0+ (1,0) [0|0] "-"  BGW,CDC
 SG_ POP_NAME : 39|8@0+ (1,0) [0|0] "-"  BGW,CDC

BO_ 134 ZN11S08: 32 BDL
 SG_ W_STPZ : 31|1@0+ (1,0) [0|0] "-"  BGW,CDC
 SG_ FI_STP : 29|1@0+ (1,0) [0|0] "-"  BGW,CDC

BO_ 478 ZN11S14: 8 BDL
 SG_ ADIM2 : 35|2@0+ (1,0) [0|0] "-"  CDC

BO_ 479 ZN11S17: 32 BDL
 SG_ F_STPLP : 7|2@0+ (1,0) [0|0] "-"  BGW,CDC
 SG_ BVWRSW_V : 15|1@0+ (1,0) [0|0] "-"  BGW,CDC
 SG_ BVWRSW : 14|1@0+ (1,0) [0|0] "-"  BGW,CDC
 SG_ BPWRSW_V : 13|1@0+ (1,0) [0|0] "-"  BGW,CDC
 SG_ BPWRSW : 12|1@0+ (1,0) [0|0] "-"  BGW,CDC

BO_ 872 ZN11S19: 32 BDL
 SG_ TITE_FNC : 7|1@0+ (1,0) [0|0] "-"  BGW,CDC
 SG_ TITE_VLD : 6|1@0+ (1,0) [0|0] "-"  BGW,CDC
 SG_ RES_PG : 0|1@0+ (1,0) [0|0] "-"  BGW,CDC
 SG_ HED_FNC : 23|2@0+ (1,0) [0|0] "-"  BGW,CDC
 SG_ TAL_FNC : 21|2@0+ (1,0) [0|0] "-"  BGW,CDC
 SG_ AUT_FNC : 19|2@0+ (1,0) [0|0] "-"  BGW,CDC
 SG_ DRL_FNC : 17|2@0+ (1,0) [0|0] "-"  BGW,CDC
 SG_ OFF_FNC : 31|3@0+ (1,0) [0|0] "-"  BGW,CDC
 SG_ FOG_FNC : 28|2@0+ (1,0) [0|0] "-"  BGW,CDC
 SG_ RFG_FNC : 26|2@0+ (1,0) [0|0] "-"  BGW,CDC
 SG_ HED_EN : 47|2@0+ (1,0) [0|0] "-"  BGW,CDC
 SG_ TAL_EN : 45|2@0+ (1,0) [0|0] "-"  BGW,CDC
 SG_ AUT_EN : 43|2@0+ (1,0) [0|0] "-"  BGW,CDC
 SG_ DRL_EN : 41|2@0+ (1,0) [0|0] "-"  BGW,CDC
 SG_ OFF_EN : 55|2@0+ (1,0) [0|0] "-"  BGW,CDC
 SG_ FOG_EN : 53|2@0+ (1,0) [0|0] "-"  BGW,CDC
 SG_ RFG_EN : 51|2@0+ (1,0) [0|0] "-"  BGW,CDC
 SG_ V_WIPDB : 48|1@0+ (1,0) [0|0] "-"  BGW,CDC
 SG_ LSW_STS : 63|3@0+ (1,0) [0|0] "-"  BGW,CDC
 SG_ FOG_STS : 60|2@0+ (1,0) [0|0] "-"  BGW,CDC
 SG_ RFG_STS : 58|2@0+ (1,0) [0|0] "-"  BGW,CDC
 SG_ V_WIPD : 56|1@0+ (1,0) [0|0] "-"  BGW,CDC
 SG_ PBD_PRE : 71|1@0+ (1,0) [0|0] "-"  BGW,CDC
 SG_ PBDOPPOS : 70|2@0+ (1,0) [0|0] "-"  BGW,CDC
 SG_ PBD_STS : 68|2@0+ (1,0) [0|0] "-"  BGW,CDC
 SG_ PWL_PRE : 66|1@0+ (1,0) [0|0] "-"  BGW,CDC
 SG_ PWL_VLD : 65|1@0+ (1,0) [0|0] "-"  BGW,CDC
 SG_ PWL_STS : 64|1@0+ (1,0) [0|0] "-"  BGW,CDC
 SG_ PBD_VLD : 79|8@0+ (1,0) [0|0] "-"  BGW,CDC
 SG_ WSVS_FNC : 87|1@0+ (1,0) [0|0] "-"  BGW,CDC
 SG_ WSVS_VLD : 86|1@0+ (1,0) [0|0] "-"  BGW,CDC
 SG_ WSVS_STS : 85|1@0+ (1,0) [0|0] "-"  BGW,CDC
 SG_ M_FNC : 84|1@0+ (1,0) [0|0] "-"  BGW,CDC
 SG_ M_VLD : 83|1@0+ (1,0) [0|0] "-"  BGW,CDC
 SG_ MLR_FNC : 82|1@0+ (1,0) [0|0] "-"  BGW,CDC
 SG_ MLR_VLD : 81|1@0+ (1,0) [0|0] "-"  BGW,CDC
 SG_ MLR_STS : 80|1@0+ (1,0) [0|0] "-"  BGW,CDC
 SG_ MRTR_FNC : 94|1@0+ (1,0) [0|0] "-"  BGW,CDC
 SG_ ARTR_FNC : 93|1@0+ (1,0) [0|0] "-"  BGW,CDC
 SG_ MRTR_VLD : 92|1@0+ (1,0) [0|0] "-"  BGW,CDC
 SG_ ARTR_VLD : 91|1@0+ (1,0) [0|0] "-"  BGW,CDC
 SG_ MRTR_STS : 90|2@0+ (1,0) [0|0] "-"  BGW,CDC
 SG_ RLM_FNC : 88|1@0+ (1,0) [0|0] "-"  BGW,CDC
 SG_ RLM_VLD : 103|1@0+ (1,0) [0|0] "-"  BGW,CDC
 SG_ RLM_STS : 102|1@0+ (1,0) [0|0] "-"  BGW,CDC
 SG_ ARTR_STS : 101|2@0+ (1,0) [0|0] "-"  BGW,CDC
 SG_ DRGSNABN : 120|1@0+ (1,0) [0|0] "-"  BGW,CDC
 SG_ RES_PCON : 133|1@0+ (1,0) [0|0] "-"  BGW,CDC
 SG_ SL_MRHTZ : 159|1@0+ (1,0) [0|0] "-"  BGW,CDC
 SG_ RC2OSW : 206|2@0+ (1,0) [0|0] "-"  BGW,CDC
 SG_ CFOSW : 204|2@0+ (1,0) [0|0] "-"  BGW,CDC
 SG_ LTOPE_AD : 202|3@0+ (1,0) [0|0] "-"  BGW,CDC
 SG_ RR2OSW : 215|2@0+ (1,0) [0|0] "-"  BGW,CDC
 SG_ RL3OSW : 213|2@0+ (1,0) [0|0] "-"  BGW,CDC
 SG_ RL2OSW : 211|2@0+ (1,0) [0|0] "-"  BGW,CDC
 SG_ RC3OSW : 209|2@0+ (1,0) [0|0] "-"  BGW,CDC
 SG_ RR3OSW : 217|2@0+ (1,0) [0|0] "-"  BGW,CDC

BO_ 920 ZN11S25: 32 BDL
 SG_ ILEMB_SR : 23|1@0+ (1,0) [0|0] "-"  CDC
 SG_ ILEMB_MR : 22|1@0+ (1,0) [0|0] "-"  CDC
 SG_ SOCHL_SR : 21|1@0+ (1,0) [0|0] "-"  CDC
 SG_ SOCHL_MR : 20|1@0+ (1,0) [0|0] "1"  CDC
 SG_ PSDBV_MR : 78|2@0+ (1,0) [0|0] "-"  CDC
 SG_ PSDBV_SR : 76|1@0+ (1,0) [0|0] "-"  CDC
 SG_ HIDTC_SR : 87|1@0+ (1,0) [0|0] "-"  CDC
 SG_ HIDTC_MR : 86|1@0+ (1,0) [0|0] "-"  CDC
 SG_ HIDLV_SR : 85|1@0+ (1,0) [0|0] "-"  CDC
 SG_ HIDLV_MR : 84|2@0+ (1,0) [0|0] "-"  CDC
 SG_ APULK_MR : 80|1@0+ (1,0) [0|0] "-"  CDC
 SG_ APULK_SR : 95|1@0+ (1,0) [0|0] "-"  CDC
 SG_ DKYSW_MR : 94|1@0+ (1,0) [0|0] "-"  CDC
 SG_ DKYSW_SR : 93|1@0+ (1,0) [0|0] "-"  CDC
 SG_ ILANIA_S : 111|1@0+ (1,0) [0|0] "-"  CDC
 SG_ ILANIA_M : 110|1@0+ (1,0) [0|0] "-"  CDC
 SG_ ILANIB_S : 109|1@0+ (1,0) [0|0] "-"  CDC
 SG_ ILANIB_M : 108|1@0+ (1,0) [0|0] "-"  CDC
 SG_ ILANIC_S : 107|1@0+ (1,0) [0|0] "-"  CDC
 SG_ ILANIC_M : 106|1@0+ (1,0) [0|0] "-"  CDC
 SG_ ILANID_S : 105|1@0+ (1,0) [0|0] "-"  CDC
 SG_ ILANID_M : 104|1@0+ (1,0) [0|0] "-"  CDC
 SG_ ILANIE_S : 119|1@0+ (1,0) [0|0] "-"  CDC
 SG_ ILANIE_M : 118|1@0+ (1,0) [0|0] "-"  CDC
 SG_ ILANIF_S : 117|1@0+ (1,0) [0|0] "-"  CDC
 SG_ ILANIF_M : 116|1@0+ (1,0) [0|0] "-"  CDC
 SG_ PBDHF_MR : 130|1@0+ (1,0) [0|0] "-"  CDC
 SG_ PBDHF_SR : 129|1@0+ (1,0) [0|0] "-"  CDC
 SG_ PBD_MR : 142|1@0+ (1,0) [0|0] "-"  CDC
 SG_ PBD_SR : 141|1@0+ (1,0) [0|0] "-"  CDC
 SG_ PTLHF_MR : 150|1@0+ (1,0) [0|0] "-"  CDC
 SG_ PTLHF_SR : 149|1@0+ (1,0) [0|0] "-"  CDC
 SG_ RSR_MR : 152|1@0+ (1,0) [0|0] "-"  CDC
 SG_ RSR_SR : 167|1@0+ (1,0) [0|0] "-"  CDC
 SG_ SDLHF_MR : 162|1@0+ (1,0) [0|0] "-"  CDC
 SG_ SDLHF_SR : 161|1@0+ (1,0) [0|0] "-"  CDC
 SG_ SDRHF_MR : 160|1@0+ (1,0) [0|0] "-"  CDC
 SG_ SDRHF_SR : 175|1@0+ (1,0) [0|0] "-"  CDC
 SG_ WALK_MR : 196|1@0+ (1,0) [0|0] "-"  CDC
 SG_ WALK_SR : 195|1@0+ (1,0) [0|0] "-"  CDC

BO_ 874 ZN11S26: 32 BDL
 SG_ DM_M_SW : 14|1@0+ (1,0) [0|0] "-"  BGW,CDC,DDM
 SG_ DM_MVLD : 13|1@0+ (1,0) [0|0] "-"  BGW,CDC,DDM
 SG_ DM_P_SW : 12|1@0+ (1,0) [0|0] "-"  BGW,CDC,DDM
 SG_ DM_PVLD : 11|1@0+ (1,0) [0|0] "-"  BGW,CDC,DDM
 SG_ DM_SCVLD : 10|1@0+ (1,0) [0|0] "-"  BGW,CDC
 SG_ PCLMTRCA : 9|2@0+ (1,0) [0|0] "-"  BGW,CDC,DDM
 SG_ WM_STS : 31|3@0+ (1,0) [0|0] "-"  BGW,CDC,DDM
 SG_ WM_TRG : 28|1@0+ (1,0) [0|0] "-"  BGW,CDC,DDM
 SG_ DM_SC_SW : 24|1@0+ (1,0) [0|0] "-"  BGW,CDC
 SG_ WM_DSTS : 39|2@0+ (1,0) [0|0] "-"  BGW,CDC,DDM
 SG_ WVR_FNC : 37|2@0+ (1,0) [0|0] "-"  BGW,CDC,DDM
 SG_ WVR_VLD : 35|1@0+ (1,0) [0|0] "-"  BGW,CDC,DDM
 SG_ WVR_STS : 34|3@0+ (1,0) [0|0] "-"  BGW,CDC,DDM
 SG_ WRSW_FNC : 47|1@0+ (1,0) [0|0] "-"  BGW,CDC,DDM
 SG_ WCSW_FNC : 46|1@0+ (1,0) [0|0] "-"  BGW,CDC,DDM
 SG_ WRSW_VLD : 45|1@0+ (1,0) [0|0] "-"  BGW,CDC,DDM
 SG_ WRSW_STS : 44|1@0+ (1,0) [0|0] "-"  BGW,CDC,DDM
 SG_ WR_FNC : 43|2@0+ (1,0) [0|0] "-"  BGW,CDC,DDM
 SG_ WR_VLD : 41|1@0+ (1,0) [0|0] "-"  BGW,CDC,DDM
 SG_ WDI_FNC : 40|1@0+ (1,0) [0|0] "-"  BGW,CDC,DDM
 SG_ WR_STS : 55|2@0+ (1,0) [0|0] "-"  BGW,CDC,DDM
 SG_ WDI_VLD : 53|1@0+ (1,0) [0|0] "-"  BGW,CDC,DDM
 SG_ WDI_STS : 52|1@0+ (1,0) [0|0] "-"  BGW,CDC,DDM
 SG_ CFBCKL : 71|2@0+ (1,0) [0|0] "-"  BGW,CDC,DDM
 SG_ CR2BCKL : 67|2@0+ (1,0) [0|0] "-"  BGW,CDC,DDM
 SG_ CR3BCKL : 79|2@0+ (1,0) [0|0] "-"  BGW,CDC,DDM
 SG_ DBKLSW : 75|2@0+ (1,0) [0|0] "-"  BGW,CDC,DDM
 SG_ LR2BCKL : 73|2@0+ (1,0) [0|0] "-"  BGW,CDC,DDM
 SG_ LR3BCKL : 85|2@0+ (1,0) [0|0] "-"  BGW,CDC,DDM
 SG_ RR2BCKL : 93|2@0+ (1,0) [0|0] "-"  BGW,CDC,DDM
 SG_ RR3BCKL : 89|2@0+ (1,0) [0|0] "-"  BGW,CDC,DDM
 SG_ REVSW2 : 111|1@0+ (1,0) [0|0] "-"  BGW,CDC,DDM
 SG_ HSW_PVM : 144|1@0+ (1,0) [0|0] "-"  BGW,CDC,DDM

BO_ 924 ZN11S32: 32 BDL
 SG_ RECRNOFF : 7|4@0+ (1,0) [0|0] "-"  BGW,CDC
 SG_ FAV_FNC : 10|2@0+ (1,0) [0|0] "-"  BGW,CDC
 SG_ CHG_FUNC : 8|1@0+ (1,0) [0|0] "-"  BGW,CDC
 SG_ GSNSOFF : 18|1@0+ (1,0) [0|0] "-"  BGW,CDC
 SG_ DRBDBABN : 17|1@0+ (1,0) [0|0] "-"  BGW,CDC

BO_ 1280 ZN11S38: 32 BDL
 SG_ SPT_OPE : 7|3@0+ (1,0) [0|0] "-"  CDC
 SG_ SPTWNG : 4|2@0+ (1,0) [0|0] "-"  CDC

BO_ 878 ZN11S60: 32 BDL
 SG_ BZ_MSEAT : 77|4@0+ (1,0) [0|0] "-"  BGW,CDC
 SG_ KSSFAIL : 82|2@0+ (1,0) [0|0] "-"  BGW,CDC
 SG_ PCLPOSIL : 108|2@0+ (1,0) [0|0] "-"  BGW,CDC
 SG_ PCLPOSIR : 106|2@0+ (1,0) [0|0] "-"  BGW,CDC
 SG_ PCLEQPL : 104|1@0+ (1,0) [0|0] "-"  BGW,CDC
 SG_ PCLEQPR : 119|1@0+ (1,0) [0|0] "-"  BGW,CDC
 SG_ LPCL_CRQ : 166|1@0+ (1,0) [0|0] "-"  BGW,CDC
 SG_ RPCL_CRQ : 165|1@0+ (1,0) [0|0] "-"  BGW,CDC
 SG_ LPCL_ORQ : 164|1@0+ (1,0) [0|0] "-"  BGW,CDC
 SG_ RPCL_ORQ : 163|1@0+ (1,0) [0|0] "-"  BGW,CDC
 SG_ LPCL_OPE : 162|1@0+ (1,0) [0|0] "-"  BGW,CDC
 SG_ RPCL_OPE : 161|1@0+ (1,0) [0|0] "-"  BGW,CDC

BO_ 831 ZN11S63: 32 BDL
 SG_ R_AC_ST : 7|232@0+ (1,0) [0|0] "-"  CDC
 SG_ R_SYS_2 : 239|24@0+ (1,0) [0|0] "-"  CDC

BO_ 978 ZN11S64: 32 BDL
 SG_ R_FTE_ST : 7|112@0+ (1,0) [0|0] "-"  CDC
 SG_ R_BD_ST : 119|72@0+ (1,0) [0|0] "-"  CDC
 SG_ R_TIME : 191|72@0+ (1,0) [0|0] "-"  CDC

BO_ 1017 ZN11S65: 32 BDL
 SG_ R_INT_ST : 7|256@0+ (1,0) [0|0] "-"  CDC

BO_ 1024 ZN11S66: 32 BDL
 SG_ R_LMP_ST : 7|120@0+ (1,0) [0|0] "-"  CDC
 SG_ R_SDE_ST : 127|104@0+ (1,0) [0|0] "-"  CDC
 SG_ R_SYS_3 : 231|32@0+ (1,0) [0|0] "-"  CDC

BO_ 1028 ZN11S67: 32 BDL
 SG_ R_ST_ST : 7|160@0+ (1,0) [0|0] "-"  CDC
 SG_ R_SYS_1 : 167|96@0+ (1,0) [0|0] "-"  CDC

BO_ 963 ZN11SC6: 8 BDL
 SG_ VSI_L8A : 23|8@0+ (1,0) [0|0] "-"  BGW,CDC

BO_ 848 ZN11SF6: 32 BDL
 SG_ EIC_EQP : 7|3@0+ (1,0) [0|0] "-"  CDC
 SG_ EIC_FEQP : 4|1@0+ (1,0) [0|0] "-"  CDC
 SG_ EIC_SEQP : 3|4@0+ (1,0) [0|0] "-"  CDC
 SG_ EIC_IEQP : 15|4@0+ (1,0) [0|0] "-"  CDC
 SG_ EIC_BEQP : 11|1@0+ (1,0) [0|0] "-"  CDC
 SG_ QIC_BREQ : 23|6@0+ (1,0) [0|0] "-"  CDC
 SG_ QIC_DISP : 17|2@0+ (1,0) [0|0] "-"  CDC
 SG_ QIC_BVOL : 31|4@0+ (1,0) [0|0] "-"  CDC
 SG_ QIC_DIS : 27|4@0+ (1,0) [0|0] "-"  CDC
 SG_ EIC_DEQP : 39|1@0+ (1,0) [0|0] "-"  CDC
 SG_ EIC_PEQP : 38|1@0+ (1,0) [0|0] "-"  CDC
 SG_ EIC_REQP : 37|1@0+ (1,0) [0|0] "-"  CDC
 SG_ EIC_LEQP : 36|1@0+ (1,0) [0|0] "-"  CDC
 SG_ AIC_DRC : 71|1@0+ (1,0) [0|0] "-"  CDC
 SG_ AIC_DMRC : 70|1@0+ (1,0) [0|0] "-"  CDC
 SG_ AIC_DFRC : 69|1@0+ (1,0) [0|0] "-"  CDC
 SG_ AIC_DBRC : 68|1@0+ (1,0) [0|0] "-"  CDC
 SG_ AIC_DRRC : 67|1@0+ (1,0) [0|0] "-"  CDC
 SG_ SIC_DMST : 79|3@0+ (1,0) [0|0] "-"  CDC
 SG_ SIC_DCST : 76|3@0+ (1,0) [0|0] "-"  CDC
 SG_ SIC_DFFL : 87|1@0+ (1,0) [0|0] "-"  CDC
 SG_ SIC_DFFP : 86|2@0+ (1,0) [0|0] "-"  CDC
 SG_ SIC_DFRL : 84|1@0+ (1,0) [0|0] "-"  CDC
 SG_ SIC_DFRP : 83|2@0+ (1,0) [0|0] "-"  CDC
 SG_ SIC_DF5L : 81|1@0+ (1,0) [0|0] "-"  CDC
 SG_ SIC_DFDL : 95|1@0+ (1,0) [0|0] "-"  CDC
 SG_ SIC_DFDP : 94|2@0+ (1,0) [0|0] "-"  CDC
 SG_ SIC_DF4L : 92|1@0+ (1,0) [0|0] "-"  CDC
 SG_ SIC_DF4P : 91|2@0+ (1,0) [0|0] "-"  CDC
 SG_ SIC_DF5P : 89|2@0+ (1,0) [0|0] "-"  CDC
 SG_ SIC_DBFL : 103|1@0+ (1,0) [0|0] "-"  CDC
 SG_ SIC_DBFP : 102|2@0+ (1,0) [0|0] "-"  CDC
 SG_ SIC_DBRL : 100|1@0+ (1,0) [0|0] "-"  CDC
 SG_ SIC_DBRP : 99|2@0+ (1,0) [0|0] "-"  CDC
 SG_ SIC_DB5L : 97|1@0+ (1,0) [0|0] "-"  CDC
 SG_ SIC_DBDL : 111|1@0+ (1,0) [0|0] "-"  CDC
 SG_ SIC_DBDP : 110|2@0+ (1,0) [0|0] "-"  CDC
 SG_ SIC_DB4L : 108|1@0+ (1,0) [0|0] "-"  CDC
 SG_ SIC_DB4P : 107|2@0+ (1,0) [0|0] "-"  CDC
 SG_ SIC_DB5P : 105|2@0+ (1,0) [0|0] "-"  CDC
 SG_ SIC_DRFL : 119|1@0+ (1,0) [0|0] "-"  CDC
 SG_ SIC_DRRL : 118|1@0+ (1,0) [0|0] "-"  CDC
 SG_ SIC_DRDL : 117|1@0+ (1,0) [0|0] "-"  CDC
 SG_ SIC_DR4L : 116|1@0+ (1,0) [0|0] "-"  CDC
 SG_ SIC_DR5L : 115|1@0+ (1,0) [0|0] "-"  CDC
 SG_ SIC_DRFK : 127|1@0+ (1,0) [0|0] "-"  CDC
 SG_ SIC_DRRK : 126|1@0+ (1,0) [0|0] "-"  CDC
 SG_ SIC_DRDK : 125|1@0+ (1,0) [0|0] "-"  CDC
 SG_ SIC_DR4K : 124|1@0+ (1,0) [0|0] "-"  CDC
 SG_ SIC_DR5K : 123|1@0+ (1,0) [0|0] "-"  CDC
 SG_ AIC_PRC : 167|1@0+ (1,0) [0|0] "-"  CDC
 SG_ AIC_PMRC : 166|1@0+ (1,0) [0|0] "-"  CDC
 SG_ AIC_PFRC : 165|1@0+ (1,0) [0|0] "-"  CDC
 SG_ AIC_PBRC : 164|1@0+ (1,0) [0|0] "-"  CDC
 SG_ AIC_PRRC : 163|1@0+ (1,0) [0|0] "-"  CDC
 SG_ SIC_PMST : 175|3@0+ (1,0) [0|0] "-"  CDC
 SG_ SIC_PCST : 172|3@0+ (1,0) [0|0] "-"  CDC
 SG_ SIC_PFFL : 183|1@0+ (1,0) [0|0] "-"  CDC
 SG_ SIC_PFFP : 182|2@0+ (1,0) [0|0] "-"  CDC
 SG_ SIC_PFRL : 180|1@0+ (1,0) [0|0] "-"  CDC
 SG_ SIC_PFRP : 179|2@0+ (1,0) [0|0] "-"  CDC
 SG_ SIC_PF5L : 177|1@0+ (1,0) [0|0] "-"  CDC
 SG_ SIC_PFDL : 191|1@0+ (1,0) [0|0] "-"  CDC
 SG_ SIC_PFDP : 190|2@0+ (1,0) [0|0] "-"  CDC
 SG_ SIC_PF4L : 188|1@0+ (1,0) [0|0] "-"  CDC
 SG_ SIC_PF4P : 187|2@0+ (1,0) [0|0] "-"  CDC
 SG_ SIC_PF5P : 185|2@0+ (1,0) [0|0] "-"  CDC
 SG_ SIC_PBFL : 199|1@0+ (1,0) [0|0] "-"  CDC
 SG_ SIC_PBFP : 198|2@0+ (1,0) [0|0] "-"  CDC
 SG_ SIC_PBRL : 196|1@0+ (1,0) [0|0] "-"  CDC
 SG_ SIC_PBRP : 195|2@0+ (1,0) [0|0] "-"  CDC
 SG_ SIC_PB5L : 193|1@0+ (1,0) [0|0] "-"  CDC
 SG_ SIC_PBDL : 207|1@0+ (1,0) [0|0] "-"  CDC
 SG_ SIC_PBDP : 206|2@0+ (1,0) [0|0] "-"  CDC
 SG_ SIC_PB4L : 204|1@0+ (1,0) [0|0] "-"  CDC
 SG_ SIC_PB4P : 203|2@0+ (1,0) [0|0] "-"  CDC
 SG_ SIC_PB5P : 201|2@0+ (1,0) [0|0] "-"  CDC
 SG_ SIC_PRFL : 215|1@0+ (1,0) [0|0] "-"  CDC
 SG_ SIC_PRRL : 214|1@0+ (1,0) [0|0] "-"  CDC
 SG_ SIC_PRDL : 213|1@0+ (1,0) [0|0] "-"  CDC
 SG_ SIC_PR4L : 212|1@0+ (1,0) [0|0] "-"  CDC
 SG_ SIC_PR5L : 211|1@0+ (1,0) [0|0] "-"  CDC
 SG_ SIC_PRFK : 223|1@0+ (1,0) [0|0] "-"  CDC
 SG_ SIC_PRRK : 222|1@0+ (1,0) [0|0] "-"  CDC
 SG_ SIC_PRDK : 221|1@0+ (1,0) [0|0] "-"  CDC
 SG_ SIC_PR4K : 220|1@0+ (1,0) [0|0] "-"  CDC
 SG_ SIC_PR5K : 219|1@0+ (1,0) [0|0] "-"  CDC

BO_ 850 ZN11SF7: 32 BDL
 SG_ AIC_RRC : 7|1@0+ (1,0) [0|0] "-"  CDC
 SG_ AIC_RMRC : 6|1@0+ (1,0) [0|0] "-"  CDC
 SG_ AIC_RFRC : 5|1@0+ (1,0) [0|0] "-"  CDC
 SG_ AIC_RBRC : 4|1@0+ (1,0) [0|0] "-"  CDC
 SG_ AIC_RRRC : 3|1@0+ (1,0) [0|0] "-"  CDC
 SG_ SIC_RMST : 15|3@0+ (1,0) [0|0] "-"  CDC
 SG_ SIC_RCST : 12|3@0+ (1,0) [0|0] "-"  CDC
 SG_ SIC_RFFL : 23|1@0+ (1,0) [0|0] "-"  CDC
 SG_ SIC_RFFP : 22|2@0+ (1,0) [0|0] "-"  CDC
 SG_ SIC_RFRL : 20|1@0+ (1,0) [0|0] "-"  CDC
 SG_ SIC_RFRP : 19|2@0+ (1,0) [0|0] "-"  CDC
 SG_ SIC_RF5L : 17|1@0+ (1,0) [0|0] "-"  CDC
 SG_ SIC_RFDL : 31|1@0+ (1,0) [0|0] "-"  CDC
 SG_ SIC_RFDP : 30|2@0+ (1,0) [0|0] "-"  CDC
 SG_ SIC_RF4L : 28|1@0+ (1,0) [0|0] "-"  CDC
 SG_ SIC_RF4P : 27|2@0+ (1,0) [0|0] "-"  CDC
 SG_ SIC_RF5P : 25|2@0+ (1,0) [0|0] "-"  CDC
 SG_ SIC_RBFL : 39|1@0+ (1,0) [0|0] "-"  CDC
 SG_ SIC_RBFP : 38|2@0+ (1,0) [0|0] "-"  CDC
 SG_ SIC_RBRL : 36|1@0+ (1,0) [0|0] "-"  CDC
 SG_ SIC_RBRP : 35|2@0+ (1,0) [0|0] "-"  CDC
 SG_ SIC_RB5L : 33|1@0+ (1,0) [0|0] "-"  CDC
 SG_ SIC_RBDL : 47|1@0+ (1,0) [0|0] "-"  CDC
 SG_ SIC_RBDP : 46|2@0+ (1,0) [0|0] "-"  CDC
 SG_ SIC_RB4L : 44|1@0+ (1,0) [0|0] "-"  CDC
 SG_ SIC_RB4P : 43|2@0+ (1,0) [0|0] "-"  CDC
 SG_ SIC_RB5P : 41|2@0+ (1,0) [0|0] "-"  CDC
 SG_ SIC_RRFL : 55|1@0+ (1,0) [0|0] "-"  CDC
 SG_ SIC_RRRL : 54|1@0+ (1,0) [0|0] "-"  CDC
 SG_ SIC_RRDL : 53|1@0+ (1,0) [0|0] "-"  CDC
 SG_ SIC_RR4L : 52|1@0+ (1,0) [0|0] "-"  CDC
 SG_ SIC_RR5L : 51|1@0+ (1,0) [0|0] "-"  CDC
 SG_ SIC_RRFK : 63|1@0+ (1,0) [0|0] "-"  CDC
 SG_ SIC_RRRK : 62|1@0+ (1,0) [0|0] "-"  CDC
 SG_ SIC_RRDK : 61|1@0+ (1,0) [0|0] "-"  CDC
 SG_ SIC_RR4K : 60|1@0+ (1,0) [0|0] "-"  CDC
 SG_ SIC_RR5K : 59|1@0+ (1,0) [0|0] "-"  CDC
 SG_ AIC_LRC : 135|1@0+ (1,0) [0|0] "-"  CDC
 SG_ AIC_LMRC : 134|1@0+ (1,0) [0|0] "-"  CDC
 SG_ AIC_LFRC : 133|1@0+ (1,0) [0|0] "-"  CDC
 SG_ AIC_LBRC : 132|1@0+ (1,0) [0|0] "-"  CDC
 SG_ AIC_LRRC : 131|1@0+ (1,0) [0|0] "-"  CDC
 SG_ SIC_LMST : 143|3@0+ (1,0) [0|0] "-"  CDC
 SG_ SIC_LCST : 140|3@0+ (1,0) [0|0] "-"  CDC
 SG_ SIC_LFFL : 151|1@0+ (1,0) [0|0] "-"  CDC
 SG_ SIC_LFFP : 150|2@0+ (1,0) [0|0] "-"  CDC
 SG_ SIC_LFRL : 148|1@0+ (1,0) [0|0] "-"  CDC
 SG_ SIC_LFRP : 147|2@0+ (1,0) [0|0] "-"  CDC
 SG_ SIC_LF5L : 145|1@0+ (1,0) [0|0] "-"  CDC
 SG_ SIC_LFDL : 159|1@0+ (1,0) [0|0] "-"  CDC
 SG_ SIC_LFDP : 158|2@0+ (1,0) [0|0] "-"  CDC
 SG_ SIC_LF4L : 156|1@0+ (1,0) [0|0] "-"  CDC
 SG_ SIC_LF4P : 155|2@0+ (1,0) [0|0] "-"  CDC
 SG_ SIC_LF5P : 153|2@0+ (1,0) [0|0] "-"  CDC
 SG_ SIC_LBFL : 167|1@0+ (1,0) [0|0] "-"  CDC
 SG_ SIC_LBFP : 166|2@0+ (1,0) [0|0] "-"  CDC
 SG_ SIC_LBRL : 164|1@0+ (1,0) [0|0] "-"  CDC
 SG_ SIC_LBRP : 163|2@0+ (1,0) [0|0] "-"  CDC
 SG_ SIC_LB5L : 161|1@0+ (1,0) [0|0] "-"  CDC
 SG_ SIC_LBDL : 175|1@0+ (1,0) [0|0] "-"  CDC
 SG_ SIC_LBDP : 174|2@0+ (1,0) [0|0] "-"  CDC
 SG_ SIC_LB4L : 172|1@0+ (1,0) [0|0] "-"  CDC
 SG_ SIC_LB4P : 171|2@0+ (1,0) [0|0] "-"  CDC
 SG_ SIC_LB5P : 169|2@0+ (1,0) [0|0] "-"  CDC
 SG_ SIC_LRFL : 183|1@0+ (1,0) [0|0] "-"  CDC
 SG_ SIC_LRRL : 182|1@0+ (1,0) [0|0] "-"  CDC
 SG_ SIC_LRDL : 181|1@0+ (1,0) [0|0] "-"  CDC
 SG_ SIC_LR4L : 180|1@0+ (1,0) [0|0] "-"  CDC
 SG_ SIC_LR5L : 179|1@0+ (1,0) [0|0] "-"  CDC
 SG_ SIC_LRFK : 191|1@0+ (1,0) [0|0] "-"  CDC
 SG_ SIC_LRRK : 190|1@0+ (1,0) [0|0] "-"  CDC
 SG_ SIC_LRDK : 189|1@0+ (1,0) [0|0] "-"  CDC
 SG_ SIC_LR4K : 188|1@0+ (1,0) [0|0] "-"  CDC
 SG_ SIC_LR5K : 187|1@0+ (1,0) [0|0] "-"  CDC

BO_ 851 ZN11SF8: 32 BDL
 SG_ ERS_EQP : 7|1@0+ (1,0) [0|0] "-"  CDC
 SG_ ARS_RC : 6|1@0+ (1,0) [0|0] "-"  CDC
 SG_ RDK_FDAC : 5|2@0+ (1,0) [0|0] "-"  CDC
 SG_ RDK_OCAC : 3|2@0+ (1,0) [0|0] "-"  CDC
 SG_ ADK_CHGA : 1|1@0+ (1,0) [0|0] "-"  CDC
 SG_ ADK_FDWA : 0|1@0+ (1,0) [0|0] "-"  CDC
 SG_ ADK_ADLA : 15|1@0+ (1,0) [0|0] "-"  CDC
 SG_ ADK_OWDA : 14|1@0+ (1,0) [0|0] "-"  CDC
 SG_ ADK_OWNA : 13|1@0+ (1,0) [0|0] "-"  CDC
 SG_ ADK_REGA : 12|1@0+ (1,0) [0|0] "-"  CDC
 SG_ ADK_STCA : 11|1@0+ (1,0) [0|0] "-"  CDC
 SG_ EDK_EQP : 10|1@0+ (1,0) [0|0] "-"  CDC
 SG_ RDK_OCRL : 9|2@0+ (1,0) [0|0] "-"  CDC
 SG_ RDK_ADAC : 23|2@0+ (1,0) [0|0] "-"  CDC
 SG_ RDK_ADRL : 21|2@0+ (1,0) [0|0] "-"  CDC
 SG_ RDK_ODAC : 19|2@0+ (1,0) [0|0] "-"  CDC
 SG_ RDK_ODRL : 17|2@0+ (1,0) [0|0] "-"  CDC
 SG_ RDK_OGAC : 31|2@0+ (1,0) [0|0] "-"  CDC
 SG_ RDK_OGRL : 29|2@0+ (1,0) [0|0] "-"  CDC
 SG_ RDK_ORAC : 27|2@0+ (1,0) [0|0] "-"  CDC
 SG_ RDK_ORRL : 25|2@0+ (1,0) [0|0] "-"  CDC
 SG_ RDK_OWAC : 39|2@0+ (1,0) [0|0] "-"  CDC
 SG_ RDK_OWRL : 37|2@0+ (1,0) [0|0] "-"  CDC
 SG_ RDK_RACK : 35|2@0+ (1,0) [0|0] "-"  CDC
 SG_ RDK_CRL : 33|2@0+ (1,0) [0|0] "-"  CDC
 SG_ RSM_CRL : 47|2@0+ (1,0) [0|0] "-"  CDC
 SG_ RSM_LARE : 45|4@0+ (1,0) [0|0] "-"  CDC
 SG_ RSM_LCMN : 41|2@0+ (1,0) [0|0] "-"  CDC
 SG_ RSM_LRNG : 55|2@0+ (1,0) [0|0] "-"  CDC
 SG_ RSM_LTID : 53|4@0+ (1,0) [0|0] "-"  CDC
 SG_ RSM_RACK : 49|2@0+ (1,0) [0|0] "-"  CDC
 SG_ SDK_CNT : 63|1@0+ (1,0) [0|0] "-"  CDC
 SG_ SDK_PRG : 62|3@0+ (1,0) [0|0] "-"  CDC
 SG_ SDK_RGST : 59|2@0+ (1,0) [0|0] "-"  CDC
 SG_ SDK_IDME : 71|16@0+ (1,0) [0|0] "-"  CDC
 SG_ SDK_IDGR : 87|16@0+ (1,0) [0|0] "-"  CDC
 SG_ SDK_IDER : 103|16@0+ (1,0) [0|0] "-"  CDC
 SG_ SLID_RSP : 119|16@0+ (1,0) [0|0] "-"  CDC
 SG_ RDK_LTID : 135|4@0+ (1,0) [0|0] "-"  CDC
 SG_ RDK_LARE : 131|4@0+ (1,0) [0|0] "-"  CDC
 SG_ RDK_LCMN : 143|2@0+ (1,0) [0|0] "-"  CDC
 SG_ RDK_LRNG : 141|2@0+ (1,0) [0|0] "-"  CDC

BO_ 955 ZN11SF9: 32 BDL
 SG_ B_CXJDG1 : 7|2@0+ (1,0) [0|0] "-"  CDC
 SG_ B_VOICES : 5|1@0+ (1,0) [0|0] "-"  CDC
 SG_ B_A_MUTE : 4|1@0+ (1,0) [0|0] "-"  CDC
 SG_ B_VOLDDN : 3|1@0+ (1,0) [0|0] "-"  CDC
 SG_ B_VOLUP : 2|1@0+ (1,0) [0|0] "-"  CDC
 SG_ B_SEEKDN : 1|1@0+ (1,0) [0|0] "-"  CDC
 SG_ B_SEEKUP : 0|1@0+ (1,0) [0|0] "-"  CDC
 SG_ B_VOL_LV : 15|8@0- (1,0) [0|0] "-"  CDC
 SG_ R_PWR : 21|1@0+ (1,0) [0|0] "-"  CDC
 SG_ R_MODE_A : 20|1@0+ (1,0) [0|0] "-"  CDC
 SG_ R_VOLUP : 19|1@0+ (1,0) [0|0] "-"  CDC
 SG_ R_VOLDN : 18|1@0+ (1,0) [0|0] "-"  CDC
 SG_ R_TUNEUP : 17|1@0+ (1,0) [0|0] "-"  CDC
 SG_ R_TUNEDN : 16|1@0+ (1,0) [0|0] "-"  CDC
 SG_ R_CHUP : 31|1@0+ (1,0) [0|0] "-"  CDC
 SG_ R_CHDN : 30|1@0+ (1,0) [0|0] "-"  CDC
 SG_ R_EXIST : 29|1@0+ (1,0) [0|0] "-"  CDC

BO_ 481 ZN21S05: 32 BDL
 SG_ TNLS : 7|2@0+ (1,0) [0|0] "-"  BGW,CDC
 SG_ TNLCOND : 9|2@0+ (1,0) [0|0] "-"  BGW,CDC

BO_ 912 ZN21S13: 8 BDF
 SG_ ACN_AMB : 31|8@0+ (1,0) [0|0] "degC"  BGW,CDC
 SG_ AC_AMB05 : 37|1@0+ (1,0) [0|0] "degC"  BGW,CDC,DDM

BO_ 446 ZN21S28: 32 BDF
 SG_ AMBDS : 31|8@0+ (0.5,-40) [0|0] "degC"  BGW,CDC,DDM

BO_ 937 ZN21S72: 32 BDL
 SG_ TNS : 35|2@0+ (1,0) [0|0] "-"  BGW,CDC,DDM
 SG_ HZS : 33|1@0+ (1,0) [0|0] "-"  BGW,CDC,DDM
 SG_ BAONUSER : 32|1@0+ (1,0) [0|0] "-"  BGW,CDC,DDM

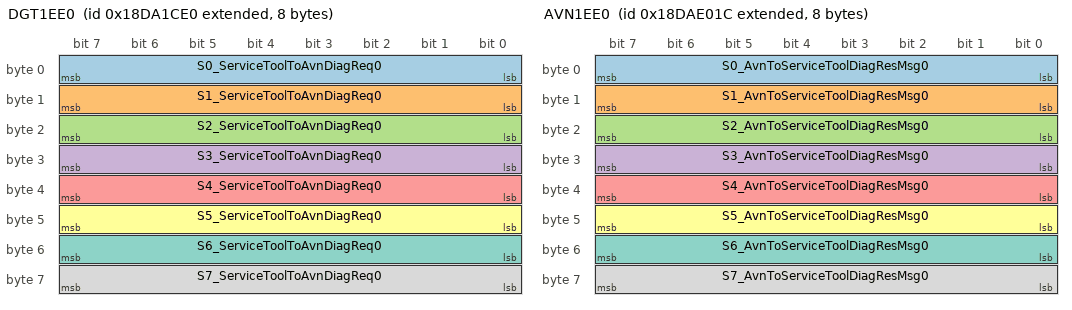
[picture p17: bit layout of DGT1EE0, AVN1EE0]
BO_ 2564431072 DGT1EE0: 8 Vector_XXX
 SG_ S0_ServiceToolToAvnDiagReq0 : 7|8@0+ (1,0) [0|0] "-"  CDC
 SG_ S1_ServiceToolToAvnDiagReq0 : 15|8@0+ (1,0) [0|0] "-"  CDC
 SG_ S2_ServiceToolToAvnDiagReq0 : 23|8@0+ (1,0) [0|0] "-"  CDC
 SG_ S3_ServiceToolToAvnDiagReq0 : 31|8@0+ (1,0) [0|0] "-"  CDC
 SG_ S4_ServiceToolToAvnDiagReq0 : 39|8@0+ (1,0) [0|0] "-"  CDC
 SG_ S5_ServiceToolToAvnDiagReq0 : 47|8@0+ (1,0) [0|0] "-"  CDC
 SG_ S6_ServiceToolToAvnDiagReq0 : 55|8@0+ (1,0) [0|0] "-"  CDC
 SG_ S7_ServiceToolToAvnDiagReq0 : 63|8@0+ (1,0) [0|0] "-"  CDC

BO_ 2564481052 AVN1EE0: 8 CDC
 SG_ S0_AvnToServiceToolDiagResMsg0 : 7|8@0+ (1,0) [0|0] "-"  Vector_XXX
 SG_ S1_AvnToServiceToolDiagResMsg0 : 15|8@0+ (1,0) [0|0] "-"  Vector_XXX
 SG_ S2_AvnToServiceToolDiagResMsg0 : 23|8@0+ (1,0) [0|0] "-"  Vector_XXX
 SG_ S3_AvnToServiceToolDiagResMsg0 : 31|8@0+ (1,0) [0|0] "-"  Vector_XXX
 SG_ S4_AvnToServiceToolDiagResMsg0 : 39|8@0+ (1,0) [0|0] "-"  Vector_XXX
 SG_ S5_AvnToServiceToolDiagResMsg0 : 47|8@0+ (1,0) [0|0] "-"  Vector_XXX
 SG_ S6_AvnToServiceToolDiagResMsg0 : 55|8@0+ (1,0) [0|0] "-"  Vector_XXX
 SG_ S7_AvnToServiceToolDiagResMsg0 : 63|8@0+ (1,0) [0|0] "-"  Vector_XXX

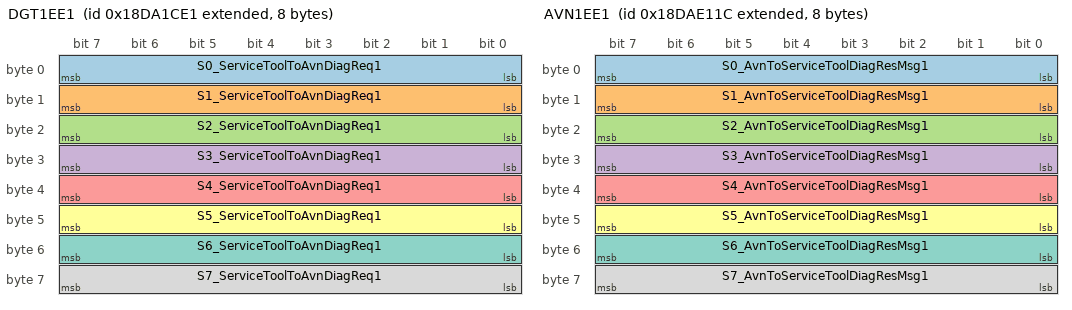
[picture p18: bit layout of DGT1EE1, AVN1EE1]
BO_ 2564431073 DGT1EE1: 8 Vector_XXX
 SG_ S0_ServiceToolToAvnDiagReq1 : 7|8@0+ (1,0) [0|0] "-"  CDC
 SG_ S1_ServiceToolToAvnDiagReq1 : 15|8@0+ (1,0) [0|0] "-"  CDC
 SG_ S2_ServiceToolToAvnDiagReq1 : 23|8@0+ (1,0) [0|0] "-"  CDC
 SG_ S3_ServiceToolToAvnDiagReq1 : 31|8@0+ (1,0) [0|0] "-"  CDC
 SG_ S4_ServiceToolToAvnDiagReq1 : 39|8@0+ (1,0) [0|0] "-"  CDC
 SG_ S5_ServiceToolToAvnDiagReq1 : 47|8@0+ (1,0) [0|0] "-"  CDC
 SG_ S6_ServiceToolToAvnDiagReq1 : 55|8@0+ (1,0) [0|0] "-"  CDC
 SG_ S7_ServiceToolToAvnDiagReq1 : 63|8@0+ (1,0) [0|0] "-"  CDC

BO_ 2564481308 AVN1EE1: 8 CDC
 SG_ S0_AvnToServiceToolDiagResMsg1 : 7|8@0+ (1,0) [0|0] "-"  Vector_XXX
 SG_ S1_AvnToServiceToolDiagResMsg1 : 15|8@0+ (1,0) [0|0] "-"  Vector_XXX
 SG_ S2_AvnToServiceToolDiagResMsg1 : 23|8@0+ (1,0) [0|0] "-"  Vector_XXX
 SG_ S3_AvnToServiceToolDiagResMsg1 : 31|8@0+ (1,0) [0|0] "-"  Vector_XXX
 SG_ S4_AvnToServiceToolDiagResMsg1 : 39|8@0+ (1,0) [0|0] "-"  Vector_XXX
 SG_ S5_AvnToServiceToolDiagResMsg1 : 47|8@0+ (1,0) [0|0] "-"  Vector_XXX
 SG_ S6_AvnToServiceToolDiagResMsg1 : 55|8@0+ (1,0) [0|0] "-"  Vector_XXX
 SG_ S7_AvnToServiceToolDiagResMsg1 : 63|8@0+ (1,0) [0|0] "-"  Vector_XXX

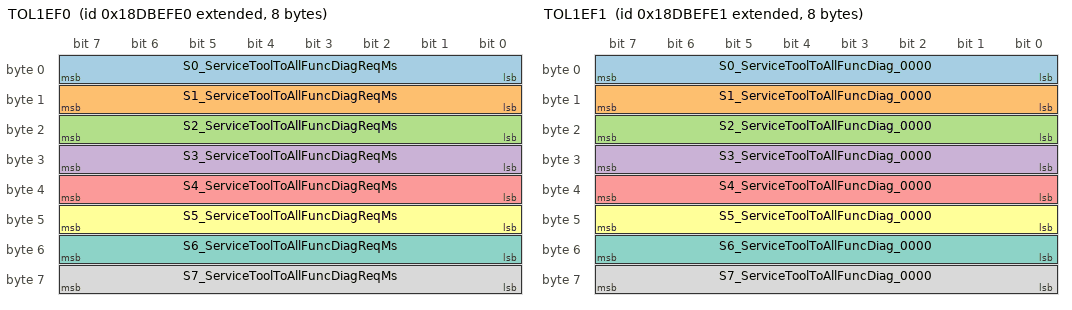
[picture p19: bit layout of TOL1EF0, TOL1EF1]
BO_ 2564550624 TOL1EF0: 8 Vector_XXX
 SG_ S0_ServiceToolToAllFuncDiagReqMs : 7|8@0+ (1,0) [0|0] "-"  CDC
 SG_ S1_ServiceToolToAllFuncDiagReqMs : 15|8@0+ (1,0) [0|0] "-"  CDC
 SG_ S2_ServiceToolToAllFuncDiagReqMs : 23|8@0+ (1,0) [0|0] "-"  CDC
 SG_ S3_ServiceToolToAllFuncDiagReqMs : 31|8@0+ (1,0) [0|0] "-"  CDC
 SG_ S4_ServiceToolToAllFuncDiagReqMs : 39|8@0+ (1,0) [0|0] "-"  CDC
 SG_ S5_ServiceToolToAllFuncDiagReqMs : 47|8@0+ (1,0) [0|0] "-"  CDC
 SG_ S6_ServiceToolToAllFuncDiagReqMs : 55|8@0+ (1,0) [0|0] "-"  CDC
 SG_ S7_ServiceToolToAllFuncDiagReqMs : 63|8@0+ (1,0) [0|0] "-"  CDC

BO_ 2564550625 TOL1EF1: 8 Vector_XXX
 SG_ S0_ServiceToolToAllFuncDiag_0000 : 7|8@0+ (1,0) [0|0] "-"  Vector_XXX
 SG_ S1_ServiceToolToAllFuncDiag_0000 : 15|8@0+ (1,0) [0|0] "-"  Vector_XXX
 SG_ S2_ServiceToolToAllFuncDiag_0000 : 23|8@0+ (1,0) [0|0] "-"  Vector_XXX
 SG_ S3_ServiceToolToAllFuncDiag_0000 : 31|8@0+ (1,0) [0|0] "-"  Vector_XXX
 SG_ S4_ServiceToolToAllFuncDiag_0000 : 39|8@0+ (1,0) [0|0] "-"  Vector_XXX
 SG_ S5_ServiceToolToAllFuncDiag_0000 : 47|8@0+ (1,0) [0|0] "-"  Vector_XXX
 SG_ S6_ServiceToolToAllFuncDiag_0000 : 55|8@0+ (1,0) [0|0] "-"  Vector_XXX
 SG_ S7_ServiceToolToAllFuncDiag_0000 : 63|8@0+ (1,0) [0|0] "-"  Vector_XXX

CM_ BO_ 1019 "Reserve";
CM_ SG_ 1019 LK_ST "Walk Away Lock Function state";
CM_ SG_ 1019 LK_FUNC "Walk Away Lock Function";
CM_ SG_ 1019 ULK_ST "Approach Auto Unlock Function state";
CM_ SG_ 1019 ULK_FUNC "Approach Auto Unlock Function";
CM_ BO_ 331 "Reserve";
CM_ SG_ 331 IDTRQBT "BT communication start request";
CM_ SG_ 331 IDTDSPID "IDT request Display ID";
CM_ SG_ 331 IDTIMBST "IDT Immobilizer state";
CM_ SG_ 331 IDTSTLST "IDT Steering Lock state";
CM_ SG_ 331 IDTCNT "Counter";
CM_ SG_ 331 SUM14B "Check sum";
CM_ BO_ 1330 "Reserve";
CM_ SG_ 1330 RSISIDME "Pre Verification response(Verification method)";
CM_ SG_ 1330 RSISIDID "Pre Verification response(ID)";
CM_ BO_ 1083 "Reserve";
CM_ SG_ 1083 IPA_BZ2 "IPA_BUZZER2";
CM_ SG_ 1083 VNUSGAPP "Voice Nortification Usage(APP)";
CM_ SG_ 1083 APP_EXT "APP Exist";
CM_ SG_ 1083 IPAVOICE "IPA Voice";
CM_ SG_ 1083 APPME "APP DISPLAY REQUEST";
CM_ BO_ 875 "Reserve";
CM_ SG_ 875 IC_EQP "Equipment of Vehicle-infrastructure Cooparative Systems";
CM_ SG_ 875 ICON_V2R "Service Icon for Vehicle to Roadside System";
CM_ SG_ 875 ICON_V2V "Service Icon for Vehicle to Vehicle System";
CM_ SG_ 875 IC_BZR "Buzzer request for Vehicle-infrastructure Cooparative Systems";
CM_ SG_ 875 IC_APL "Selected Application of Vehicle-infrastructure Cooparative Systems";
CM_ SG_ 875 IC_WNG "Warning requirement for Vehicle-infrastructure Cooparative Systems";
CM_ SG_ 875 EVN_POS1 "Position specification for Emargency Vehicle Notification (#1)";
CM_ SG_ 875 EVN_POS2 "Position specification for Emargency Vehicle Notification (#2)";
CM_ SG_ 875 EVN_ARR1 "Arrow direction specification for Emargency Vehicle Notification (#1)";
CM_ SG_ 875 EVN_ARR2 "Arrow direction specification for Emargency Vehicle Notification (#2)";
CM_ SG_ 875 EVN_DIS1 "Distance from the Emargency Vehicle (#1)";
CM_ SG_ 875 EVN_DIS2 "Distance from the Emargency Vehicle (#2)";
CM_ SG_ 875 STR_OVEH "Oncoming Vehicle display for Turning Right";
CM_ SG_ 875 STR_PED "Pedestrian display for Turning Right";
CM_ SG_ 875 SCN_TIME "Remaining time display for Signal Change Notification";
CM_ BO_ 990 "Reserve";
CM_ SG_ 990 ITSSET "System Settings Screen enabler (Infrastructure Cooperative Systems)";
CM_ SG_ 990 ITSTMDIS "Timing Setting Screen enabler (ITS Connect)";
CM_ SG_ 990 ITSTMSTA "Timing Setting Status  (ITS Connect)";
CM_ SG_ 990 ITSSTSTA "On/Off Setting Status(ITS Connect)";
CM_ BO_ 788 "Reserve";
CM_ SG_ 788 IC_APL2 "Selected Application of Vehicle-infrastructure Cooparative Systems 2";
CM_ SG_ 788 CRC_MSG "Display Request for Crossing Collision Assist (Message)";
CM_ SG_ 788 CRC_L "Display Request for Crossing Collision Assist (Left)";
CM_ SG_ 788 CRC_R "Display Request for Crossing Collision Assist (Right)";
CM_ SG_ 788 IC_APL3 "Selected Application 3 of  Infrastructure Cooperative Systems(For HUD)";
CM_ BO_ 635 "Reserve";
CM_ SG_ 635 ITSVOI01 "ITS Voice information 01";
CM_ BO_ 371 "Reserve";
CM_ SG_ 371 LR_RC_PS "LRseatCurrentPosition(Reclining)";
CM_ BO_ 377 "Reserve";
CM_ SG_ 377 LR_SL_PS "LRseatCurrentPosition(Slide)";
CM_ BO_ 378 "Reserve";
CM_ SG_ 378 LR_LF_PS "LRseatCurrentPosition(Lifter)";
CM_ BO_ 502 "Reserve";
CM_ SG_ 502 REQFRFID "Target face registration ID";
CM_ SG_ 502 CHG_KPF "Change Automatic Profile Change setting";
CM_ SG_ 502 CHG_PSN "Change Personalization setting";
CM_ SG_ 502 REQ_DCHG "New Driver Approval Response";
CM_ SG_ 502 REQFREXE "Request face registration execution";
CM_ SG_ 502 MET_SPD "Vehicle speed signal(meter to other)";
CM_ SG_ 502 RHEOSTAT "Rheostat duty signal";
CM_ SG_ 502 TAIL_CN "Tail cancel signal";
CM_ SG_ 502 ILL_OF "Lounge illumination off signal";
CM_ BO_ 1553 "Reserve";
CM_ SG_ 1553 ODO_UNIT "Odometer unit signal";
CM_ SG_ 1553 ODO "Odometer signal";
CM_ BO_ 1560 "Reserve";
CM_ SG_ 1560 AS_DT "Drive monitor display signal (after starting mileage)";
CM_ SG_ 1560 UNIT_2 "Drive monitor unit signal 2";
CM_ BO_ 1556 "Reserve";
CM_ SG_ 1556 TRIP_A "TRIP_A signal";
CM_ BO_ 1557 "Reserve";
CM_ SG_ 1557 HCSUPEN "Height Control UP operation";
CM_ SG_ 1557 HCSDWEN "Height Control DW operation";
CM_ SG_ 1557 HCSMNSW "Height Control Manual Mode operation";
CM_ SG_ 1557 HCSETDSP "Height Control setting screen display status";
CM_ SG_ 1557 HCSSTPOP "Height Control Stop operation";
CM_ SG_ 1557 UNIT_CH2 "Unit change signal2(KM/MILE)";
CM_ SG_ 1557 TOLER_A "Speed Tolerance A";
CM_ SG_ 1557 TOLER_B "Speed Tolerance B";
CM_ SG_ 1557 TRIP_B "TRIP_B signal";
CM_ BO_ 1421 "Reserve";
CM_ SG_ 1421 PSRSP1 "Proposal Service Response 1";
CM_ SG_ 1421 PSRSP2 "Proposal Service Response 2";
CM_ SG_ 1421 PSRSP3 "Proposal Service Response 3";
CM_ BO_ 1002 "Reserve";
CM_ SG_ 1002 CSR_MUTE "Clearance sonar mute SW";
CM_ SG_ 1002 SW_LTC01 "Lane Change Assist Control Switch";
CM_ SG_ 1002 SW_RCD01 "Rear Camera Detection Switch";
CM_ SG_ 1002 TSR_OSL "TSR Over Speed Level SW";
CM_ SG_ 1002 TSR_SNM "SW TSR over speed notice method SW";
CM_ SG_ 1002 FCMUSER "Sway Advisory Disp Off Operation SW";
CM_ SG_ 1002 ITSSETSW "ITS Connect OnOff Switch";
CM_ SG_ 1002 RCTAMSW "RCTA ON/OFF";
CM_ SG_ 1002 ICSMSW "ICS MAIN SW";
CM_ SG_ 1002 BSMMSW "BSM ON/OFF";
CM_ SG_ 1002 CSRMSW "Ultrasonic Detecting and Ranging System ON/OFF";
CM_ SG_ 1002 SW_ITS04 "ITS Support Timing Switch";
CM_ SG_ 1002 TSR_MAIN "TSR MAIN SW";
CM_ SG_ 1002 LDAMCUS "LDA sensitivity switchover";
CM_ SG_ 1002 PCSMSW "PCS ON/OFF";
CM_ SG_ 1002 FCMMSW "Sway Warning";
CM_ SG_ 1002 LDA_SFB "LDA STEERING FB LVL";
CM_ BO_ 894 "Reserve";
CM_ SG_ 894 ACINV_SW "AC100V_SW";
CM_ SG_ 894 RSCSW_OP "RSC Level SW operation";
CM_ BO_ 1004 "Reserve";
CM_ SG_ 1004 SW_AS01 "Air Sus Height Control Switch";
CM_ SG_ 1004 SW_AS02 "Air Sus Step Control Switch";
CM_ SG_ 1004 TPUNTSET "TPMS Unit Setting";
CM_ SG_ 1004 TPINSEL "TPMS INITIAL VALUE SELECT";
CM_ SG_ 1004 TPINSELR "TPMS INITIAL VALUE SELECT REAR";
CM_ SG_ 1004 TPINSELF "TPMS INITIAL VALUE SELECT FRONT";
CM_ SG_ 1004 SW_AS05 "The parking height control SW";
CM_ SG_ 1004 WVRU_BB "Front Wiper AUTO Sensitivity or INT Interval UP operation signal";
CM_ SG_ 1004 WVRD_BB "Front Wiper AUTO Sensitivity or INT Interval Down operation signal";
CM_ SG_ 1004 WRSW_BB "Rear Washer operation signal";
CM_ SG_ 1004 WROF_BB "Rear Wiper OFF operation signal";
CM_ SG_ 1004 WRIN_BB "Rear Wiper INT operation signal";
CM_ SG_ 1004 WRLO_BB "Rear Wiper LO operation signal";
CM_ BO_ 1006 "Reserve";
CM_ SG_ 1006 PBDKSW "PBD KICK ON/OFF SW operation signal";
CM_ SG_ 1006 TITE_BB "Tilt & Telescopic ON/OFF SW operation signal";
CM_ SG_ 1006 ASD_CANC "ASD CANCEL SIGNAL";
CM_ SG_ 1006 ASD_CONT "ASD CONTINUE SIGNAL";
CM_ SG_ 1006 RSRMSW "Rear Seat Reminder ON/OFF";
CM_ SG_ 1006 SRPMSW "SRP ON/OFF SW";
CM_ SG_ 1006 RSRCANSW "Seat Reminder Alert Cancel SW";
CM_ SG_ 1006 VRAPRDIS "Voice recognition approval screen display status";
CM_ SG_ 1006 PWLSW "PW Lock SW";
CM_ SG_ 1006 MLR_BB "Mirror left-right selection operation";
CM_ SG_ 1006 DPMS_BB "Driving position emergency stop switch operation";
CM_ SG_ 1006 LSW_BB "Headlamp  operation SW signal";
CM_ SG_ 1006 WSVS_BB "Service position operation SW signal";
CM_ SG_ 1006 M_BB "Mirror adjustment signal";
CM_ SG_ 1006 VRESTPSW "Voice Recognition Emergency Stop SW";
CM_ SG_ 1006 MRT_BB "Outer mirror manual switch operation";
CM_ SG_ 1006 RLM_BB "Reverse interlock outer mirror switch operation";
CM_ SG_ 1006 FOG_BB "Front fog lamp operation";
CM_ SG_ 1006 MINTRSOF "Intrusion sensor OFF SW signal";
CM_ SG_ 1006 RFG_BB "Rear fog lamp operation";
CM_ SG_ 1006 ART_BB "Outer mirror AUTO switch operation";
CM_ SG_ 1006 PBD_BB "-";
CM_ SG_ 1006 POS_REG "Driving position memory registration switch operation";
CM_ SG_ 1006 PBDBZMVL "PBD Buzzer Vol SW";
CM_ SG_ 1006 POS_CALL "Driving position memory playback switch operation";
CM_ SG_ 1006 PBDMSW "PBD ON/OFF SW operation signal";
CM_ SG_ 1006 PBDMCUS "PBD Cutom SW";
CM_ SG_ 1006 ULKMSW "Approach Auto Unlock ON/OFF SW operation signal";
CM_ SG_ 1006 LKMSW "Walk Away Lock ON/OFF SW operation signal";
CM_ SG_ 1006 VRAPRMSW "Voice Recognition Approval SW";
CM_ BO_ 789 "Reserve";
CM_ SG_ 789 CL_AMPM "AM PM Display";
CM_ SG_ 789 CL_HOUR "Clock Display Time (hour)";
CM_ SG_ 789 TIME_SET "24hours Display ON/OFF information";
CM_ SG_ 789 CL_MIN "Clock Display Time (Minute)";
CM_ SG_ 789 CL_SEC "Clock Display Time (Second)";
CM_ SG_ 789 OFSTSIGN "Clock Offset Time(sign)";
CM_ SG_ 789 M_MONTH "Meter Date Information(Month)";
CM_ SG_ 789 OFST_H "Clock Offset Time(hour)";
CM_ SG_ 789 OFST_M "Clock Offset Time(minute)";
CM_ SG_ 789 M_YEAR "Meter Date Information(Year)";
CM_ SG_ 789 M_WEEK "Meter Date Information(Week)";
CM_ SG_ 789 M_DAY "Meter Date Information(Day)";
CM_ BO_ 1316 "Reserve";
CM_ SG_ 1316 AS_TM "Drive monitor display signal (after starting driving time)";
CM_ SG_ 1316 EC_SCL "Electric consumption Scale";
CM_ SG_ 1316 TR2_DUTY "Tr2 duty signal";
CM_ SG_ 1316 IL2_DUTY "Il2- duty signal";
CM_ SG_ 1316 RANGE "Drive monitor display signal (distance which can be run)";
CM_ SG_ 1316 AS_SP "Drive monitor display signal (after starting average speed)";
CM_ SG_ 1316 UNIT_1 "Drive monitor unit signal 1";
CM_ SG_ 1316 UNIT_6 "Drive monitor unit signal 6";
CM_ SG_ 1316 NFCS "New fuel consumption control signal";
CM_ SG_ 1316 RHEO_POS "Rheostat position";
CM_ BO_ 1319 "Reserve";
CM_ SG_ 1319 ST_ACOFF "STSW info(A/C OFF)";
CM_ SG_ 1319 ST_TDEF "Transport STSW info(A/C DEF)";
CM_ SG_ 1319 ST_TAUTO "Transport STSW info(A/C AUTO)";
CM_ BO_ 476 "Reserve";
CM_ SG_ 476 BKL3LMET "3rd row left side seatbelt SW signal";
CM_ SG_ 476 BKL3RMET "3rd row right side seatbelt SW signal";
CM_ SG_ 476 BKL3CMET "3rd row center side seatbelt SW signal";
CM_ SG_ 476 DBKL_MET "Driver's seatbelt SW signal";
CM_ SG_ 476 PBKL_MET "Passenger's seatbelt SW signal";
CM_ SG_ 476 RLBKLMET "Rear Left side  seatbelt SW signal";
CM_ SG_ 476 RRBKLMET "Rear Right side  seatbelt SW signal";
CM_ SG_ 476 RCBKLMET "Rear Center seatbelt SW signal";
CM_ SG_ 476 TRNBBSW "ADAS Training Mode BB SW";
CM_ BO_ 781 "Reserve";
CM_ SG_ 781 ODO_UNI2 "Odometer unit signal 2";
CM_ SG_ 781 ODO_01 "Odometer signal(LSB:0.1km)";
CM_ BO_ 503 "Reserve";
CM_ SG_ 503 IN_EC "Drive monitor display signal (instant electric consumption)";
CM_ SG_ 503 M1_EC1 "Drive monitor display signal (1 min average EV consumption)";
CM_ SG_ 503 M1_EC_R "Drive monitor display signal (1 min average EV consumption renewal signal)";
CM_ SG_ 503 EV_RANGE "Drive monitor display signal (EV distance which can be run)";
CM_ SG_ 503 TO_EC "Drive monitor display signal (total average EV consumption)";
CM_ SG_ 503 AS_EC "Drive monitor display signal (Average EV consumption after starting)";
CM_ SG_ 503 AS_TOEC "Drive monitor display signal (after starting electoricity consumption)";
CM_ SG_ 503 AS_EVDT "Drive monitor display signal (after starting EV mileage)";
CM_ BO_ 1050 "Reserve";
CM_ SG_ 1050 RNGMSW "Range mode switching SW";
CM_ SG_ 1050 TBCSW "Traction battery cooler ON/OFF SW operation signal";
CM_ SG_ 1050 TBWSW "Traction battery warmer ON/OFF SW operation signal";
CM_ BO_ 957 "Reserve";
CM_ SG_ 957 MSG_NSFT "N shift advisory display demand";
CM_ SG_ 957 MSG_CHK "SBW system check demand display signal";
CM_ SG_ 957 MSG_SFTF "shift sensor fail display demand";
CM_ SG_ 957 B_SLUP_S "Sfhit up indicator display demand";
CM_ SG_ 957 B_SLDN_S "Sfhit down indicator display demand";
CM_ SG_ 957 MSG_RI_S "reject information display demand";
CM_ SG_ 957 BZR_SFT1 "SBW buzzer sounding demand 1";
CM_ SG_ 957 B_GEAR_S "Shift gear display demand";
CM_ SG_ 957 MSG_SFPF "shift sensor pre fail display demand";
CM_ SG_ 957 SBWFUNC "SBW Function Judge";
CM_ SG_ 957 SFT_BLKS "shift positon blink request for double parking";
CM_ SG_ 957 SFT_METS "Shift Position of SBW for meter";
CM_ SG_ 957 SILUASBW "Specifications information learning unfinished alert(SBW)";
CM_ SG_ 957 MSG_DAP "Door open auto P display demand";
CM_ SG_ 957 MSG_ACCN "N position keeping status after ignition-off display demand";
CM_ SG_ 957 FV3BD "PCN1S01 Freshness Value";
CM_ SG_ 957 KZK3BD "PCN1S01 KZKValue";
CM_ BO_ 460 "Reserve";
CM_ SG_ 460 BAOF_PDC "Notice of BA to OFF";
CM_ BO_ 1287 "Reserve";
CM_ SG_ 1287 RLBKLPDC "Rear Left side  seatbelt SW signal";
CM_ SG_ 1287 RCBKLPDC "Rear Center seatbelt SW signal";
CM_ SG_ 1287 RRBKLPDC "Rear Right side  seatbelt SW signal";
CM_ SG_ 1287 PBKL_PDC "Passenger seatbelt SW signal";
CM_ SG_ 1287 BAT_ADV "Power Operation Request";
CM_ SG_ 1287 BATSAVE "Battery Saver Request";
CM_ SG_ 1287 WASHLVSW "Washer Level SW signal";
CM_ BO_ 661 "Reserve";
CM_ SG_ 661 OTACHGWT "OTA WAIT Request(CHG)";
CM_ SG_ 661 P_SPLNSO "Request to skip the start operation screen";
CM_ SG_ 661 P_DVOAVA "DC charging voltage function";
CM_ SG_ 661 P_DVOSL1 " DC charging voltage setting ";
CM_ SG_ 661 P_WLCEQP "Wireless charging system equipment";
CM_ SG_ 661 P_SETID "Setting ID";
CM_ SG_ 661 P_SETON "Setting enable/disable";
CM_ SG_ 661 P_SETWKD "Weekday Select";
CM_ SG_ 661 P_SETTYP "Setting Type";
CM_ SG_ 661 P_SETSTM "Start Time";
CM_ SG_ 661 P_SETNXT "Next Setting ID";
CM_ SG_ 661 P_SETFTM "Finish Time ";
CM_ SG_ 661 P_TMPID "Timer setting ID";
CM_ SG_ 661 P_TMPSWK "Timer setting weekday select";
CM_ SG_ 661 P_TMPSTM "Start setting time";
CM_ SG_ 661 P_ADDDSP "Add Button";
CM_ SG_ 661 PCNOWDSP "Now Charging Button";
CM_ SG_ 661 P_EDTDSP "Edit Button";
CM_ SG_ 661 P_TMPTYP "Timer Setting type";
CM_ SG_ 661 P_TMPNWK "Next charge weekday select";
CM_ SG_ 661 P_TMPFTM "Finish setting time";
CM_ SG_ 661 P_DPWAVA "DC charging power function";
CM_ SG_ 661 P_DPWSL "DC charging power selection";
CM_ BO_ 662 "Reserve";
CM_ SG_ 662 PLGSTS "PLG Status";
CM_ SG_ 662 PIINFD08 "PLG Information";
CM_ SG_ 662 PIINFDSP "PLG Information Request";
CM_ SG_ 662 PSDSPRQ2 "PLG Information Display Flag2";
CM_ SG_ 662 PSDSPRQ "PLG Information Display Flag";
CM_ SG_ 662 P_CLCSL4 "Connector lock selection4";
CM_ SG_ 662 P_CLCSL3 "Connector lock selection3";
CM_ SG_ 662 P_CLCSL2 "Connector lock selection2";
CM_ SG_ 662 P_CLCSL1 "Connector lock selection1";
CM_ SG_ 662 P_LMDAVA "Extended Power Supply Mode";
CM_ SG_ 662 PLID_DSP "Charging Lid Opener Popup Request";
CM_ SG_ 662 P_LMDNW "Extended Power Supply Mode setting";
CM_ SG_ 662 DCRCKDSP "DCR Check Popup Qequest";
CM_ SG_ 662 P_SETSTS "Setting Change Status";
CM_ SG_ 662 P_DPW "DC charging power setting";
CM_ SG_ 662 P_NCTYP "Charge Setting type";
CM_ SG_ 662 P_NCWKD "Charge Weekday Select";
CM_ SG_ 662 P_NCSTM "Charge Start Time";
CM_ SG_ 662 P_SLMSL1 "Electric Supply Limit selection1";
CM_ SG_ 662 P_NCDSP "Next charge indication";
CM_ SG_ 662 P_NCFTM "Charge Finish Time ";
CM_ SG_ 662 P_SLMSL3 "Electric Supply Limit selection3";
CM_ SG_ 662 P_SLMSL2 "Electric Supply Limit selection2";
CM_ SG_ 662 P_NCLMT "Next charging limit";
CM_ SG_ 662 P_NCCUR "Next charging current";
CM_ SG_ 662 P_SLMSL5 "Electric Supply Limit selection5";
CM_ SG_ 662 P_SLMSL4 "Electric Supply Limit selection4";
CM_ SG_ 662 P_SLMNOW "Electric Supply Limit Setting";
CM_ SG_ 662 PCHGTM07 "Plugin charge remainder time to 80%";
CM_ SG_ 662 P_TMRAVA "Charging Schedule function";
CM_ SG_ 662 P_CURAVA "Charging current function";
CM_ SG_ 662 P_LMTAVA "Charging limit function";
CM_ SG_ 662 P_CLCAVA "Connector lock function";
CM_ SG_ 662 P_LMTDSP "Charging limit setting for display";
CM_ SG_ 662 P_SPLAVA "Electric supply function";
CM_ SG_ 662 P_SLMAVA "Electric supply limit function";
CM_ SG_ 662 P_TMRSTR "Start function";
CM_ SG_ 662 P_TMRSST "Start-stop function";
CM_ SG_ 662 P_SPLEVA "EV Select";
CM_ SG_ 662 P_SPLHVA "HV Select";
CM_ SG_ 662 P_LMTSEL "Charging limit selection numbers";
CM_ SG_ 662 P_LMTNOW "Charging limit setting";
CM_ SG_ 662 P_SPLDSP "Display request of Electric Supplying Screen";
CM_ SG_ 662 P_SPLEVW "Display request of Electric Mode Alert Screen";
CM_ SG_ 662 P_SPLACA "AC electric supply presence";
CM_ SG_ 662 P_SPLDCA "DC electric supply presence";
CM_ BO_ 1058 "Reserve";
CM_ SG_ 1058 PWSPLT_G "Remaining time for external power supply with gasoline";
CM_ SG_ 1058 P_CUR200 "MAX Charge Current (200V)";
CM_ SG_ 1058 PCNCTIND "Plug-in Connect Indicator";
CM_ SG_ 1058 P_CURSL2 "Charging current selection2";
CM_ SG_ 1058 P_CURSL1 "Charging current selection1";
CM_ SG_ 1058 CBLOCKSU "Cable Lock Setup";
CM_ SG_ 1058 PWSPLT_B "Remaining time for external power supply";
CM_ SG_ 1058 P_SPLPOP "Electric Supply Popup Request";
CM_ SG_ 1058 CNCTLOCK "Connector and Lock Information";
CM_ SG_ 1058 P_CURSL4 "Charging current selection4";
CM_ SG_ 1058 P_CURSL3 "Charging current selection3";
CM_ BO_ 1073 "Reserve";
CM_ SG_ 1073 MRMMSG "Myroom Message";
CM_ BO_ 1074 "Reserve";
CM_ SG_ 1074 PIEVDSR "Subtraction rate of Plug-in EV distance";
CM_ SG_ 1074 PIEVE06 "Plug-in EV energy";
CM_ SG_ 1074 PCHGTM06 "Plugin charge remainder time";
CM_ SG_ 1074 PIEVD06 "Distance where it can run";
CM_ SG_ 1074 SOC_DSP "SOC display";
CM_ SG_ 1074 PIPRE "Plug-in power revenue and expenditure";
CM_ SG_ 1074 ACSTS06 "State of AC power supply";
CM_ BO_ 678 "Reserve";
CM_ SG_ 678 R_NBPSET "Next Battery preconditioning setting";
CM_ SG_ 678 R_NACSET "Next Air conditioning setting";
CM_ SG_ 678 R_ADDDSP "Schedule additional indication";
CM_ SG_ 678 R_BPEXST "Schedule existence of battery preconditioning";
CM_ SG_ 678 R_BPON "Setting enable/disable of battery preconditioning";
CM_ SG_ 678 R_BPSET "Battery preconditioning setting";
CM_ SG_ 678 R_ACSET "Air conditioning setting of battery preconditioning";
CM_ SG_ 678 R_NDEPTM "Next departure time of battery preconditioning";
CM_ SG_ 678 P_VPAVST "Smart Charging Contract Status Notification";
CM_ SG_ 678 R_NBPWKD "Next weekday select of battery preconditioning";
CM_ SG_ 678 R_BPID "Setting ID of battery preconditioning";
CM_ SG_ 678 R_DEPTM "Departure time of battery preconditioning";
CM_ SG_ 678 R_BPWKD "Weekday select of battery preconditioning";
CM_ SG_ 678 P_VPVGST "Smart Charging Setting Status";
CM_ SG_ 678 P_OCTAVA "Optimal charging  function";
CM_ SG_ 678 P_OCTID "Optimal charging configuration ID";
CM_ SG_ 678 P_LMTNO2 "Charging limit setting Sub";
CM_ SG_ 678 P_OCTON "Optimal Charging On/off state";
CM_ SG_ 678 P_OCTTYP "Optimal Charging Type";
CM_ SG_ 678 P_OCTON2 "Optimal Charging On/off state Sub";
CM_ SG_ 678 P_OCTSTM "Optimal Start setting Time";
CM_ SG_ 678 P_OCTWKD "Optimal day of the week selection";
CM_ SG_ 678 P_OCTFTM "Optimal Finish setting Time";
CM_ SG_ 678 P_OCTWK2 "Optimal day of the week selection Sub";
CM_ SG_ 678 P_OCTST2 "Optimal Start setting Time Sub";
CM_ SG_ 678 P_USOC2A "Used SOC at 2 charges before";
CM_ SG_ 678 P_OCTFT2 "Optimal Finish setting Time Sub";
CM_ SG_ 678 P_USOC1A "Used SOC at 1 charges before";
CM_ SG_ 678 P_LMDSTM "Recommend  Start setting Time";
CM_ SG_ 678 P_USOC0A "Used SOC at present";
CM_ SG_ 678 P_LMDFTM "Recommend  Finish setting Time";
CM_ SG_ 678 P_LMDLMT "Recommend Charging target";
CM_ SG_ 678 P_LMDST2 "Recommend  Start setting Time Sub";
CM_ SG_ 678 P_LMDWKD "Recommend  day of the week selection";
CM_ SG_ 678 P_LMDFT2 "Recommend  Finish setting Time Sub";
CM_ SG_ 678 P_LMDLM2 "Recommend Charging target Sub";
CM_ SG_ 678 P_OCADFL "Optimal charging advice flag";
CM_ SG_ 678 P_LMDWK2 "Recommend  day of the week selection  Sub";
CM_ SG_ 678 P_OCFLFL "Full charge count reach status flag";
CM_ SG_ 678 P_OCTTY2 "Optimal Charging Type Sub";
CM_ SG_ 678 P_OCRQFL "Optimal charging notification request flag";
CM_ SG_ 678 P_OCNFFL "Non-full charge count reach status flag";
CM_ SG_ 678 EV_CON_N "EV Connector Type(Normal Charge)";
CM_ SG_ 678 EV_CON_Q "EV Connector Type(Quick Charge)";
CM_ SG_ 678 P_VPSOCT "Smart Charging Target SOC";
CM_ SG_ 678 P_VPSOCL "Smart Charging Minimum SOC";
CM_ BO_ 516 "Reserve";
CM_ SG_ 516 P_PNC "Plug&Charge setting";
CM_ SG_ 516 P_ACINST "Certificate installation status";
CM_ SG_ 516 P_PNCAVA "Plug&Charge function";
CM_ SG_ 516 P_CEIBRQ "Certificate update button";
CM_ SG_ 516 P_CEEXPD "Certificate expire date (D)";
CM_ SG_ 516 ACTCHGRT "Actual Charging Rate";
CM_ SG_ 516 CRTDSPRQ "Charging Rate Display Request";
CM_ SG_ 516 MXCHGRT "Max Charging Rate";
CM_ SG_ 516 ACTOPSPW "Actual External Power Supply";
CM_ SG_ 516 MXOPSPW "Maximum External Power Supply";
CM_ SG_ 516 SPWDSPRQ "External Power Supply Display Request";
CM_ SG_ 516 PSPLTAVA "Remaining time Assumption for Power Supply";
CM_ SG_ 516 P_CEEXPY "Certificate expire date (Y)";
CM_ SG_ 516 P_CEEXPM "Certificate expire date (M)";
CM_ BO_ 465 "Reserve";
CM_ SG_ 465 PSSW_PMN "Push start SW signal";
CM_ SG_ 465 IGJG_EIG "IG OFF Judge signal";
CM_ SG_ 465 MOD_EIG "Display request of vehicle mode";
CM_ SG_ 465 BZRQ_EIG "Buzzer request signal";
CM_ SG_ 465 APOFPNRQ "Appearance OFF PreNotification Request";
CM_ SG_ 465 SMTRDYFG "Smart Ready On Flag";
CM_ BO_ 1027 "Reserve";
CM_ SG_ 1027 P_EXTRA "Passenger's Seat Extra Position";
CM_ SG_ 1027 P_WALKIN "Walk in State of Driver's Seat";
CM_ SG_ 1027 P_SLDPOS "Passenger's Seat Slide Position";
CM_ SG_ 1027 P_RCLPOS "Passenger's Seat Reclining Position";
CM_ SG_ 1027 PST_OPAT "Display request signal for P Seat operation attention";
CM_ SG_ 1027 RSE_LMT "RSE Limit of Seeing";
CM_ BO_ 1029 "Reserve";
CM_ SG_ 1029 P_FST "Passenger's seat function";
CM_ SG_ 1029 P_OPST "Passenger's seat operation permission state";
CM_ SG_ 1029 P_OPPT1 "Passenger's seat operation part 1";
CM_ SG_ 1029 P_OPPT2 "Passenger's seat operation part 2";
CM_ SG_ 1029 P_STM1 "Passenger's seat operation state No.1";
CM_ SG_ 1029 P_STM2 "Passenger's seat operation state No.2";
CM_ SG_ 1029 P_RF_ST "Passenger's seat refresh mode";
CM_ SG_ 1029 P_RF_LV "Passenger's seat refresh level";
CM_ SG_ 1029 P_LIFPOS "Passenger's Seat Lift Position";
CM_ SG_ 1029 P_OPPT3 "Passenger's seat operation part 3";
CM_ SG_ 1029 P_OPPT4 "Passenger's seat operation part 4";
CM_ BO_ 333 "Reserve";
CM_ SG_ 333 RCPDSPID "RCP request display ID";
CM_ SG_ 333 RCPCTRMD "Available control mode";
CM_ SG_ 333 RCPTGTMD "Target parking mode";
CM_ SG_ 333 RCPDIST "Remaining distance and direction information";
CM_ SG_ 333 RCPLR "Direction information (Left and Right)";
CM_ SG_ 333 RCPFB "Direction information (Front and Back)";
CM_ SG_ 333 RCPACCIH "RCP State for MM ACC control inhibition";
CM_ SG_ 333 RCPCNT "RCP watchdog counter";
CM_ SG_ 333 RCPSUM "RCP error detection code";
CM_ BO_ 335 "Reserve";
CM_ SG_ 335 RCPMD "RCP system status flag";
CM_ SG_ 335 RCPFAIL "RCP error status";
CM_ SG_ 335 RCPONST "RCP function ON/OFF status";
CM_ BO_ 386 "Reserve";
CM_ SG_ 386 RR_RC_PS "RRseatCurrentPosition(Reclining)";
CM_ BO_ 393 "Reserve";
CM_ SG_ 393 RR_SL_PS "RRseatCurrentPosition(Slide)";
CM_ BO_ 396 "Reserve";
CM_ SG_ 396 RR_LF_PS "RRseatCurrentPosition(Lifter)";
CM_ BO_ 970 "Reserve";
CM_ SG_ 970 D_YEAR "Date and time information of DCM(YEAR)";
CM_ SG_ 970 D_MONT "Date and time information of DCM(MONTH)";
CM_ SG_ 970 D_DAY "Date and time information of DCM(DAY)";
CM_ SG_ 970 D_HOUR "Date and time information of DCM(HOUR)";
CM_ SG_ 970 D_MIN "Date and time information of DCM(MINUTES)";
CM_ SG_ 970 D_SEC "Date and time information of DCM(SECOND)";
CM_ BO_ 815 "Reserve";
CM_ SG_ 815 LATUDE "Latitude information";
CM_ SG_ 815 LOTUDE1 "Longitude information 1";
CM_ SG_ 815 D_LAT1 "Latitude detail information1";
CM_ SG_ 815 D_LAT2 "Latitude detail information2";
CM_ BO_ 822 "Reserve";
CM_ SG_ 822 D_LON1 "Longitude detail information1";
CM_ SG_ 822 D_LON2 "Longitude detail information2";
CM_ BO_ 845 "Reserve";
CM_ SG_ 845 ALTITUDE "Altitude";
CM_ BO_ 901 "Reserve";
CM_ SG_ 901 OTADTYPE "OTA update type";
CM_ SG_ 901 OTADSTAT "OTA update status";
CM_ SG_ 901 OTADPROG "OTA update progress";
CM_ SG_ 901 OTADERR "OTA update error type";
CM_ BO_ 968 "Reserve";
CM_ SG_ 968 RSCYCL11 "RS_cyclic_com 11";
CM_ SG_ 968 RSCYCL12 "RS_cyclic_com 12";
CM_ SG_ 968 RSCYCL13 "RS_cyclic_com 13";
CM_ SG_ 968 RSCYCL14 "RS_cyclic_com 14";
CM_ SG_ 968 RSCYCL15 "RS_cyclic_com 15";
CM_ SG_ 968 RSCYCL16 "RS_cyclic_com 16";
CM_ BO_ 808 "Reserve";
CM_ SG_ 808 S_RTST_L "Rear left seat transmission P seat return state signal";
CM_ SG_ 808 S_RTST_R "Rear right seat transmission P seat return state signal";
CM_ SG_ 808 RR_FST "Rear right side seat function";
CM_ SG_ 808 RL_FST "Rear left side seat function";
CM_ SG_ 808 RR_OPST "Rear right side seat operation permission state";
CM_ SG_ 808 RL_OPST "Rear left side seat operation permission state";
CM_ SG_ 808 RR_STM1 "Rear right side seat operation state No.1";
CM_ SG_ 808 RL_STM1 "Rear left side seat operation state No.1";
CM_ SG_ 808 SEAR_ST1 "Seat arrange state1";
CM_ SG_ 808 SEAR_ST2 "Seat arrange state2";
CM_ SG_ 808 SEAT_AR "Seat arrangement setting";
CM_ SG_ 808 WIR_ST "Walk-in right seat state";
CM_ SG_ 808 WIR_OPST "Walk-in right seat operation permission state";
CM_ SG_ 808 WIL_ST "Walk-in left seat state";
CM_ SG_ 808 WIL_OPST "Walk-in left seat operation permission state";
CM_ SG_ 808 FOR_ST "Fold right seat state";
CM_ SG_ 808 FOR_OPST "Fold right seat operation permission state";
CM_ SG_ 808 FOL_ST "Fold left seat state";
CM_ SG_ 808 FOL_OPST "Fold left seat operation permission state";
CM_ BO_ 1081 "Reserve";
CM_ SG_ 1081 DRVCLS "Driver Classification";
CM_ BO_ 885 "Reserve";
CM_ SG_ 885 PARK_S "PARK  status";
CM_ BO_ 765 "Reserve";
CM_ SG_ 765 ASCEXT "Suspension control  system Information";
CM_ SG_ 765 ASCMINF "Multi Information Request";
CM_ SG_ 765 ASCVFST "Vehicle height indicator frame status";
CM_ SG_ 765 ASCVHIST "Vehicle height indicator height status";
CM_ SG_ 765 ASCVHCST "Vehicle height indicator condition status";
CM_ SG_ 765 ASCUPST "Vehicle height UP status";
CM_ SG_ 765 ASCDNST "Vehicle height down status";
CM_ SG_ 765 ASCOFFST "Vehicle height OFF status";
CM_ SG_ 765 ASCMST "Vehicle height manual status";
CM_ SG_ 765 B_LSUS10 "ACCESS MODE LAMP";
CM_ SG_ 765 B_LSUS18 "KNEEL DOWN LAMP";
CM_ SG_ 765 LFTIND "Lift control status Request";
CM_ SG_ 765 ASCCUSF "setting the switch of AirSUS suport custumize system";
CM_ SG_ 765 ASCCUS "status of AirSUS suport custumize system";
CM_ SG_ 765 ASCSTPF1 "setting the switch of AirSUS control";
CM_ SG_ 765 ASCSTOP1 "status of AirSUS control ";
CM_ SG_ 765 ASCSTPF2 "setting the switch of AirSUS suport system";
CM_ SG_ 765 ASCSTOP2 "status of AirSUS support control ";
CM_ SG_ 765 REGSELRQ "Display Requests for Location Registration/Deletion Menu";
CM_ SG_ 765 GPSSWRQ "Display Requests for GPS-Linked Function ON/OFF SW";
CM_ SG_ 765 GPSCHGRQ "GPS-Linked Function ON/OFF State";
CM_ SG_ 765 ALLDELRQ "Display Requests for All Stored Locations Deletion SW";
CM_ SG_ 765 VHUPSWST "Vehicle Height Up Switch State";
CM_ SG_ 765 VHDWSWST "Vehicle Height Down Switch State";
CM_ SG_ 765 MASWRQ "Display Requests for Vehicle Height Manual Mode Switch";
CM_ SG_ 765 MASWST "Vehicle Height Manual Mode Switch State";
CM_ SG_ 765 HCOPMEXT "Height Control Operation Menu Availablity Information";
CM_ SG_ 765 METFSIRQ "Meter Full Screen Interrupt Display Request";
CM_ SG_ 765 VHDFSINF "Vehicle Height Display Format Switching Information";
CM_ SG_ 765 VHSMINF "Vehicle Height Setting Mode Information";
CM_ SG_ 765 VHSVINF "Vehicle Height Setting Value Information";
CM_ SG_ 765 VEVWDTYP "Vehicle View Display Type";
CM_ SG_ 765 HCOPSD "Height Control Operation State Display";
CM_ SG_ 765 CPUPMDRQ "Control Operation Popup Menu Display Request";
CM_ BO_ 1036 "Reserve";
CM_ SG_ 1036 SOLGN "Amount of Solar Power Generation";
CM_ SG_ 1036 SOLSCL "Scale change information of Solar Graph";
CM_ SG_ 1036 SOLFAIL "SOLar system FAILure information for display";
CM_ SG_ 1036 SOLCST "Solar Drawing Up End Status";
CM_ SG_ 1036 SOLTREV2 "Solar Trip Electric Vehicle Driving Distance 2";
CM_ SG_ 1036 SOL "Presence/Absence of Solar ECU";
CM_ SG_ 1036 SOLRT "Solar Power Generation Rate";
CM_ BO_ 1037 "Reserve";
CM_ SG_ 1037 SOLAGN "Amount of Solar Accumulation Power Generation";
CM_ SG_ 1037 SOLEV "Solar Accumulation Electric Vehicle Driving Distance";
CM_ BO_ 491 "Reserve";
CM_ SG_ 491 SOLDGN1 "Solar generated power of 7 or 3 days ago";
CM_ SG_ 491 SOLDATE1 "Date information for Solar Display 1";
CM_ SG_ 491 SOLDGN2 "Solar generated power of 6 or 2 days ago";
CM_ SG_ 491 SOLDGN3 "Solar generated power of 5 or 1 days ago";
CM_ SG_ 491 SOLDGN4 "Solar generated power of 4 days ago or today";
CM_ BO_ 490 "Reserve";
CM_ SG_ 490 SOLDEV1 "Solar Electric Vehicle Driving Distance of 7 or 3 days ago";
CM_ SG_ 490 SOLDATE2 "Date information for Solar Display 2";
CM_ SG_ 490 SOLDEV2 "Solar Electric Vehicle Driving Distance of 6 or 2 days ago";
CM_ SG_ 490 SOLDEV3 "Solar Electric Vehicle Driving Distance of 5 or 1 days ago";
CM_ SG_ 490 SOLDEV4 "Solar Electric Vehicle Driving Distance of 4 days ago or today";
CM_ BO_ 443 "Reserve";
CM_ SG_ 443 SOLRT2 "Solar Power Generation Rate 2";
CM_ BO_ 1173 "Reserve";
CM_ SG_ 1173 TPM02_ID "TPM1S02 Sub ID";
CM_ SG_ 1173 TPM02_IF "TPM1S02 INFO";
CM_ SG_ 1173 TPCRTID "TPMS CURRENT ID";
CM_ SG_ 1173 TPM_DISC "TPMS Disconnection indicator information";
CM_ SG_ 1173 TPM_VAR "TPMS Variation";
CM_ SG_ 1173 TPM_IND "TPMS indicator";
CM_ SG_ 1173 TPM_DISP "TPMS Display";
CM_ SG_ 1173 TPM_BZR "TPMS Buzzer";
CM_ SG_ 1173 TPM_REM "TPMS Remot warning";
CM_ SG_ 1173 TPTSCVLD "TPMS_TIRE SET CHANGE VALID";
CM_ SG_ 1173 TPM_WARI "TPMS Warikomi";
CM_ BO_ 1174 "Reserve";
CM_ SG_ 1174 TPM03_ID "TPM1S03 Sub ID";
CM_ SG_ 1174 TPM03_IF "TPM1S03 INFO";
CM_ SG_ 1174 TPM_TNUM "TPMS Indicate number information 0";
CM_ SG_ 1174 TPM_REQ0 "TPMS Display request bit 0";
CM_ SG_ 1174 TPM_TAN0 "TPMS Unit information 0";
CM_ SG_ 1174 TPM_FLPR "TPMS FL(ID1) Tire pressure information";
CM_ SG_ 1174 TPM_FL0 "TPMS FL(ID1) Tire indicate information 0";
CM_ SG_ 1174 TPM_FRPR "TPMS FR(ID2) Tire pressure information";
CM_ SG_ 1174 TPM_FR0 "TPMS FR(ID2) Tire indicate information 0";
CM_ SG_ 1174 TPM_RLPR "TPMS RL(ID3) Tire pressure information";
CM_ SG_ 1174 TPM_RL0 "TPMS RL(ID3) Tire indicate information 0";
CM_ SG_ 1174 TPM_RRPR "TPMS RR(ID4) Tire pressure information";
CM_ SG_ 1174 TPM_RR0 "TPMS RR(ID4) Tire indicate information 0";
CM_ SG_ 1174 TPM_SPPR "TPMS SP(ID5) Tire pressure information";
CM_ SG_ 1174 TPM_SP0 "TPMS SP(ID5) Tire indicate information 0";
CM_ BO_ 839 "Reserve";
CM_ SG_ 839 TPFRSET1 "TIRE PRESSURE FRONT SET 1";
CM_ SG_ 839 TPFRSET2 "TIRE PRESSURE FRONT SET 2";
CM_ SG_ 839 TPFRSET3 "TIRE PRESSURE FRONT SET 3";
CM_ SG_ 839 TPFRSET4 "TIRE PRESSURE FRONT SET 4";
CM_ SG_ 839 TPFRSET5 "TIRE PRESSURE FRONT SET 5";
CM_ SG_ 839 TPFRSET6 "TIRE PRESSURE FRONT SET 6";
CM_ BO_ 844 "Reserve";
CM_ SG_ 844 TPRRSET1 "TIRE PRESSURE REAR SET 1";
CM_ SG_ 844 TPRRSET2 "TIRE PRESSURE REAR SET 2";
CM_ SG_ 844 TPRRSET3 "TIRE PRESSURE REAR SET 3";
CM_ SG_ 844 TPRRSET4 "TIRE PRESSURE REAR SET 4";
CM_ SG_ 844 TPRRSET5 "TIRE PRESSURE REAR SET 5";
CM_ SG_ 844 TPRRSET6 "TIRE PRESSURE REAR SET 6";
CM_ SG_ 844 TPINTACK "TPMS INITIAL VALUE ACK";
CM_ BO_ 1047 "Reserve";
CM_ SG_ 1047 TPMCNT1 "TPM_ID1_Counter";
CM_ SG_ 1047 TPMCNT2 "TPM_ID2_Counter";
CM_ SG_ 1047 TPMCNT3 "TPM_ID3_Counter";
CM_ SG_ 1047 TPMCNT4 "TPM_ID4_Counter";
CM_ SG_ 1047 TPMCNT5 "TPM_ID5_Counter";
CM_ SG_ 1047 TPM_LOC1 "TPM location_ID1";
CM_ SG_ 1047 TPM_LOC2 "TPM location_ID2";
CM_ SG_ 1047 TPM_LOC3 "TPM location_ID3";
CM_ SG_ 1047 TPM_LOC4 "TPM location_ID4";
CM_ SG_ 1047 TPM_LOC5 "TPM location_ID5";
CM_ BO_ 879 "Reserve";
CM_ SG_ 879 TPTEMPFL "TPM TEMP FL";
CM_ SG_ 879 TPTEMPFR "TPM TEMP FR";
CM_ SG_ 879 TPTEMPRL "TPM TEMP RL";
CM_ SG_ 879 TPTEMPRR "TPM TEMP RR";
CM_ SG_ 879 TPTEMPSP "TPM TEMP SP";
CM_ BO_ 1048 "Reserve";
CM_ SG_ 1048 TPMID1_1 "TPM_ID1_1";
CM_ SG_ 1048 TPMID1_2 "TPM_ID1_2";
CM_ SG_ 1048 TPMID1_3 "TPM_ID1_3";
CM_ SG_ 1048 TPMID1_4 "TPM_ID1_4";
CM_ SG_ 1048 TPMTEMP1 "TPM TEMP_ID1";
CM_ SG_ 1048 TPM_PR1 "TPMS ID1 Tire pressure information";
CM_ SG_ 1048 TPBATLO1 "TPM SENSOR Battery low disp_ID1";
CM_ SG_ 1048 TPM_TH1 "TIRE PRESSURE THRESHOLD ID1";
CM_ SG_ 1048 TPM_IND1 "TPMS ID1 Tire indicate information";
CM_ SG_ 1048 TPTGTPR1 "TPM TARGET PRESSURE ID1";
CM_ BO_ 1062 "Reserve";
CM_ SG_ 1062 TPMID2_1 "TPM_ID2_1";
CM_ SG_ 1062 TPMID2_2 "TPM_ID2_2";
CM_ SG_ 1062 TPMID2_3 "TPM_ID2_3";
CM_ SG_ 1062 TPMID2_4 "TPM_ID2_4";
CM_ SG_ 1062 TPMTEMP2 "TPM TEMP_ID2";
CM_ SG_ 1062 TPM_PR2 "TPMS ID2 Tire pressure information";
CM_ SG_ 1062 TPBATLO2 "TPM SENSOR Battery low disp_ID2";
CM_ SG_ 1062 TPM_TH2 "TIRE PRESSURE THRESHOLD ID2";
CM_ SG_ 1062 TPM_IND2 "TPMS ID2 Tire indicate information";
CM_ SG_ 1062 TPTGTPR2 "TPM TARGET PRESSURE ID2";
CM_ BO_ 1064 "Reserve";
CM_ SG_ 1064 TPMID3_1 "TPM_ID3_1";
CM_ SG_ 1064 TPMID3_2 "TPM_ID3_2";
CM_ SG_ 1064 TPMID3_3 "TPM_ID3_3";
CM_ SG_ 1064 TPMID3_4 "TPM_ID3_4";
CM_ SG_ 1064 TPMTEMP3 "TPM TEMP_ID3";
CM_ SG_ 1064 TPM_PR3 "TPMS ID3 Tire pressure information";
CM_ SG_ 1064 TPBATLO3 "TPM SENSOR Battery low disp_ID3";
CM_ SG_ 1064 TPM_TH3 "TIRE PRESSURE THRESHOLD ID3";
CM_ SG_ 1064 TPM_IND3 "TPMS ID3 Tire indicate information";
CM_ SG_ 1064 TPTGTPR3 "TPM TARGET PRESSURE ID3";
CM_ BO_ 1066 "Reserve";
CM_ SG_ 1066 TPMID4_1 "TPM_ID4_1";
CM_ SG_ 1066 TPMID4_2 "TPM_ID4_2";
CM_ SG_ 1066 TPMID4_3 "TPM_ID4_3";
CM_ SG_ 1066 TPMID4_4 "TPM_ID4_4";
CM_ SG_ 1066 TPMTEMP4 "TPM TEMP_ID4";
CM_ SG_ 1066 TPM_PR4 "TPMS ID4 Tire pressure information";
CM_ SG_ 1066 TPBATLO4 "TPM SENSOR Battery low disp_ID4";
CM_ SG_ 1066 TPM_TH4 "TIRE PRESSURE THRESHOLD ID4";
CM_ SG_ 1066 TPM_IND4 "TPMS ID4 Tire indicate information";
CM_ SG_ 1066 TPTGTPR4 "TPM TARGET PRESSURE ID4";
CM_ BO_ 1068 "Reserve";
CM_ SG_ 1068 TPMID5_1 "TPM_ID5_1";
CM_ SG_ 1068 TPMID5_2 "TPM_ID5_2";
CM_ SG_ 1068 TPMID5_3 "TPM_ID5_3";
CM_ SG_ 1068 TPMID5_4 "TPM_ID5_4";
CM_ SG_ 1068 TPMTEMP5 "TPM TEMP_ID5";
CM_ SG_ 1068 TPM_PR5 "TPMS ID5 Tire pressure information";
CM_ SG_ 1068 TPBATLO5 "TPM SENSOR Battery low disp_ID5";
CM_ SG_ 1068 TPM_TH5 "TIRE PRESSURE THRESHOLD ID5";
CM_ SG_ 1068 TPM_IND5 "TPMS ID5 Tire indicate information";
CM_ SG_ 1068 TPTGTPR5 "TPM TARGET PRESSURE ID5";
CM_ BO_ 999 "Reserve";
CM_ SG_ 999 SPDL_SR "Auto Lock by Speed customize support R";
CM_ SG_ 999 SPDL_MR "Auto Lock by Speed customize mode R";
CM_ SG_ 999 SFTL_SR "Auto Lock by Shift from P customize support R";
CM_ SG_ 999 SFTL_MR "Auto Lock by Shift from P customize mode R";
CM_ SG_ 999 DOUL_SR "Auto Unlock by Driver Door customize support R";
CM_ SG_ 999 DOUL_MR "Auto Unlock by Driver Door customize mode R";
CM_ SG_ 999 A_L_SR "Automatic Door Lock customize support R";
CM_ SG_ 999 A_L_MR "Automatic Door Lock customize mode R";
CM_ SG_ 999 A_UL_SR "Automatic Door Unlock customize support R";
CM_ SG_ 999 A_UL_MR "Automatic Door Unlock customize mode R";
CM_ SG_ 999 R2PUL_SR "Remote 2-Press Unlock customize support R";
CM_ SG_ 999 R2PUL_MR "Remote 2-Press Unlock customize mode R";
CM_ SG_ 999 WLDO_SR "Wireless Lock When Door Opened customize support R";
CM_ SG_ 999 WLDO_MR "Wireless Lock When Door Opened customize mode R";
CM_ SG_ 999 LU_FL_SR "Lock/Unlock Feedback-Lights customize support R";
CM_ SG_ 999 LU_FL_MR "Lock/Unlock Feedback-Lights customize mode R";
CM_ SG_ 999 ARL_T_SR "Auto Relock Timer customize support R";
CM_ SG_ 999 ARL_T_MR "Auto Relock Timer customize mode R";
CM_ SG_ 999 LU_FT_SR "Lock/Unlock Feedback-Tone customize support R";
CM_ SG_ 999 LU_FT_MR "Lock/Unlock Feedback-Tone customize mode R";
CM_ SG_ 999 SDU_SR "Select doors to unlock customize support";
CM_ SG_ 999 SDU_MR "Select doors to unlock customize mode";
CM_ SG_ 999 SESS_SR "Entry and start system customize support";
CM_ SG_ 999 SESS_MR "Entry and start system customize support";
CM_ SG_ 999 LSS_SR "Headlamps-On Sensitivity customize support R";
CM_ SG_ 999 LSS_MR "Headlamps-On Sensitivity customize mode R";
CM_ SG_ 999 HL_T_SR "Headlamps Auto-Off Timer customize support R";
CM_ SG_ 999 HL_T_MR "Headlamps Auto-Off Timer customize mode R";
CM_ SG_ 999 DRL_SR "Daytime Running Lights customize support R";
CM_ SG_ 999 DRL_MR "Daytime Running Lights customize mode R";
CM_ SG_ 999 IL_T_SR "Interior Lights Off Timer customize support R";
CM_ SG_ 999 IL_T_MR "Interior Lights Off Timer customize mode R";
CM_ SG_ 999 TITEC1SR "Steering Column Adjust When Exit customize support R";
CM_ SG_ 999 TITEC1MR "Steering Column Adjust When Exit customize mode R";
CM_ SG_ 999 DSEE_SR "Driver's Seat Easy-Exit Slide customize support R";
CM_ SG_ 999 DSEE_MR "Driver's Seat Easy-Exit Slide customize mode R";
CM_ SG_ 999 PBDOA_SR "Power back door opening adjust customize support";
CM_ SG_ 999 PBDOA_MR "Power back door opening adjust customize mode";
CM_ SG_ 999 DSAL_SR "Driver's Seat Easy-Exit Lift customize support R";
CM_ SG_ 999 DSAL_MR "Driver's Seat Easy-Exit Lift customize mode R";
CM_ SG_ 999 KPF_SR "Automatic Profile Change customize support R";
CM_ SG_ 999 KPF_MR "Automatic Profile Change customize mode R";
CM_ SG_ 999 TEIAN1SR "Proposal Services customize support R";
CM_ SG_ 999 TEIAN1MR "Proposal Services customize mode R";
CM_ SG_ 999 PSN_SR "Personalization customize support R";
CM_ SG_ 999 PSN_MR "Personalization customize mode R";
CM_ SG_ 999 SFL_SR "Auto Seat Temp. FR L customize support";
CM_ SG_ 999 SFL_MR "Auto Seat Temp. FR L customize mode";
CM_ SG_ 999 SFR_SR "Auto Seat Temp. FR R customize support";
CM_ SG_ 999 SFR_MR "Auto Seat Temp. FR R customize mode";
CM_ SG_ 999 SHRL_SR "Auto Seat Heater Temp. RR L customize support";
CM_ SG_ 999 SHRL_MR "Auto Seat Heater Temp. RR L customize mode";
CM_ SG_ 999 SHRR_SR "Auto Seat Heater Temp. RR R customize support";
CM_ SG_ 999 SHRR_MR "Auto Seat Heater Temp. RR R customize mode";
CM_ SG_ 999 SWHTS_SR "Auto Heated Str Wheel Time customize support";
CM_ SG_ 999 SWHTS_MR "Auto Heated Str Wheel Time customize support";
CM_ SG_ 999 SSS_SR "Smog Sensor Sensitivity customize support";
CM_ SG_ 999 SSS_MR "Smog Sensor Sensitivity customize mode";
CM_ SG_ 999 AACM_SR "Auto A/C Mode customize support";
CM_ SG_ 999 AACM_MR "Auto A/C Mode customize mode";
CM_ SG_ 999 EVM_SR "Efficient Ventilation Mode customize support";
CM_ SG_ 999 EVM_MR "Efficient Ventilation Mode customize mode";
CM_ BO_ 792 "Reserve";
CM_ SG_ 792 SPWNGMID "speaker warning MID display request";
CM_ SG_ 792 SPWNGTT "speaker warning telltale ON request";
CM_ BO_ 106 "Reserve";
CM_ SG_ 106 VXFREF "FR wheel speed sensor invalid or error flag";
CM_ SG_ 106 VXFR "FR wheel speed";
CM_ SG_ 106 VXFLEF "FL wheel speed sensor invalid or error flag";
CM_ SG_ 106 VXFL "FL wheel speed";
CM_ SG_ 106 VXRREF "RR wheel speed sensor invalid error flag";
CM_ SG_ 106 VXRR "RR wheel speed";
CM_ SG_ 106 VXRLEF "RL wheel speed sensor invalid or error flag";
CM_ SG_ 106 VXRL "RL wheel speed";
CM_ SG_ 106 RRDLVL "Road Rough Level";
CM_ SG_ 106 RRD_CRK "Crack Road Surface Information";
CM_ SG_ 106 RRDLVL_D "Dart Road Rough Level";
CM_ SG_ 106 RRD_STP "Step Road Surface Information";
CM_ BO_ 105 "Reserve";
CM_ SG_ 105 VSC_GXF "Anteroposterior G sensor abnormality state";
CM_ SG_ 105 VSC_GXIV "Anteroposterior G sensor invalidity state";
CM_ SG_ 105 VSC_GYF "Right and left G sensor abnormality state";
CM_ SG_ 105 VSC_GYIV "Right and left G sensor is in an invalid state";
CM_ SG_ 105 VSC_YAWS "Yawrate sensor invalidity state";
CM_ SG_ 105 VSC_YAWF "Yawrate sensor abnormality state";
CM_ SG_ 105 V_GXHR0 "Anteroposterior G sensor high-resolusion level (it has been revised)";
CM_ SG_ 105 V_GYHR0 "Right and left G sensor high-resolusion level (it has been revised)";
CM_ SG_ 105 V_YR1HR0 "Yawrate sensor 1 high resolusion signal(it has been revised)";
CM_ BO_ 158 "Reserve";
CM_ SG_ 158 SP1S "Vehicle speed (SP1) status flag";
CM_ SG_ 158 GVSPDINV "guess viechle speed invalid flag";
CM_ SG_ 158 SP1P "Vehicle speed pulse signal integrated value";
CM_ SG_ 158 SP1 "Vehicle speed (SP1)";
CM_ SG_ 158 GVSPD "guess viechle speed";
CM_ SG_ 158 PWCF "Pressure of Wheel Cylinder error flag";
CM_ SG_ 158 PWC "Pressure of Wheel Cylinder";
CM_ SG_ 158 PWCS "Pressure of Wheel Cylinder invalid flag";
CM_ SG_ 158 PMCF "Pressure of Master Cylinder error flag";
CM_ SG_ 158 PMCS "Pressure of Master Cylinder invalid flag";
CM_ SG_ 158 PMC "Pressure of Master Cylinder";
CM_ BO_ 183 "Reserve";
CM_ SG_ 183 VWPSUMFR "FR wheel wheel speed pulse integrated value";
CM_ SG_ 183 VWPSUMFL "FL wheel wheel speed pulse integrated value";
CM_ SG_ 183 VWPSUMRR "RR wheel wheel speed pulse integrated value";
CM_ SG_ 183 VWPSUMRL "RL wheel wheel speed pulse integrated value";
CM_ SG_ 183 ABSOPE "Under ABS control";
CM_ SG_ 183 TRCOPE "Under TRC control";
CM_ SG_ 183 VSCACT "Under VSC control";
CM_ BO_ 1537 "Reserve";
CM_ SG_ 1537 PWD_EQ "Driver's P/W Equipment Information";
CM_ SG_ 1537 PWP_EQ "Passenger's seat P/W Equipment Information";
CM_ SG_ 1537 PWR_EQ "Rear right seat P/W Equipment Information";
CM_ SG_ 1537 PWL_EQ "Rear left seat P/W Equipment Information";
CM_ SG_ 1537 SR_EQ "S/R Equipment Information";
CM_ SG_ 1537 SR_VARI "S/R variation";
CM_ SG_ 1537 PWD_AREA "Driver's seat P/W position area";
CM_ SG_ 1537 PWP_AREA "Passenger's seat P/W position area";
CM_ SG_ 1537 PWR_AREA "Rear right seat P/W position area";
CM_ SG_ 1537 PWL_AREA "Rear left seat P/W position area";
CM_ SG_ 1537 SR_AREA "S/R position area";
CM_ BO_ 761 "Reserve";
CM_ SG_ 761 FRWIPOPE "Front wiper operation state";
CM_ SG_ 761 FRWASH "Front washer operation state";
CM_ SG_ 761 RRWIPOPE "Rear wiper operation state";
CM_ SG_ 761 RRWASH "Rear washer operation state";
CM_ BO_ 638 "Reserve";
CM_ SG_ 638 YR_KLEG "Remote E/G Start System Control Signal";
CM_ BO_ 895 "Reserve";
CM_ SG_ 895 BASEMDC1 "Basic Model Code 1st";
CM_ SG_ 895 BASEMDC2 "Basic Model Code 2nd";
CM_ SG_ 895 BASEMDC3 "Basic Model Code 3rd";
CM_ SG_ 895 BASEMDC4 "Basic Model Code 4th";
CM_ SG_ 895 BASEMDC5 "Basic Model Code 5th";
CM_ SG_ 895 BASEMDC6 "Basic Model Code 6th";
CM_ SG_ 895 BASEMDC7 "Basic Model Code 7th";
CM_ BO_ 906 "Reserve";
CM_ SG_ 906 BODY "body shape";
CM_ SG_ 906 ENGINE "engine type";
CM_ SG_ 906 GEAR "gear mechanism";
CM_ SG_ 906 GRADE "grade";
CM_ SG_ 906 POP_NAME "popular name";
CM_ BO_ 134 "Reserve";
CM_ SG_ 134 W_STPZ "STP switch signal";
CM_ SG_ 134 FI_STP "STP switch invalid signal";
CM_ BO_ 478 "Reserve";
CM_ SG_ 478 ADIM2 "Auto dimmer signal (Using Con-light Sensor/SW)";
CM_ BO_ 479 "Reserve";
CM_ SG_ 479 F_STPLP "State of operating the stop lamp";
CM_ SG_ 479 BVWRSW_V "VCWARSW valid flag";
CM_ SG_ 479 BVWRSW "Brake vacuum warning state";
CM_ SG_ 479 BPWRSW_V "BRKPADSW valid flag";
CM_ SG_ 479 BPWRSW "Brake pad wear (PIND) warning status";
CM_ BO_ 872 "Reserve";
CM_ SG_ 872 TITE_FNC "Tilt & Telescopic function presence";
CM_ SG_ 872 TITE_VLD "Tilt & Telescopic Valid/Invalid signal";
CM_ SG_ 872 RES_PG "Impact Detection Setting Response";
CM_ SG_ 872 HED_FNC "Head Position SW function presence";
CM_ SG_ 872 TAL_FNC "Tail Position SW function presence";
CM_ SG_ 872 AUT_FNC "Auto Position SW function presence";
CM_ SG_ 872 DRL_FNC "DRL Position SW function presence";
CM_ SG_ 872 OFF_FNC "OFF Position SW function presence";
CM_ SG_ 872 FOG_FNC "Fr Fog Lamp function presence";
CM_ SG_ 872 RFG_FNC "Rr Fog Lamp function presence";
CM_ SG_ 872 HED_EN "Head Position SW enable";
CM_ SG_ 872 TAL_EN "Tail Position SW enable";
CM_ SG_ 872 AUT_EN "Auto Position SW enable";
CM_ SG_ 872 DRL_EN "DRL Position SW enable";
CM_ SG_ 872 OFF_EN "OFF Position SW enable";
CM_ SG_ 872 FOG_EN "Fr Fog Lamp enable";
CM_ SG_ 872 RFG_EN "Rr Fog Lamp enable";
CM_ SG_ 872 V_WIPDB "Wiper deicer enable";
CM_ SG_ 872 LSW_STS "Headlamp switch selection status";
CM_ SG_ 872 FOG_STS "Fr Foglamp switch selection status";
CM_ SG_ 872 RFG_STS "Rr Foglamp switch selection status";
CM_ SG_ 872 V_WIPD "Wiper Deicer enable";
CM_ SG_ 872 PBD_PRE "-";
CM_ SG_ 872 PBDOPPOS "-";
CM_ SG_ 872 PBD_STS "-";
CM_ SG_ 872 PWL_PRE "PWL Presence/absence ";
CM_ SG_ 872 PWL_VLD "PWL Valid/Invalid";
CM_ SG_ 872 PWL_STS "PWL Status";
CM_ SG_ 872 PBD_VLD "-";
CM_ SG_ 872 WSVS_FNC "Service Position Type";
CM_ SG_ 872 WSVS_VLD "Service Position Operation enable";
CM_ SG_ 872 WSVS_STS "Service Position status";
CM_ SG_ 872 M_FNC "Mirror adjustment function presence";
CM_ SG_ 872 M_VLD "Mirror adjustment enable";
CM_ SG_ 872 MLR_FNC "Mirror left-right selection function presence";
CM_ SG_ 872 MLR_VLD "Mirror left-right selection enable";
CM_ SG_ 872 MLR_STS "Mirror left-right selection state";
CM_ SG_ 872 MRTR_FNC "Outer mirror power folding function presence";
CM_ SG_ 872 ARTR_FNC "Outer mirror AUTO power folding function presence";
CM_ SG_ 872 MRTR_VLD "Outer mirror power folding enable";
CM_ SG_ 872 ARTR_VLD "Outer mirror AUTO power folding enable";
CM_ SG_ 872 MRTR_STS "Outer mirror power folding state";
CM_ SG_ 872 RLM_FNC "Reverse-linked selection function presence";
CM_ SG_ 872 RLM_VLD "Reverse-linked selection enable";
CM_ SG_ 872 RLM_STS "Reverse-linked selection state";
CM_ SG_ 872 ARTR_STS "AUTO status of outer mirror power folding";
CM_ SG_ 872 DRGSNABN "G sensor error";
CM_ SG_ 872 RES_PCON "Continuous Record while Charging Setting Response";
CM_ SG_ 872 SL_MRHTZ "MIRROR HEATER SW Select information";
CM_ SG_ 872 RC2OSW "Rear Center side 2ndrow seat Occupied SW signal";
CM_ SG_ 872 CFOSW "Frontcenter's seat Occupied SW signal";
CM_ SG_ 872 LTOPE_AD "Light Operate Advisary";
CM_ SG_ 872 RR2OSW "Rear Right side 2ndrow seat Occupied SW signal";
CM_ SG_ 872 RL3OSW "Rear Left side 3rdrow seat Occupied SW signal";
CM_ SG_ 872 RL2OSW "Rear Left side 2ndrow seat Occupied SW signal";
CM_ SG_ 872 RC3OSW "Rear Center side 3rdrow seat Occupied SW signal";
CM_ SG_ 872 RR3OSW "Rear Right side 3rdrow seat Occupied SW signal";
CM_ BO_ 920 "Reserve";
CM_ SG_ 920 ILEMB_SR "Illuminated Emblem custmize support";
CM_ SG_ 920 ILEMB_MR "Illuminated Emblem custmize mode";
CM_ SG_ 920 SOCHL_SR "Charge Illumination Lamp custmize support";
CM_ SG_ 920 SOCHL_MR "Charge Illumination Lamp custmize mode";
CM_ SG_ 920 PSDBV_MR "PSD Buzzer Volume custmize mode";
CM_ SG_ 920 PSDBV_SR "PSD Buzzer Volume custmize support";
CM_ SG_ 920 HIDTC_SR "Hidden Tech Hover Function customize support";
CM_ SG_ 920 HIDTC_MR "Hidden Tech Hover Function customize mode";
CM_ SG_ 920 HIDLV_SR "Hidden tech hover response level customize support";
CM_ SG_ 920 HIDLV_MR "Hidden tech hover response level customize mode";
CM_ SG_ 920 APULK_MR "Approach Auto Unlock customize mode";
CM_ SG_ 920 APULK_SR "Approach Auto Unlock customize support";
CM_ SG_ 920 DKYSW_MR "Digital key ON/OFF setting customize mode";
CM_ SG_ 920 DKYSW_SR "Digital key ON/OFF setting customize support";
CM_ SG_ 920 ILANIA_S "Interior illumination Anime 1 support";
CM_ SG_ 920 ILANIA_M "Interior illumination Anime 1 mode";
CM_ SG_ 920 ILANIB_S "Interior illumination Anime 2 support";
CM_ SG_ 920 ILANIB_M "Interior illumination Anime 2 mode";
CM_ SG_ 920 ILANIC_S "Interior illumination Anime 3 support";
CM_ SG_ 920 ILANIC_M "Interior illumination Anime 3 mode";
CM_ SG_ 920 ILANID_S "Interior illumination Anime 4 support";
CM_ SG_ 920 ILANID_M "Interior illumination Anime 4 mode";
CM_ SG_ 920 ILANIE_S "Interior illumination Anime 5 support";
CM_ SG_ 920 ILANIE_M "Interior illumination Anime 5 mode";
CM_ SG_ 920 ILANIF_S "Interior illumination Anime 6 support";
CM_ SG_ 920 ILANIF_M "Interior illumination Anime 6 mode";
CM_ SG_ 920 PBDHF_MR "PBD Hand Free customize mode";
CM_ SG_ 920 PBDHF_SR "PBD Hand Free customize support";
CM_ SG_ 920 PBD_MR "PBD Function customize mode";
CM_ SG_ 920 PBD_SR "PBD Function customize support";
CM_ SG_ 920 PTLHF_MR "PTL Hand Free customize mode";
CM_ SG_ 920 PTLHF_SR "PTL Hand Free customize support";
CM_ SG_ 920 RSR_MR "Rear Seat Reminder customize mode";
CM_ SG_ 920 RSR_SR "Rear Seat Reminder customize support";
CM_ SG_ 920 SDLHF_MR "PSD(L) Hand Free customize mode";
CM_ SG_ 920 SDLHF_SR "PSD(L) Hand Free customize support";
CM_ SG_ 920 SDRHF_MR "PSD(R) Hand Free customize mode";
CM_ SG_ 920 SDRHF_SR "PSD(R) Hand Free customize support";
CM_ SG_ 920 WALK_MR "Walk Away Lock customize mode";
CM_ SG_ 920 WALK_SR "Walk Away Lock customize support";
CM_ BO_ 874 "Reserve";
CM_ SG_ 874 DM_M_SW "Drive Mode minus switch for 2 contact switch(DMS-)";
CM_ SG_ 874 DM_MVLD "Drive Mode minus switch  valid signal for 2 contact switch(DMS-)";
CM_ SG_ 874 DM_P_SW "Drive Mode plus switch for 2 contact switch(DMS+)";
CM_ SG_ 874 DM_PVLD "Drive Mode plus switch valid signal for 2 contact switch(DMS+)";
CM_ SG_ 874 DM_SCVLD "Drive Mode shortcut switch valid signal";
CM_ SG_ 874 PCLMTRCA "Power Charging Lid Meter caution request";
CM_ SG_ 874 WM_STS "Fr Wiper Operation Status";
CM_ SG_ 874 WM_TRG "Fr Wiper SW Operation Signal";
CM_ SG_ 874 DM_SC_SW "Drive Mode shortcut switch operation information";
CM_ SG_ 874 WM_DSTS "Front Wiper Default State";
CM_ SG_ 874 WVR_FNC "Front Wiper Type";
CM_ SG_ 874 WVR_VLD "Front Wiper enable";
CM_ SG_ 874 WVR_STS "Front Wiper AUTO Sensitivity or INT Interval Status";
CM_ SG_ 874 WRSW_FNC "Rear Washer Type";
CM_ SG_ 874 WCSW_FNC "Camera Washer Type";
CM_ SG_ 874 WRSW_VLD "Rear Washer Operation enable";
CM_ SG_ 874 WRSW_STS "Rear Washerl Status";
CM_ SG_ 874 WR_FNC "Rear Wiper Type";
CM_ SG_ 874 WR_VLD "Rear Wiper Operation enable";
CM_ SG_ 874 WDI_FNC "Wiper Deicer Type";
CM_ SG_ 874 WR_STS "Rear Wiper Status";
CM_ SG_ 874 WDI_VLD "Wiper Deicer Operation enable";
CM_ SG_ 874 WDI_STS "Wiper Deicer Status";
CM_ SG_ 874 CFBCKL "Frontcenter's seat belt buckle switch status";
CM_ SG_ 874 CR2BCKL "Rear Center side 2ndrow seat belt buckle switch status";
CM_ SG_ 874 CR3BCKL "Rear Center side 3rdrow seat belt buckle switch status";
CM_ SG_ 874 DBKLSW "Driver's seat belt buckle switch status";
CM_ SG_ 874 LR2BCKL "Rear Left side 2ndrow seat belt buckle switch status";
CM_ SG_ 874 LR3BCKL "Rear Left side 3rdrow seat belt buckle switch status";
CM_ SG_ 874 RR2BCKL "Rear Right side 2ndrow seat belt buckle switch status";
CM_ SG_ 874 RR3BCKL "Rear Right side 3rdrow seat belt buckle switch status";
CM_ SG_ 874 REVSW2 "Reverse SW";
CM_ SG_ 874 HSW_PVM "Camera SW";
CM_ BO_ 924 "Reserve";
CM_ SG_ 924 RECRNOFF "Record reason IG-OFF";
CM_ SG_ 924 FAV_FNC "Favorite function availability information";
CM_ SG_ 924 CHG_FUNC " MET/MM operation switching function availability information";
CM_ SG_ 924 GSNSOFF "G Sensor OFF Request";
CM_ SG_ 924 DRBDBABN "Drive recorder malfunction notification";
CM_ BO_ 1280 "Reserve";
CM_ SG_ 1280 SPT_OPE "Front Active Spats operation request status";
CM_ SG_ 1280 SPTWNG "Front Active Spats warning";
CM_ BO_ 878 "Reserve";
CM_ SG_ 878 BZ_MSEAT "Buzzer request for seat memory";
CM_ SG_ 878 KSSFAIL "Kick Sensor Fail";
CM_ SG_ 878 PCLPOSIL "Power Charging Lid Position (Left)";
CM_ SG_ 878 PCLPOSIR "Power Charging Lid Position (Right)";
CM_ SG_ 878 PCLEQPL "Power Charging Lid Equipment (Left)";
CM_ SG_ 878 PCLEQPR "Power Charging Lid Equipment (Right)";
CM_ SG_ 878 LPCL_CRQ "The electric charge lid left shut demand reception";
CM_ SG_ 878 RPCL_CRQ "The electric charge lid right - shut demand receptio";
CM_ SG_ 878 LPCL_ORQ "The electric charge lid left - open demand reception";
CM_ SG_ 878 RPCL_ORQ "The electric charge lid right - open demand reception";
CM_ SG_ 878 LPCL_OPE "Power Charging Lid left Opening and shutting working conditions reception";
CM_ SG_ 878 RPCL_OPE "Power Charging Lid right  Opening and shutting working conditions reception";
CM_ BO_ 831 "Reserve";
CM_ SG_ 831 R_AC_ST "RRC AC status";
CM_ SG_ 831 R_SYS_2 "RRC System status 2";
CM_ BO_ 978 "Reserve";
CM_ SG_ 978 R_FTE_ST "RRC Feature status";
CM_ SG_ 978 R_BD_ST "RRC Body status";
CM_ SG_ 978 R_TIME "RRC Time status";
CM_ BO_ 1017 "Reserve";
CM_ SG_ 1017 R_INT_ST "RRC INT status";
CM_ BO_ 1024 "Reserve";
CM_ SG_ 1024 R_LMP_ST "RRC Lamp status";
CM_ SG_ 1024 R_SDE_ST "RRC Shade status";
CM_ SG_ 1024 R_SYS_3 "RRC System status 3";
CM_ BO_ 1028 "Reserve";
CM_ SG_ 1028 R_ST_ST "RRC Seat status";
CM_ SG_ 1028 R_SYS_1 "RRC System status 1";
CM_ BO_ 963 "Reserve";
CM_ SG_ 963 VSI_L8A " [L8A] OUTSIDE REAR VIEW MIRROR";
CM_ BO_ 848 "Reserve";
CM_ SG_ 848 EIC_EQP "Integrated Cabin Control Equipment Information";
CM_ SG_ 848 EIC_FEQP "Integrated Cabin Control Fragrance Equipment Information";
CM_ SG_ 848 EIC_SEQP "Integrated Cabin Control Shade Equipment Information";
CM_ SG_ 848 EIC_IEQP "Integrated Cabin Control Illumination Equipment Information";
CM_ SG_ 848 EIC_BEQP "Integrated Cabin Control BGM Equipment Information";
CM_ SG_ 848 QIC_BREQ "Integrated Cabin Control BGM Request";
CM_ SG_ 848 QIC_DISP "Integrated Cabin Control Interrupt Screen Display Request Pattern";
CM_ SG_ 848 QIC_BVOL "Integrated Cabin Control BGM Volume";
CM_ SG_ 848 QIC_DIS "Integrated Cabin Control Interrupt Screen Display Request";
CM_ SG_ 848 EIC_DEQP "Integrated Cabin Control Dseat memory Equipment Information";
CM_ SG_ 848 EIC_PEQP "Integrated Cabin Control Pseat memory Equipment Information";
CM_ SG_ 848 EIC_REQP "Integrated Cabin Control RRseat memory Equipment Information";
CM_ SG_ 848 EIC_LEQP "Integrated Cabin Control RLseat memory Equipment Information";
CM_ SG_ 848 AIC_DRC "Integrated Cabin Control Dseat Setting Change Acceptance";
CM_ SG_ 848 AIC_DMRC "Integrated Cabin Control Dseat Mode Change Acceptance";
CM_ SG_ 848 AIC_DFRC "Integrated Cabin Control Dseat Fragrance Setting Acceptance";
CM_ SG_ 848 AIC_DBRC "Integrated Cabin Control Dseat memory Setting Acceptance";
CM_ SG_ 848 AIC_DRRC "Integrated Cabin Control Dseat BGM Setting Acceptance";
CM_ SG_ 848 SIC_DMST "Integrated Cabin Control Dseat Mode State";
CM_ SG_ 848 SIC_DCST "Integrated Cabin Control Dseat Current State";
CM_ SG_ 848 SIC_DFFL "Integrated Cabin Control Dseat Fragrance Existence Linked with Focus Mode";
CM_ SG_ 848 SIC_DFFP "Integrated Cabin Control Dseat Fragrance Pattern Linked with Focus Mode";
CM_ SG_ 848 SIC_DFRL "Integrated Cabin Control Dseat Fragrance Existence Linked with Relax Mode ";
CM_ SG_ 848 SIC_DFRP "Integrated Cabin Control Dseat Fragrance Pattern Linked with Relax Mode";
CM_ SG_ 848 SIC_DF5L "Integrated Cabin Control Dseat Fragrance Existence Linked with Mode 5";
CM_ SG_ 848 SIC_DFDL "Integrated Cabin Control Dseat Fragrance Existence Linked with Dream Mode";
CM_ SG_ 848 SIC_DFDP "Integrated Cabin Control Dseat Fragrance Pattern Linked with Dream Mode";
CM_ SG_ 848 SIC_DF4L "Integrated Cabin Control Dseat Fragrance Existence Linked with Mode 4";
CM_ SG_ 848 SIC_DF4P "Integrated Cabin Control Dseat Fragrance Pattern Linked with Mode 4";
CM_ SG_ 848 SIC_DF5P "Integrated Cabin Control Dseat Fragrance Pattern Linked with Mode 5";
CM_ SG_ 848 SIC_DBFL "Integrated Cabin Control Dseat BGM Existence Linked with Focus Mode";
CM_ SG_ 848 SIC_DBFP "Integrated Cabin Control Dseat BGM Pattern Linked with Focus Mode";
CM_ SG_ 848 SIC_DBRL "Integrated Cabin Control Dseat BGM Existence Linked with Relax Mode";
CM_ SG_ 848 SIC_DBRP "Integrated Cabin Control Dseat BGM Pattern Linked with Relax Mode";
CM_ SG_ 848 SIC_DB5L "Integrated Cabin Control Dseat BGM Existence Linked with Mode 5";
CM_ SG_ 848 SIC_DBDL "Integrated Cabin Control Dseat BGM Existence Linked with Dream Mode";
CM_ SG_ 848 SIC_DBDP "Integrated Cabin Control Dseat BGM Pattern Linked with Dream Mode";
CM_ SG_ 848 SIC_DB4L "Integrated Cabin Control Dseat BGM Existence Linked with Mode 4";
CM_ SG_ 848 SIC_DB4P "Integrated Cabin Control Dseat BGM Pattern Linked with Mode 4";
CM_ SG_ 848 SIC_DB5P "Integrated Cabin Control Dseat BGM Pattern Linked with Mode 5";
CM_ SG_ 848 SIC_DRFL "Integrated Cabin Control Dseat Memory Seat Setting Existence Linked with Focus Mode";
CM_ SG_ 848 SIC_DRRL "Integrated Cabin Control Dseat Memory Seat Setting Existence Linked with Relax Mode";
CM_ SG_ 848 SIC_DRDL "Integrated Cabin Control Dseat Memory Seat Setting Existence Linked with Dream Mode";
CM_ SG_ 848 SIC_DR4L "Integrated Cabin Control Dseat Memory Seat Setting Existence Linked with Mode 4";
CM_ SG_ 848 SIC_DR5L "Integrated Cabin Control Dseat Memory Seat Setting Existence Linked with Mode 5";
CM_ SG_ 848 SIC_DRFK "Integrated Cabin Control Dseat Memory State (Focus)";
CM_ SG_ 848 SIC_DRRK "Integrated Cabin Control Dseat Memory State (Relax)";
CM_ SG_ 848 SIC_DRDK "Integrated Cabin Control Dseat Memory State (Dream)";
CM_ SG_ 848 SIC_DR4K "Integrated Cabin Control Dseat Memory State (Mode 4)";
CM_ SG_ 848 SIC_DR5K "Integrated Cabin Control Dseat Memory State (Mode 5)";
CM_ SG_ 848 AIC_PRC "Integrated Cabin Control Pseat Setting Change Acceptance";
CM_ SG_ 848 AIC_PMRC "Integrated Cabin Control Pseat Mode Change Acceptance";
CM_ SG_ 848 AIC_PFRC "Integrated Cabin Control Pseat Fragrance Setting Acceptance";
CM_ SG_ 848 AIC_PBRC "Integrated Cabin Control Pseat memory Setting Acceptance";
CM_ SG_ 848 AIC_PRRC "Integrated Cabin Control Pseat BGM Setting Acceptance";
CM_ SG_ 848 SIC_PMST "Integrated Cabin Control Pseat Mode State";
CM_ SG_ 848 SIC_PCST "Integrated Cabin Control Pseat Current State";
CM_ SG_ 848 SIC_PFFL "Integrated Cabin Control Pseat Fragrance Existence Linked with Focus Mode";
CM_ SG_ 848 SIC_PFFP "Integrated Cabin Control Pseat Fragrance Pattern Linked with Focus Mode";
CM_ SG_ 848 SIC_PFRL "Integrated Cabin Control Pseat Fragrance Existence Linked with Relax Mode ";
CM_ SG_ 848 SIC_PFRP "Integrated Cabin Control Pseat Fragrance Pattern Linked with Relax Mode";
CM_ SG_ 848 SIC_PF5L "Integrated Cabin Control Pseat Fragrance Existence Linked with Mode 5";
CM_ SG_ 848 SIC_PFDL "Integrated Cabin Control Pseat Fragrance Existence Linked with Dream Mode";
CM_ SG_ 848 SIC_PFDP "Integrated Cabin Control Pseat Fragrance Pattern Linked with Dream Mode";
CM_ SG_ 848 SIC_PF4L "Integrated Cabin Control Pseat Fragrance Existence Linked with Mode 4";
CM_ SG_ 848 SIC_PF4P "Integrated Cabin Control Pseat Fragrance Pattern Linked with Mode 4";
CM_ SG_ 848 SIC_PF5P "Integrated Cabin Control Pseat Fragrance Pattern Linked with Mode 5";
CM_ SG_ 848 SIC_PBFL "Integrated Cabin Control Pseat BGM Existence Linked with Focus Mode";
CM_ SG_ 848 SIC_PBFP "Integrated Cabin Control Pseat BGM Pattern Linked with Focus Mode";
CM_ SG_ 848 SIC_PBRL "Integrated Cabin Control Pseat BGM Existence Linked with Relax Mode";
CM_ SG_ 848 SIC_PBRP "Integrated Cabin Control Pseat BGM Pattern Linked with Relax Mode";
CM_ SG_ 848 SIC_PB5L "Integrated Cabin Control Pseat BGM Existence Linked with Mode 5";
CM_ SG_ 848 SIC_PBDL "Integrated Cabin Control Pseat BGM Existence Linked with Dream Mode";
CM_ SG_ 848 SIC_PBDP "Integrated Cabin Control Pseat BGM Pattern Linked with Dream Mode";
CM_ SG_ 848 SIC_PB4L "Integrated Cabin Control Pseat BGM Existence Linked with Mode 4";
CM_ SG_ 848 SIC_PB4P "Integrated Cabin Control Pseat BGM Pattern Linked with Mode 4";
CM_ SG_ 848 SIC_PB5P "Integrated Cabin Control Pseat BGM Pattern Linked with Mode 5";
CM_ SG_ 848 SIC_PRFL "Integrated Cabin Control Pseat Memory Seat Setting Existence Linked with Focus Mode";
CM_ SG_ 848 SIC_PRRL "Integrated Cabin Control Pseat Memory Seat Setting Existence Linked with Relax Mode";
CM_ SG_ 848 SIC_PRDL "Integrated Cabin Control Pseat Memory Seat Setting Existence Linked with Dream Mode";
CM_ SG_ 848 SIC_PR4L "Integrated Cabin Control Pseat Memory Seat Setting Existence Linked with Mode 4";
CM_ SG_ 848 SIC_PR5L "Integrated Cabin Control Pseat Memory Seat Setting Existence Linked with Mode 5";
CM_ SG_ 848 SIC_PRFK "Integrated Cabin Control Pseat Memory State (Focus)";
CM_ SG_ 848 SIC_PRRK "Integrated Cabin Control Pseat Memory State (Relax)";
CM_ SG_ 848 SIC_PRDK "Integrated Cabin Control Pseat Memory State (Dream)";
CM_ SG_ 848 SIC_PR4K "Integrated Cabin Control Pseat Memory State (Mode 4)";
CM_ SG_ 848 SIC_PR5K "Integrated Cabin Control Pseat Memory State (Mode 5)";
CM_ BO_ 850 "Reserve";
CM_ SG_ 850 AIC_RRC "Integrated Cabin Control RRseat Setting Change Acceptance";
CM_ SG_ 850 AIC_RMRC "Integrated Cabin Control RRseat Mode Change Acceptance";
CM_ SG_ 850 AIC_RFRC "Integrated Cabin Control RRseat Fragrance Setting Acceptance";
CM_ SG_ 850 AIC_RBRC "Integrated Cabin Control RRseat memory Setting Acceptance";
CM_ SG_ 850 AIC_RRRC "Integrated Cabin Control RRseat BGM Setting Acceptance";
CM_ SG_ 850 SIC_RMST "Integrated Cabin Control RRseat Mode State";
CM_ SG_ 850 SIC_RCST "Integrated Cabin Control RRseat Current State";
CM_ SG_ 850 SIC_RFFL "Integrated Cabin Control RRseat Fragrance Existence Linked with Focus Mode";
CM_ SG_ 850 SIC_RFFP "Integrated Cabin Control RRseat Fragrance Pattern Linked with Focus Mode";
CM_ SG_ 850 SIC_RFRL "Integrated Cabin Control RRseat Fragrance Existence Linked with Relax Mode ";
CM_ SG_ 850 SIC_RFRP "Integrated Cabin Control RRseat Fragrance Pattern Linked with Relax Mode";
CM_ SG_ 850 SIC_RF5L "Integrated Cabin Control RRseat Fragrance Existence Linked with Mode 5";
CM_ SG_ 850 SIC_RFDL "Integrated Cabin Control RRseat Fragrance Existence Linked with Dream Mode";
CM_ SG_ 850 SIC_RFDP "Integrated Cabin Control RRseat Fragrance Pattern Linked with Dream Mode";
CM_ SG_ 850 SIC_RF4L "Integrated Cabin Control RRseat Fragrance Existence Linked with Mode 4";
CM_ SG_ 850 SIC_RF4P "Integrated Cabin Control RRseat Fragrance Pattern Linked with Mode 4";
CM_ SG_ 850 SIC_RF5P "Integrated Cabin Control RRseat Fragrance Pattern Linked with Mode 5";
CM_ SG_ 850 SIC_RBFL "Integrated Cabin Control RRseat BGM Existence Linked with Focus Mode";
CM_ SG_ 850 SIC_RBFP "Integrated Cabin Control RRseat BGM Pattern Linked with Focus Mode";
CM_ SG_ 850 SIC_RBRL "Integrated Cabin Control RRseat BGM Existence Linked with Relax Mode";
CM_ SG_ 850 SIC_RBRP "Integrated Cabin Control RRseat BGM Pattern Linked with Relax Mode";
CM_ SG_ 850 SIC_RB5L "Integrated Cabin Control RRseat Fragrance Existence Linked with Mode 5";
CM_ SG_ 850 SIC_RBDL "Integrated Cabin Control RRseat BGM Existence Linked with Dream Mode";
CM_ SG_ 850 SIC_RBDP "Integrated Cabin Control RRseat BGM Pattern Linked with Dream Mode";
CM_ SG_ 850 SIC_RB4L "Integrated Cabin Control RRseat Fragrance Existence Linked with Mode 4";
CM_ SG_ 850 SIC_RB4P "Integrated Cabin Control RRseat Fragrance Pattern Linked with Mode 4";
CM_ SG_ 850 SIC_RB5P "Integrated Cabin Control RRseat Fragrance Pattern Linked with Mode 5";
CM_ SG_ 850 SIC_RRFL "Integrated Cabin Control RRseat Memory Seat Setting Existence Linked with Focus Mode";
CM_ SG_ 850 SIC_RRRL "Integrated Cabin Control RRseat Memory Seat Setting Existence Linked with Relax Mode";
CM_ SG_ 850 SIC_RRDL "Integrated Cabin Control RRseat Memory Seat Setting Existence Linked with Dream Mode";
CM_ SG_ 850 SIC_RR4L "Integrated Cabin Control RRseat Memory Seat Setting Existence Linked with Mode 4";
CM_ SG_ 850 SIC_RR5L "Integrated Cabin Control RRseat Memory Seat Setting Existence Linked with Mode 5";
CM_ SG_ 850 SIC_RRFK "Integrated Cabin Control RRseat Memory State (Focus)";
CM_ SG_ 850 SIC_RRRK "Integrated Cabin Control RRseat Memory State (Relax)";
CM_ SG_ 850 SIC_RRDK "Integrated Cabin Control RRseat Memory State (Dream)";
CM_ SG_ 850 SIC_RR4K "Integrated Cabin Control RRseat Memory State (Mode 4)";
CM_ SG_ 850 SIC_RR5K "Integrated Cabin Control RRseat Memory State (Mode 5)";
CM_ SG_ 850 AIC_LRC "Integrated Cabin Control RLseat Setting Change Acceptance";
CM_ SG_ 850 AIC_LMRC "Integrated Cabin Control RLseat Mode Change Acceptance";
CM_ SG_ 850 AIC_LFRC "Integrated Cabin Control RLseat Fragrance Setting Acceptance";
CM_ SG_ 850 AIC_LBRC "Integrated Cabin Control RLseat memory Setting Acceptance";
CM_ SG_ 850 AIC_LRRC "Integrated Cabin Control RLseat BGM Setting Acceptance";
CM_ SG_ 850 SIC_LMST "Integrated Cabin Control RLseat Mode State";
CM_ SG_ 850 SIC_LCST "Integrated Cabin Control RLseat Current State";
CM_ SG_ 850 SIC_LFFL "Integrated Cabin Control RLseat Fragrance Existence Linked with Focus Mode";
CM_ SG_ 850 SIC_LFFP "Integrated Cabin Control RLseat Fragrance Pattern Linked with Focus Mode";
CM_ SG_ 850 SIC_LFRL "Integrated Cabin Control RLseat Fragrance Existence Linked with Relax Mode ";
CM_ SG_ 850 SIC_LFRP "Integrated Cabin Control RLseat Fragrance Pattern Linked with Relax Mode";
CM_ SG_ 850 SIC_LF5L "Integrated Cabin Control RLseat Fragrance Existence Linked with Mode 5";
CM_ SG_ 850 SIC_LFDL "Integrated Cabin Control RLseat Fragrance Existence Linked with Dream Mode";
CM_ SG_ 850 SIC_LFDP "Integrated Cabin Control RLseat Fragrance Pattern Linked with Dream Mode";
CM_ SG_ 850 SIC_LF4L "Integrated Cabin Control RLseat Fragrance Existence Linked with Mode 4";
CM_ SG_ 850 SIC_LF4P "Integrated Cabin Control RLseat Fragrance Pattern Linked with Mode 4";
CM_ SG_ 850 SIC_LF5P "Integrated Cabin Control RLseat Fragrance Pattern Linked with Mode 5";
CM_ SG_ 850 SIC_LBFL "Integrated Cabin Control RLseat BGM Existence Linked with Focus Mode";
CM_ SG_ 850 SIC_LBFP "Integrated Cabin Control RLseat BGM Pattern Linked with Focus Mode";
CM_ SG_ 850 SIC_LBRL "Integrated Cabin Control RLseat BGM Existence Linked with Relax Mode";
CM_ SG_ 850 SIC_LBRP "Integrated Cabin Control RLseat BGM Pattern Linked with Relax Mode";
CM_ SG_ 850 SIC_LB5L "Integrated Cabin Control RLseat Fragrance Existence Linked with Mode 5";
CM_ SG_ 850 SIC_LBDL "Integrated Cabin Control RLseat BGM Existence Linked with Dream Mode";
CM_ SG_ 850 SIC_LBDP "Integrated Cabin Control RLseat BGM Pattern Linked with Dream Mode";
CM_ SG_ 850 SIC_LB4L "Integrated Cabin Control RLseat Fragrance Existence Linked with Mode 4";
CM_ SG_ 850 SIC_LB4P "Integrated Cabin Control RLseat Fragrance Pattern Linked with Mode 4";
CM_ SG_ 850 SIC_LB5P "Integrated Cabin Control RLseat Fragrance Pattern Linked with Mode 5";
CM_ SG_ 850 SIC_LRFL "Integrated Cabin Control RLseat Memory Seat Setting Existence Linked with Focus Mode";
CM_ SG_ 850 SIC_LRRL "Integrated Cabin Control RLseat Memory Seat Setting Existence Linked with Relax Mode";
CM_ SG_ 850 SIC_LRDL "Integrated Cabin Control RLseat Memory Seat Setting Existence Linked with Dream Mode";
CM_ SG_ 850 SIC_LR4L "Integrated Cabin Control RLseat Memory Seat Setting Existence Linked with Mode 4";
CM_ SG_ 850 SIC_LR5L "Integrated Cabin Control RLseat Memory Seat Setting Existence Linked with Mode 5";
CM_ SG_ 850 SIC_LRFK "Integrated Cabin Control RLseat Memory State (Focus)";
CM_ SG_ 850 SIC_LRRK "Integrated Cabin Control RLseat Memory State (Relax)";
CM_ SG_ 850 SIC_LRDK "Integrated Cabin Control RLseat Memory State (Dream)";
CM_ SG_ 850 SIC_LR4K "Integrated Cabin Control RLseat Memory State (Mode 4)";
CM_ SG_ 850 SIC_LR5K "Integrated Cabin Control RLseat Memory State (Mode 5)";
CM_ BO_ 851 "Reserve";
CM_ SG_ 851 ERS_EQP "Rear sunshade equipment";
CM_ SG_ 851 ARS_RC "Rear sunshade reception";
CM_ SG_ 851 RDK_FDAC "Digital key removal service ACK for the friend";
CM_ SG_ 851 RDK_OCAC "Digital key owner device change preonclination service ACK";
CM_ SG_ 851 ADK_CHGA "Digital key owner device change processing reception";
CM_ SG_ 851 ADK_FDWA "Digital key friend device deletion reception";
CM_ SG_ 851 ADK_ADLA "Digitalkey all delete reception";
CM_ SG_ 851 ADK_OWDA "Digital key owner delete reception";
CM_ SG_ 851 ADK_OWNA "Digitalkey owner checking reception";
CM_ SG_ 851 ADK_REGA "Digitalkey owner registration preonclination reception";
CM_ SG_ 851 ADK_STCA "Digitalkey owner device registration processing status confirmation reception";
CM_ SG_ 851 EDK_EQP "DigitalKey Equipment";
CM_ SG_ 851 RDK_OCRL "Digital key owner device change processing result";
CM_ SG_ 851 RDK_ADAC "Digital key all delete service ACK";
CM_ SG_ 851 RDK_ADRL "Digital key all delete result";
CM_ SG_ 851 RDK_ODAC "Digital key removal service ACK for the owner";
CM_ SG_ 851 RDK_ODRL "Digital key owner delete result";
CM_ SG_ 851 RDK_OGAC "Digital key owner device registration processing service ACK";
CM_ SG_ 851 RDK_OGRL "Digital key owner device registration processing result";
CM_ SG_ 851 RDK_ORAC "Digital key owner registration preonclination service ACK";
CM_ SG_ 851 RDK_ORRL "Digital key owner registration preonclination result";
CM_ SG_ 851 RDK_OWAC "Digital key owner checking service ACK";
CM_ SG_ 851 RDK_OWRL "Digital key owner checking response";
CM_ SG_ 851 RDK_RACK "DigitalKey certificatio request service ACK";
CM_ SG_ 851 RDK_CRL "DigitalKey certificated result";
CM_ SG_ 851 RSM_CRL "Smart key collation result";
CM_ SG_ 851 RSM_LARE "Smart key collation area result";
CM_ SG_ 851 RSM_LCMN "Smart key collation means result";
CM_ SG_ 851 RSM_LRNG "Smart key collation range result";
CM_ SG_ 851 RSM_LTID "The key ID that is targeted for a smart key result";
CM_ SG_ 851 RSM_RACK "Smart key collation demand service ACK";
CM_ SG_ 851 SDK_CNT "DigitalKey Contract state";
CM_ SG_ 851 SDK_PRG "DigitalKey Registration progress state";
CM_ SG_ 851 SDK_RGST "DigitalKey Registration state";
CM_ SG_ 851 SDK_IDME "DigitalKey Registered key ID";
CM_ SG_ 851 SDK_IDGR "Friend DigitalKey Deletion grace period transition informing display request key ID";
CM_ SG_ 851 SDK_IDER "Friend DigitalKey Deletion completed informing display request key ID";
CM_ SG_ 851 SLID_RSP "DigitalKey registration slotID# acquisition request";
CM_ SG_ 851 RDK_LTID "The key ID that is targeted for a digital key result";
CM_ SG_ 851 RDK_LARE "Digital key certificationarea result";
CM_ SG_ 851 RDK_LCMN "Digital key certification method result";
CM_ SG_ 851 RDK_LRNG "Digital key certification range result";
CM_ BO_ 955 "Reserve";
CM_ SG_ 955 B_CXJDG1 "Steering SW_MM signal path information";
CM_ SG_ 955 B_VOICES "SW info(VOICE)";
CM_ SG_ 955 B_A_MUTE "SW info(Audio Mute)";
CM_ SG_ 955 B_VOLDDN "SW info(VOLDOWN)";
CM_ SG_ 955 B_VOLUP "SW info(VOLUP)";
CM_ SG_ 955 B_SEEKDN "SW info(SEEKDOWN)";
CM_ SG_ 955 B_SEEKUP "SW info(SEEKUP)";
CM_ SG_ 955 B_VOL_LV "SW info(VOL Level)";
CM_ SG_ 955 R_PWR "Audio sw info(Power)";
CM_ SG_ 955 R_MODE_A "Audio sw info(Mode)";
CM_ SG_ 955 R_VOLUP "Audio sw info(Vol up)";
CM_ SG_ 955 R_VOLDN "Audio sw info(Vol down)";
CM_ SG_ 955 R_TUNEUP "Audio sw info(Vol tunetrack up)";
CM_ SG_ 955 R_TUNEDN "Audio sw info(Vol tunetrack down)";
CM_ SG_ 955 R_CHUP "Audio sw info(Ch up)";
CM_ SG_ 955 R_CHDN "Audio sw info(Ch down)";
CM_ SG_ 955 R_EXIST "Rear Controller Exist";
CM_ BO_ 481 "Reserve";
CM_ SG_ 481 TNLS "Turn lamp lighting state";
CM_ SG_ 481 TNLCOND "Turnsignal Condition";
CM_ BO_ 912 "Reserve";
CM_ SG_ 912 ACN_AMB "Ambient  temperature display signal";
CM_ SG_ 912 AC_AMB05 "Switch signal of 0 or 0.5 below decimal point of ambient temperature display";
CM_ BO_ 446 "Reserve";
CM_ SG_ 446 AMBDS "Ambient Temperature Display Signal";
CM_ BO_ 937 "Reserve";
CM_ SG_ 937 TNS "Turn lamp state";
CM_ SG_ 937 HZS "Hazard switch state";
CM_ SG_ 937 BAONUSER "BA on flag by user operation";
CM_ BO_ 2564431072 "Reserve";
CM_ BO_ 2564481052 "Reserve";
CM_ BO_ 2564431073 "Reserve";
CM_ BO_ 2564481308 "Reserve";
CM_ BO_ 2564550624 "Reserve";
CM_ BO_ 2564550625 "Reserve";
BA_DEF_ BO_  "GenMsgILSupport" ENUM  "No","Yes";
BA_DEF_ BO_  "GenMsgSendType" ENUM  "Cyclic","NotUsed","NotUsed","NotUsed","NotUsed","NotUsed","NotUsed","NotUsed","NoMsgSendType";
BA_DEF_ SG_  "GenSigSendType" ENUM  "Cyclic","OnWrite","OnWriteWithRepetition","OnChange","OnChangeWithRepetition","NotUsed","NotUsed","NoSigSendType";
BA_DEF_ BO_  "GenMsgCycleTime" INT 0 65535;
BA_DEF_ SG_  "GenSigStartValue" FLOAT 0 100000000000;
BA_DEF_ BO_  "GenMsgStartDelayTime" INT 0 100000;
BA_DEF_ BO_  "VFrameFormat" ENUM  "StandardCAN","ExtendedCAN","reserved","reserved","reserved","reserved","reserved","reserved","reserved","reserved","reserved","reserved","reserved","reserved","StandardCAN_FD","ExtendedCAN_FD";
BA_DEF_ BO_  "CANFD_BRS" ENUM  "0","1";
BA_DEF_ BO_  "NmAsrMessage" ENUM  "No","Yes";
BA_DEF_ BO_  "DiagState" ENUM  "No","Yes";
BA_DEF_ BO_  "DiagRequest" ENUM  "No","Yes";
BA_DEF_ BO_  "DiagResponse" ENUM  "No","Yes";
BA_DEF_ BO_  "DiagConnection" HEX 0 65535;
BA_DEF_ SG_  "SystemSignalLongSymbol" STRING ;
BA_DEF_DEF_  "GenMsgILSupport" "No";
BA_DEF_DEF_  "GenMsgSendType" "NoMsgSendType";
BA_DEF_DEF_  "GenSigSendType" "NoSigSendType";
BA_DEF_DEF_  "GenMsgCycleTime" 0;
BA_DEF_DEF_  "GenSigStartValue" 0;
BA_DEF_DEF_  "GenMsgStartDelayTime" 0;
BA_DEF_DEF_  "VFrameFormat" "";
BA_DEF_DEF_  "CANFD_BRS" "1";
BA_DEF_DEF_  "NmAsrMessage" "No";
BA_DEF_DEF_  "DiagState" "No";
BA_DEF_DEF_  "DiagRequest" "No";
BA_DEF_DEF_  "DiagResponse" "No";
BA_DEF_DEF_  "DiagConnection" 3000.00005758105;
BA_DEF_DEF_  "SystemSignalLongSymbol" "";
BA_ "GenMsgILSupport" BO_ 1019 1;
BA_ "GenMsgSendType" BO_ 1019 0;
BA_ "GenMsgCycleTime" BO_ 1019 1000;
BA_ "VFrameFormat" BO_ 1019 14;
BA_ "GenMsgILSupport" BO_ 331 1;
BA_ "GenMsgSendType" BO_ 331 0;
BA_ "GenMsgCycleTime" BO_ 331 100;
BA_ "VFrameFormat" BO_ 331 14;
BA_ "GenMsgILSupport" BO_ 1330 1;
BA_ "VFrameFormat" BO_ 1330 14;
BA_ "GenMsgILSupport" BO_ 1083 1;
BA_ "GenMsgSendType" BO_ 1083 0;
BA_ "GenMsgCycleTime" BO_ 1083 1000;
BA_ "VFrameFormat" BO_ 1083 14;
BA_ "GenMsgILSupport" BO_ 875 1;
BA_ "GenMsgSendType" BO_ 875 0;
BA_ "GenMsgCycleTime" BO_ 875 1000;
BA_ "VFrameFormat" BO_ 875 14;
BA_ "GenMsgILSupport" BO_ 990 1;
BA_ "GenMsgSendType" BO_ 990 0;
BA_ "GenMsgCycleTime" BO_ 990 1000;
BA_ "VFrameFormat" BO_ 990 14;
BA_ "GenMsgILSupport" BO_ 788 1;
BA_ "GenMsgSendType" BO_ 788 0;
BA_ "GenMsgCycleTime" BO_ 788 1000;
BA_ "VFrameFormat" BO_ 788 14;
BA_ "GenMsgILSupport" BO_ 635 1;
BA_ "GenMsgSendType" BO_ 635 0;
BA_ "GenMsgCycleTime" BO_ 635 1000;
BA_ "VFrameFormat" BO_ 635 14;
BA_ "GenMsgILSupport" BO_ 371 1;
BA_ "GenMsgSendType" BO_ 371 0;
BA_ "GenMsgCycleTime" BO_ 371 100;
BA_ "VFrameFormat" BO_ 371 14;
BA_ "GenMsgILSupport" BO_ 377 1;
BA_ "GenMsgSendType" BO_ 377 0;
BA_ "GenMsgCycleTime" BO_ 377 100;
BA_ "VFrameFormat" BO_ 377 14;
BA_ "GenMsgILSupport" BO_ 378 1;
BA_ "GenMsgSendType" BO_ 378 0;
BA_ "GenMsgCycleTime" BO_ 378 100;
BA_ "VFrameFormat" BO_ 378 14;
BA_ "GenMsgStartDelayTime" BO_ 502 248;
BA_ "GenMsgILSupport" BO_ 502 1;
BA_ "GenMsgSendType" BO_ 502 0;
BA_ "GenMsgCycleTime" BO_ 502 500;
BA_ "VFrameFormat" BO_ 502 14;
BA_ "GenMsgStartDelayTime" BO_ 1553 252;
BA_ "GenMsgILSupport" BO_ 1553 1;
BA_ "GenMsgSendType" BO_ 1553 0;
BA_ "GenMsgCycleTime" BO_ 1553 1000;
BA_ "VFrameFormat" BO_ 1553 14;
BA_ "GenMsgStartDelayTime" BO_ 1560 256;
BA_ "GenMsgILSupport" BO_ 1560 1;
BA_ "GenMsgSendType" BO_ 1560 0;
BA_ "GenMsgCycleTime" BO_ 1560 10000;
BA_ "VFrameFormat" BO_ 1560 14;
BA_ "GenMsgStartDelayTime" BO_ 1556 260;
BA_ "GenMsgILSupport" BO_ 1556 1;
BA_ "GenMsgSendType" BO_ 1556 0;
BA_ "GenMsgCycleTime" BO_ 1556 1000;
BA_ "VFrameFormat" BO_ 1556 14;
BA_ "GenMsgStartDelayTime" BO_ 1557 264;
BA_ "GenMsgILSupport" BO_ 1557 1;
BA_ "GenMsgSendType" BO_ 1557 0;
BA_ "GenMsgCycleTime" BO_ 1557 10000;
BA_ "VFrameFormat" BO_ 1557 14;
BA_ "GenMsgStartDelayTime" BO_ 1421 268;
BA_ "GenMsgILSupport" BO_ 1421 1;
BA_ "VFrameFormat" BO_ 1421 14;
BA_ "GenMsgStartDelayTime" BO_ 1002 272;
BA_ "GenMsgILSupport" BO_ 1002 1;
BA_ "GenMsgSendType" BO_ 1002 0;
BA_ "GenMsgCycleTime" BO_ 1002 1000;
BA_ "VFrameFormat" BO_ 1002 14;
BA_ "GenMsgStartDelayTime" BO_ 894 276;
BA_ "GenMsgILSupport" BO_ 894 1;
BA_ "GenMsgSendType" BO_ 894 0;
BA_ "GenMsgCycleTime" BO_ 894 1000;
BA_ "VFrameFormat" BO_ 894 14;
BA_ "GenMsgStartDelayTime" BO_ 1004 280;
BA_ "GenMsgILSupport" BO_ 1004 1;
BA_ "GenMsgSendType" BO_ 1004 0;
BA_ "GenMsgCycleTime" BO_ 1004 1000;
BA_ "VFrameFormat" BO_ 1004 14;
BA_ "GenMsgStartDelayTime" BO_ 1006 284;
BA_ "GenMsgILSupport" BO_ 1006 1;
BA_ "GenMsgSendType" BO_ 1006 0;
BA_ "GenMsgCycleTime" BO_ 1006 1000;
BA_ "VFrameFormat" BO_ 1006 14;
BA_ "GenMsgStartDelayTime" BO_ 789 288;
BA_ "GenMsgILSupport" BO_ 789 1;
BA_ "VFrameFormat" BO_ 789 14;
BA_ "GenMsgStartDelayTime" BO_ 1316 292;
BA_ "GenMsgILSupport" BO_ 1316 1;
BA_ "GenMsgSendType" BO_ 1316 0;
BA_ "GenMsgCycleTime" BO_ 1316 1000;
BA_ "VFrameFormat" BO_ 1316 14;
BA_ "GenMsgStartDelayTime" BO_ 1319 296;
BA_ "GenMsgILSupport" BO_ 1319 1;
BA_ "GenMsgSendType" BO_ 1319 0;
BA_ "GenMsgCycleTime" BO_ 1319 1000;
BA_ "VFrameFormat" BO_ 1319 14;
BA_ "GenMsgStartDelayTime" BO_ 476 300;
BA_ "GenMsgILSupport" BO_ 476 1;
BA_ "GenMsgSendType" BO_ 476 0;
BA_ "GenMsgCycleTime" BO_ 476 300;
BA_ "VFrameFormat" BO_ 476 14;
BA_ "GenMsgStartDelayTime" BO_ 781 304;
BA_ "GenMsgILSupport" BO_ 781 1;
BA_ "GenMsgSendType" BO_ 781 0;
BA_ "GenMsgCycleTime" BO_ 781 1000;
BA_ "VFrameFormat" BO_ 781 14;
BA_ "GenMsgStartDelayTime" BO_ 503 308;
BA_ "GenMsgILSupport" BO_ 503 1;
BA_ "GenMsgSendType" BO_ 503 0;
BA_ "GenMsgCycleTime" BO_ 503 500;
BA_ "VFrameFormat" BO_ 503 14;
BA_ "GenMsgStartDelayTime" BO_ 1050 312;
BA_ "GenMsgILSupport" BO_ 1050 1;
BA_ "GenMsgSendType" BO_ 1050 0;
BA_ "GenMsgCycleTime" BO_ 1050 1000;
BA_ "VFrameFormat" BO_ 1050 14;
BA_ "GenMsgILSupport" BO_ 957 1;
BA_ "GenMsgSendType" BO_ 957 0;
BA_ "GenMsgCycleTime" BO_ 957 1000;
BA_ "VFrameFormat" BO_ 957 14;
BA_ "GenMsgILSupport" BO_ 460 1;
BA_ "GenMsgSendType" BO_ 460 0;
BA_ "GenMsgCycleTime" BO_ 460 300;
BA_ "VFrameFormat" BO_ 460 14;
BA_ "GenMsgILSupport" BO_ 1287 1;
BA_ "GenMsgSendType" BO_ 1287 0;
BA_ "GenMsgCycleTime" BO_ 1287 1000;
BA_ "VFrameFormat" BO_ 1287 14;
BA_ "GenMsgILSupport" BO_ 661 1;
BA_ "GenMsgSendType" BO_ 661 0;
BA_ "GenMsgCycleTime" BO_ 661 1000;
BA_ "VFrameFormat" BO_ 661 14;
BA_ "GenMsgILSupport" BO_ 662 1;
BA_ "GenMsgSendType" BO_ 662 0;
BA_ "GenMsgCycleTime" BO_ 662 1000;
BA_ "VFrameFormat" BO_ 662 14;
BA_ "GenMsgILSupport" BO_ 1058 1;
BA_ "GenMsgSendType" BO_ 1058 0;
BA_ "GenMsgCycleTime" BO_ 1058 1000;
BA_ "VFrameFormat" BO_ 1058 14;
BA_ "GenMsgILSupport" BO_ 1073 1;
BA_ "GenMsgSendType" BO_ 1073 0;
BA_ "GenMsgCycleTime" BO_ 1073 1000;
BA_ "VFrameFormat" BO_ 1073 14;
BA_ "GenMsgILSupport" BO_ 1074 1;
BA_ "GenMsgSendType" BO_ 1074 0;
BA_ "GenMsgCycleTime" BO_ 1074 1000;
BA_ "VFrameFormat" BO_ 1074 14;
BA_ "GenMsgILSupport" BO_ 678 1;
BA_ "GenMsgSendType" BO_ 678 0;
BA_ "GenMsgCycleTime" BO_ 678 1000;
BA_ "VFrameFormat" BO_ 678 14;
BA_ "GenMsgILSupport" BO_ 516 1;
BA_ "GenMsgSendType" BO_ 516 0;
BA_ "GenMsgCycleTime" BO_ 516 1000;
BA_ "VFrameFormat" BO_ 516 14;
BA_ "GenMsgILSupport" BO_ 465 1;
BA_ "GenMsgSendType" BO_ 465 0;
BA_ "GenMsgCycleTime" BO_ 465 300;
BA_ "VFrameFormat" BO_ 465 14;
BA_ "GenMsgILSupport" BO_ 1027 1;
BA_ "GenMsgSendType" BO_ 1027 0;
BA_ "GenMsgCycleTime" BO_ 1027 1000;
BA_ "VFrameFormat" BO_ 1027 14;
BA_ "GenMsgILSupport" BO_ 1029 1;
BA_ "GenMsgSendType" BO_ 1029 0;
BA_ "GenMsgCycleTime" BO_ 1029 1000;
BA_ "VFrameFormat" BO_ 1029 14;
BA_ "GenMsgILSupport" BO_ 333 1;
BA_ "GenMsgSendType" BO_ 333 0;
BA_ "GenMsgCycleTime" BO_ 333 100;
BA_ "VFrameFormat" BO_ 333 14;
BA_ "GenMsgILSupport" BO_ 335 1;
BA_ "GenMsgSendType" BO_ 335 0;
BA_ "GenMsgCycleTime" BO_ 335 100;
BA_ "VFrameFormat" BO_ 335 14;
BA_ "GenMsgILSupport" BO_ 386 1;
BA_ "GenMsgSendType" BO_ 386 0;
BA_ "GenMsgCycleTime" BO_ 386 100;
BA_ "VFrameFormat" BO_ 386 14;
BA_ "GenMsgILSupport" BO_ 393 1;
BA_ "GenMsgSendType" BO_ 393 0;
BA_ "GenMsgCycleTime" BO_ 393 100;
BA_ "VFrameFormat" BO_ 393 14;
BA_ "GenMsgILSupport" BO_ 396 1;
BA_ "GenMsgSendType" BO_ 396 0;
BA_ "GenMsgCycleTime" BO_ 396 100;
BA_ "VFrameFormat" BO_ 396 14;
BA_ "GenMsgILSupport" BO_ 970 1;
BA_ "GenMsgSendType" BO_ 970 0;
BA_ "GenMsgCycleTime" BO_ 970 1000;
BA_ "VFrameFormat" BO_ 970 14;
BA_ "GenMsgILSupport" BO_ 815 1;
BA_ "GenMsgSendType" BO_ 815 0;
BA_ "GenMsgCycleTime" BO_ 815 1000;
BA_ "VFrameFormat" BO_ 815 14;
BA_ "GenMsgILSupport" BO_ 822 1;
BA_ "GenMsgSendType" BO_ 822 0;
BA_ "GenMsgCycleTime" BO_ 822 1000;
BA_ "VFrameFormat" BO_ 822 14;
BA_ "GenMsgILSupport" BO_ 845 1;
BA_ "GenMsgSendType" BO_ 845 0;
BA_ "GenMsgCycleTime" BO_ 845 1000;
BA_ "VFrameFormat" BO_ 845 14;
BA_ "GenMsgILSupport" BO_ 901 1;
BA_ "GenMsgSendType" BO_ 901 0;
BA_ "GenMsgCycleTime" BO_ 901 1000;
BA_ "VFrameFormat" BO_ 901 14;
BA_ "GenMsgILSupport" BO_ 968 1;
BA_ "GenMsgSendType" BO_ 968 0;
BA_ "GenMsgCycleTime" BO_ 968 1000;
BA_ "VFrameFormat" BO_ 968 14;
BA_ "GenMsgILSupport" BO_ 808 1;
BA_ "GenMsgSendType" BO_ 808 0;
BA_ "GenMsgCycleTime" BO_ 808 1000;
BA_ "VFrameFormat" BO_ 808 14;
BA_ "GenMsgILSupport" BO_ 1081 1;
BA_ "GenMsgSendType" BO_ 1081 0;
BA_ "GenMsgCycleTime" BO_ 1081 1000;
BA_ "VFrameFormat" BO_ 1081 14;
BA_ "GenMsgILSupport" BO_ 885 1;
BA_ "GenMsgSendType" BO_ 885 0;
BA_ "GenMsgCycleTime" BO_ 885 1000;
BA_ "VFrameFormat" BO_ 885 14;
BA_ "GenMsgILSupport" BO_ 765 1;
BA_ "GenMsgSendType" BO_ 765 0;
BA_ "GenMsgCycleTime" BO_ 765 2000;
BA_ "VFrameFormat" BO_ 765 14;
BA_ "GenMsgILSupport" BO_ 1036 1;
BA_ "GenMsgSendType" BO_ 1036 0;
BA_ "GenMsgCycleTime" BO_ 1036 1000;
BA_ "VFrameFormat" BO_ 1036 14;
BA_ "GenMsgILSupport" BO_ 1037 1;
BA_ "GenMsgSendType" BO_ 1037 0;
BA_ "GenMsgCycleTime" BO_ 1037 1000;
BA_ "VFrameFormat" BO_ 1037 14;
BA_ "GenMsgILSupport" BO_ 491 1;
BA_ "GenMsgSendType" BO_ 491 0;
BA_ "GenMsgCycleTime" BO_ 491 500;
BA_ "VFrameFormat" BO_ 491 14;
BA_ "GenMsgILSupport" BO_ 490 1;
BA_ "GenMsgSendType" BO_ 490 0;
BA_ "GenMsgCycleTime" BO_ 490 500;
BA_ "VFrameFormat" BO_ 490 14;
BA_ "GenMsgILSupport" BO_ 443 1;
BA_ "GenMsgSendType" BO_ 443 0;
BA_ "GenMsgCycleTime" BO_ 443 200;
BA_ "VFrameFormat" BO_ 443 14;
BA_ "GenMsgILSupport" BO_ 1173 1;
BA_ "GenMsgSendType" BO_ 1173 0;
BA_ "GenMsgCycleTime" BO_ 1173 1000;
BA_ "VFrameFormat" BO_ 1173 14;
BA_ "GenMsgILSupport" BO_ 1174 1;
BA_ "GenMsgSendType" BO_ 1174 0;
BA_ "GenMsgCycleTime" BO_ 1174 1000;
BA_ "VFrameFormat" BO_ 1174 14;
BA_ "GenMsgILSupport" BO_ 839 1;
BA_ "GenMsgSendType" BO_ 839 0;
BA_ "GenMsgCycleTime" BO_ 839 1000;
BA_ "VFrameFormat" BO_ 839 14;
BA_ "GenMsgILSupport" BO_ 844 1;
BA_ "GenMsgSendType" BO_ 844 0;
BA_ "GenMsgCycleTime" BO_ 844 1000;
BA_ "VFrameFormat" BO_ 844 14;
BA_ "GenMsgILSupport" BO_ 1047 1;
BA_ "GenMsgSendType" BO_ 1047 0;
BA_ "GenMsgCycleTime" BO_ 1047 1000;
BA_ "VFrameFormat" BO_ 1047 14;
BA_ "GenMsgILSupport" BO_ 879 1;
BA_ "GenMsgSendType" BO_ 879 0;
BA_ "GenMsgCycleTime" BO_ 879 1000;
BA_ "VFrameFormat" BO_ 879 14;
BA_ "GenMsgILSupport" BO_ 1048 1;
BA_ "GenMsgSendType" BO_ 1048 0;
BA_ "GenMsgCycleTime" BO_ 1048 1000;
BA_ "VFrameFormat" BO_ 1048 14;
BA_ "GenMsgILSupport" BO_ 1062 1;
BA_ "GenMsgSendType" BO_ 1062 0;
BA_ "GenMsgCycleTime" BO_ 1062 1000;
BA_ "VFrameFormat" BO_ 1062 14;
BA_ "GenMsgILSupport" BO_ 1064 1;
BA_ "GenMsgSendType" BO_ 1064 0;
BA_ "GenMsgCycleTime" BO_ 1064 1000;
BA_ "VFrameFormat" BO_ 1064 14;
BA_ "GenMsgILSupport" BO_ 1066 1;
BA_ "GenMsgSendType" BO_ 1066 0;
BA_ "GenMsgCycleTime" BO_ 1066 1000;
BA_ "VFrameFormat" BO_ 1066 14;
BA_ "GenMsgILSupport" BO_ 1068 1;
BA_ "GenMsgSendType" BO_ 1068 0;
BA_ "GenMsgCycleTime" BO_ 1068 1000;
BA_ "VFrameFormat" BO_ 1068 14;
BA_ "GenMsgILSupport" BO_ 999 1;
BA_ "GenMsgSendType" BO_ 999 0;
BA_ "GenMsgCycleTime" BO_ 999 1000;
BA_ "VFrameFormat" BO_ 999 14;
BA_ "GenMsgILSupport" BO_ 792 1;
BA_ "GenMsgSendType" BO_ 792 0;
BA_ "GenMsgCycleTime" BO_ 792 1000;
BA_ "VFrameFormat" BO_ 792 14;
BA_ "GenMsgILSupport" BO_ 106 1;
BA_ "GenMsgSendType" BO_ 106 0;
BA_ "GenMsgCycleTime" BO_ 106 10;
BA_ "VFrameFormat" BO_ 106 14;
BA_ "GenMsgILSupport" BO_ 105 1;
BA_ "GenMsgSendType" BO_ 105 0;
BA_ "GenMsgCycleTime" BO_ 105 10;
BA_ "VFrameFormat" BO_ 105 14;
BA_ "GenMsgILSupport" BO_ 158 1;
BA_ "GenMsgSendType" BO_ 158 0;
BA_ "GenMsgCycleTime" BO_ 158 20;
BA_ "VFrameFormat" BO_ 158 14;
BA_ "GenMsgILSupport" BO_ 183 1;
BA_ "GenMsgSendType" BO_ 183 0;
BA_ "GenMsgCycleTime" BO_ 183 30;
BA_ "VFrameFormat" BO_ 183 14;
BA_ "GenMsgILSupport" BO_ 1537 1;
BA_ "GenMsgSendType" BO_ 1537 0;
BA_ "GenMsgCycleTime" BO_ 1537 1000;
BA_ "VFrameFormat" BO_ 1537 14;
BA_ "GenMsgILSupport" BO_ 761 1;
BA_ "GenMsgSendType" BO_ 761 0;
BA_ "GenMsgCycleTime" BO_ 761 1000;
BA_ "VFrameFormat" BO_ 761 14;
BA_ "GenMsgILSupport" BO_ 638 1;
BA_ "GenMsgSendType" BO_ 638 0;
BA_ "GenMsgCycleTime" BO_ 638 1000;
BA_ "VFrameFormat" BO_ 638 14;
BA_ "GenMsgILSupport" BO_ 895 1;
BA_ "GenMsgSendType" BO_ 895 0;
BA_ "GenMsgCycleTime" BO_ 895 1000;
BA_ "VFrameFormat" BO_ 895 14;
BA_ "GenMsgILSupport" BO_ 906 1;
BA_ "GenMsgSendType" BO_ 906 0;
BA_ "GenMsgCycleTime" BO_ 906 1000;
BA_ "VFrameFormat" BO_ 906 14;
BA_ "GenMsgILSupport" BO_ 134 1;
BA_ "GenMsgSendType" BO_ 134 0;
BA_ "GenMsgCycleTime" BO_ 134 20;
BA_ "VFrameFormat" BO_ 134 14;
BA_ "GenMsgILSupport" BO_ 478 1;
BA_ "GenMsgSendType" BO_ 478 0;
BA_ "GenMsgCycleTime" BO_ 478 300;
BA_ "VFrameFormat" BO_ 478 14;
BA_ "GenMsgILSupport" BO_ 479 1;
BA_ "GenMsgSendType" BO_ 479 0;
BA_ "GenMsgCycleTime" BO_ 479 300;
BA_ "VFrameFormat" BO_ 479 14;
BA_ "GenMsgILSupport" BO_ 872 1;
BA_ "GenMsgSendType" BO_ 872 0;
BA_ "GenMsgCycleTime" BO_ 872 1000;
BA_ "VFrameFormat" BO_ 872 14;
BA_ "GenMsgILSupport" BO_ 920 1;
BA_ "GenMsgSendType" BO_ 920 0;
BA_ "GenMsgCycleTime" BO_ 920 1000;
BA_ "VFrameFormat" BO_ 920 14;
BA_ "GenMsgILSupport" BO_ 874 1;
BA_ "GenMsgSendType" BO_ 874 0;
BA_ "GenMsgCycleTime" BO_ 874 1000;
BA_ "VFrameFormat" BO_ 874 14;
BA_ "GenMsgILSupport" BO_ 924 1;
BA_ "GenMsgSendType" BO_ 924 0;
BA_ "GenMsgCycleTime" BO_ 924 1000;
BA_ "VFrameFormat" BO_ 924 14;
BA_ "GenMsgILSupport" BO_ 1280 1;
BA_ "GenMsgSendType" BO_ 1280 0;
BA_ "GenMsgCycleTime" BO_ 1280 2000;
BA_ "VFrameFormat" BO_ 1280 14;
BA_ "GenMsgILSupport" BO_ 878 1;
BA_ "GenMsgSendType" BO_ 878 0;
BA_ "GenMsgCycleTime" BO_ 878 1000;
BA_ "VFrameFormat" BO_ 878 14;
BA_ "GenMsgILSupport" BO_ 831 1;
BA_ "GenMsgSendType" BO_ 831 0;
BA_ "GenMsgCycleTime" BO_ 831 1000;
BA_ "VFrameFormat" BO_ 831 14;
BA_ "GenMsgILSupport" BO_ 978 1;
BA_ "GenMsgSendType" BO_ 978 0;
BA_ "GenMsgCycleTime" BO_ 978 1000;
BA_ "VFrameFormat" BO_ 978 14;
BA_ "GenMsgILSupport" BO_ 1017 1;
BA_ "GenMsgSendType" BO_ 1017 0;
BA_ "GenMsgCycleTime" BO_ 1017 1000;
BA_ "VFrameFormat" BO_ 1017 14;
BA_ "GenMsgILSupport" BO_ 1024 1;
BA_ "GenMsgSendType" BO_ 1024 0;
BA_ "GenMsgCycleTime" BO_ 1024 1000;
BA_ "VFrameFormat" BO_ 1024 14;
BA_ "GenMsgILSupport" BO_ 1028 1;
BA_ "GenMsgSendType" BO_ 1028 0;
BA_ "GenMsgCycleTime" BO_ 1028 1000;
BA_ "VFrameFormat" BO_ 1028 14;
BA_ "GenMsgILSupport" BO_ 963 1;
BA_ "GenMsgSendType" BO_ 963 0;
BA_ "GenMsgCycleTime" BO_ 963 1000;
BA_ "VFrameFormat" BO_ 963 14;
BA_ "GenMsgILSupport" BO_ 848 1;
BA_ "GenMsgSendType" BO_ 848 0;
BA_ "GenMsgCycleTime" BO_ 848 1000;
BA_ "VFrameFormat" BO_ 848 14;
BA_ "GenMsgILSupport" BO_ 850 1;
BA_ "GenMsgSendType" BO_ 850 0;
BA_ "GenMsgCycleTime" BO_ 850 1000;
BA_ "VFrameFormat" BO_ 850 14;
BA_ "GenMsgILSupport" BO_ 851 1;
BA_ "GenMsgSendType" BO_ 851 0;
BA_ "GenMsgCycleTime" BO_ 851 1000;
BA_ "VFrameFormat" BO_ 851 14;
BA_ "GenMsgILSupport" BO_ 955 1;
BA_ "GenMsgSendType" BO_ 955 0;
BA_ "GenMsgCycleTime" BO_ 955 1000;
BA_ "VFrameFormat" BO_ 955 14;
BA_ "GenMsgILSupport" BO_ 481 1;
BA_ "GenMsgSendType" BO_ 481 0;
BA_ "GenMsgCycleTime" BO_ 481 300;
BA_ "VFrameFormat" BO_ 481 14;
BA_ "GenMsgILSupport" BO_ 912 1;
BA_ "GenMsgSendType" BO_ 912 0;
BA_ "GenMsgCycleTime" BO_ 912 1000;
BA_ "VFrameFormat" BO_ 912 14;
BA_ "GenMsgILSupport" BO_ 446 1;
BA_ "GenMsgSendType" BO_ 446 0;
BA_ "GenMsgCycleTime" BO_ 446 200;
BA_ "VFrameFormat" BO_ 446 14;
BA_ "GenMsgILSupport" BO_ 937 1;
BA_ "GenMsgSendType" BO_ 937 0;
BA_ "GenMsgCycleTime" BO_ 937 1000;
BA_ "VFrameFormat" BO_ 937 14;
BA_ "DiagConnection" BO_ 2564431072 57372;
BA_ "DiagRequest" BO_ 2564431072 1;
BA_ "VFrameFormat" BO_ 2564431072 1;
BA_ "DiagConnection" BO_ 2564481052 57372;
BA_ "DiagResponse" BO_ 2564481052 1;
BA_ "VFrameFormat" BO_ 2564481052 1;
BA_ "DiagConnection" BO_ 2564431073 57628;
BA_ "DiagRequest" BO_ 2564431073 1;
BA_ "VFrameFormat" BO_ 2564431073 1;
BA_ "DiagConnection" BO_ 2564481308 57628;
BA_ "DiagResponse" BO_ 2564481308 1;
BA_ "VFrameFormat" BO_ 2564481308 1;
BA_ "DiagConnection" BO_ 2564550624 57372;
BA_ "DiagState" BO_ 2564550624 1;
BA_ "VFrameFormat" BO_ 2564550624 1;
BA_ "DiagConnection" BO_ 2564550625 57628;
BA_ "DiagState" BO_ 2564550625 1;
BA_ "VFrameFormat" BO_ 2564550625 1;
BA_ "GenSigSendType" SG_ 1019 LK_ST 3;
BA_ "GenSigSendType" SG_ 1019 LK_FUNC 3;
BA_ "GenSigSendType" SG_ 1019 ULK_ST 3;
BA_ "GenSigSendType" SG_ 1019 ULK_FUNC 3;
BA_ "GenSigSendType" SG_ 1083 IPA_BZ2 3;
BA_ "GenSigSendType" SG_ 1083 VNUSGAPP 3;
BA_ "GenSigSendType" SG_ 1083 APP_EXT 3;
BA_ "GenSigSendType" SG_ 1083 IPAVOICE 3;
BA_ "GenSigSendType" SG_ 1083 APPME 3;
BA_ "GenSigSendType" SG_ 875 IC_EQP 3;
BA_ "GenSigSendType" SG_ 875 ICON_V2R 3;
BA_ "GenSigSendType" SG_ 875 ICON_V2V 3;
BA_ "GenSigSendType" SG_ 875 IC_BZR 3;
BA_ "GenSigSendType" SG_ 875 IC_APL 3;
BA_ "GenSigSendType" SG_ 875 IC_WNG 3;
BA_ "GenSigSendType" SG_ 875 EVN_POS1 3;
BA_ "GenSigSendType" SG_ 875 EVN_POS2 3;
BA_ "GenSigSendType" SG_ 875 EVN_ARR1 3;
BA_ "GenSigSendType" SG_ 875 EVN_ARR2 3;
BA_ "GenSigSendType" SG_ 875 EVN_DIS1 3;
BA_ "GenSigSendType" SG_ 875 EVN_DIS2 3;
BA_ "GenSigSendType" SG_ 875 STR_OVEH 3;
BA_ "GenSigSendType" SG_ 875 STR_PED 3;
BA_ "GenSigSendType" SG_ 875 SCN_TIME 3;
BA_ "GenSigSendType" SG_ 990 ITSSET 3;
BA_ "GenSigSendType" SG_ 990 ITSTMDIS 3;
BA_ "GenSigSendType" SG_ 990 ITSTMSTA 3;
BA_ "GenSigSendType" SG_ 990 ITSSTSTA 3;
BA_ "GenSigSendType" SG_ 788 IC_APL2 3;
BA_ "GenSigSendType" SG_ 788 CRC_MSG 3;
BA_ "GenSigSendType" SG_ 788 CRC_L 3;
BA_ "GenSigSendType" SG_ 788 CRC_R 3;
BA_ "GenSigSendType" SG_ 788 IC_APL3 3;
BA_ "GenSigSendType" SG_ 635 ITSVOI01 3;
BA_ "GenSigStartValue" SG_ 371 LR_RC_PS 255;
BA_ "GenSigStartValue" SG_ 377 LR_SL_PS 1023;
BA_ "GenSigStartValue" SG_ 378 LR_LF_PS 255;
BA_ "GenSigSendType" SG_ 502 REQFRFID 3;
BA_ "GenSigSendType" SG_ 502 CHG_KPF 3;
BA_ "GenSigSendType" SG_ 502 CHG_PSN 3;
BA_ "GenSigSendType" SG_ 502 REQ_DCHG 3;
BA_ "GenSigSendType" SG_ 502 REQFREXE 3;
BA_ "GenSigSendType" SG_ 502 RHEOSTAT 3;
BA_ "GenSigSendType" SG_ 502 TAIL_CN 3;
BA_ "GenSigSendType" SG_ 502 ILL_OF 3;
BA_ "GenSigSendType" SG_ 1553 ODO 3;
BA_ "GenSigStartValue" SG_ 1553 ODO 4294967295;
BA_ "GenSigSendType" SG_ 1560 AS_DT 3;
BA_ "GenSigStartValue" SG_ 1560 AS_DT 65534;
BA_ "GenSigSendType" SG_ 1560 UNIT_2 3;
BA_ "GenSigStartValue" SG_ 1560 UNIT_2 3;
BA_ "GenSigSendType" SG_ 1556 TRIP_A 3;
BA_ "GenSigSendType" SG_ 1557 HCSUPEN 3;
BA_ "GenSigSendType" SG_ 1557 HCSDWEN 3;
BA_ "GenSigSendType" SG_ 1557 HCSMNSW 3;
BA_ "GenSigSendType" SG_ 1557 HCSETDSP 3;
BA_ "GenSigSendType" SG_ 1557 HCSSTPOP 3;
BA_ "GenSigSendType" SG_ 1557 UNIT_CH2 3;
BA_ "GenSigStartValue" SG_ 1557 TOLER_A 63;
BA_ "GenSigSendType" SG_ 1557 TRIP_B 3;
BA_ "GenSigSendType" SG_ 1002 CSR_MUTE 3;
BA_ "GenSigSendType" SG_ 1002 SW_LTC01 3;
BA_ "GenSigSendType" SG_ 1002 SW_RCD01 3;
BA_ "GenSigSendType" SG_ 1002 TSR_OSL 3;
BA_ "GenSigSendType" SG_ 1002 TSR_SNM 3;
BA_ "GenSigSendType" SG_ 1002 FCMUSER 3;
BA_ "GenSigSendType" SG_ 1002 ITSSETSW 3;
BA_ "GenSigSendType" SG_ 1002 RCTAMSW 3;
BA_ "GenSigSendType" SG_ 1002 ICSMSW 3;
BA_ "GenSigSendType" SG_ 1002 BSMMSW 3;
BA_ "GenSigSendType" SG_ 1002 CSRMSW 3;
BA_ "GenSigSendType" SG_ 1002 SW_ITS04 3;
BA_ "GenSigSendType" SG_ 1002 TSR_MAIN 3;
BA_ "GenSigSendType" SG_ 1002 LDAMCUS 3;
BA_ "GenSigSendType" SG_ 1002 PCSMSW 3;
BA_ "GenSigSendType" SG_ 1002 FCMMSW 3;
BA_ "GenSigSendType" SG_ 1002 LDA_SFB 3;
BA_ "GenSigSendType" SG_ 894 ACINV_SW 3;
BA_ "GenSigSendType" SG_ 894 RSCSW_OP 3;
BA_ "GenSigSendType" SG_ 1004 SW_AS01 3;
BA_ "GenSigSendType" SG_ 1004 SW_AS02 3;
BA_ "GenSigSendType" SG_ 1004 TPUNTSET 3;
BA_ "GenSigSendType" SG_ 1004 TPINSEL 3;
BA_ "GenSigSendType" SG_ 1004 TPINSELR 3;
BA_ "GenSigSendType" SG_ 1004 TPINSELF 3;
BA_ "GenSigSendType" SG_ 1004 SW_AS05 3;
BA_ "GenSigSendType" SG_ 1004 WVRU_BB 3;
BA_ "GenSigSendType" SG_ 1004 WVRD_BB 3;
BA_ "GenSigSendType" SG_ 1004 WRSW_BB 3;
BA_ "GenSigSendType" SG_ 1004 WROF_BB 3;
BA_ "GenSigSendType" SG_ 1004 WRIN_BB 3;
BA_ "GenSigSendType" SG_ 1004 WRLO_BB 3;
BA_ "GenSigSendType" SG_ 1006 PBDKSW 3;
BA_ "GenSigSendType" SG_ 1006 TITE_BB 3;
BA_ "GenSigSendType" SG_ 1006 ASD_CANC 3;
BA_ "GenSigSendType" SG_ 1006 ASD_CONT 3;
BA_ "GenSigSendType" SG_ 1006 RSRMSW 3;
BA_ "GenSigSendType" SG_ 1006 SRPMSW 3;
BA_ "GenSigSendType" SG_ 1006 RSRCANSW 3;
BA_ "GenSigSendType" SG_ 1006 VRAPRDIS 3;
BA_ "GenSigSendType" SG_ 1006 PWLSW 3;
BA_ "GenSigSendType" SG_ 1006 MLR_BB 3;
BA_ "GenSigSendType" SG_ 1006 DPMS_BB 3;
BA_ "GenSigSendType" SG_ 1006 LSW_BB 3;
BA_ "GenSigSendType" SG_ 1006 WSVS_BB 3;
BA_ "GenSigSendType" SG_ 1006 M_BB 3;
BA_ "GenSigSendType" SG_ 1006 VRESTPSW 3;
BA_ "GenSigSendType" SG_ 1006 MRT_BB 3;
BA_ "GenSigSendType" SG_ 1006 RLM_BB 3;
BA_ "GenSigSendType" SG_ 1006 FOG_BB 3;
BA_ "GenSigSendType" SG_ 1006 MINTRSOF 3;
BA_ "GenSigSendType" SG_ 1006 RFG_BB 3;
BA_ "GenSigSendType" SG_ 1006 ART_BB 3;
BA_ "GenSigSendType" SG_ 1006 PBD_BB 3;
BA_ "GenSigSendType" SG_ 1006 POS_REG 3;
BA_ "GenSigSendType" SG_ 1006 PBDBZMVL 3;
BA_ "GenSigSendType" SG_ 1006 POS_CALL 3;
BA_ "GenSigSendType" SG_ 1006 PBDMSW 3;
BA_ "GenSigSendType" SG_ 1006 PBDMCUS 3;
BA_ "GenSigSendType" SG_ 1006 ULKMSW 3;
BA_ "GenSigSendType" SG_ 1006 LKMSW 3;
BA_ "GenSigSendType" SG_ 1006 VRAPRMSW 3;
BA_ "GenSigSendType" SG_ 789 CL_AMPM 3;
BA_ "GenSigSendType" SG_ 789 CL_HOUR 3;
BA_ "GenSigStartValue" SG_ 789 CL_HOUR 30;
BA_ "GenSigSendType" SG_ 789 TIME_SET 3;
BA_ "GenSigSendType" SG_ 789 CL_MIN 3;
BA_ "GenSigStartValue" SG_ 789 CL_MIN 62;
BA_ "GenSigSendType" SG_ 789 CL_SEC 3;
BA_ "GenSigStartValue" SG_ 789 CL_SEC 62;
BA_ "GenSigSendType" SG_ 789 OFSTSIGN 3;
BA_ "GenSigSendType" SG_ 789 M_MONTH 3;
BA_ "GenSigSendType" SG_ 789 OFST_H 3;
BA_ "GenSigStartValue" SG_ 789 OFST_H 14;
BA_ "GenSigSendType" SG_ 789 OFST_M 3;
BA_ "GenSigStartValue" SG_ 789 OFST_M 62;
BA_ "GenSigSendType" SG_ 789 M_YEAR 3;
BA_ "GenSigStartValue" SG_ 789 M_YEAR 255;
BA_ "GenSigSendType" SG_ 789 M_WEEK 3;
BA_ "GenSigSendType" SG_ 789 M_DAY 3;
BA_ "GenSigSendType" SG_ 1316 AS_TM 3;
BA_ "GenSigStartValue" SG_ 1316 AS_TM 65534;
BA_ "GenSigSendType" SG_ 1316 TR2_DUTY 3;
BA_ "GenSigSendType" SG_ 1316 IL2_DUTY 3;
BA_ "GenSigSendType" SG_ 1316 RANGE 3;
BA_ "GenSigStartValue" SG_ 1316 RANGE 65534;
BA_ "GenSigSendType" SG_ 1316 AS_SP 3;
BA_ "GenSigStartValue" SG_ 1316 AS_SP 65534;
BA_ "GenSigSendType" SG_ 1316 UNIT_1 3;
BA_ "GenSigStartValue" SG_ 1316 UNIT_1 3;
BA_ "GenSigSendType" SG_ 1316 UNIT_6 3;
BA_ "GenSigStartValue" SG_ 1316 UNIT_6 7;
BA_ "GenSigSendType" SG_ 1316 RHEO_POS 3;
BA_ "GenSigStartValue" SG_ 1316 RHEO_POS 31;
BA_ "GenSigSendType" SG_ 1319 ST_ACOFF 3;
BA_ "GenSigSendType" SG_ 1319 ST_TDEF 3;
BA_ "GenSigSendType" SG_ 1319 ST_TAUTO 3;
BA_ "GenSigSendType" SG_ 476 BKL3LMET 3;
BA_ "GenSigStartValue" SG_ 476 BKL3LMET 2;
BA_ "GenSigSendType" SG_ 476 BKL3RMET 3;
BA_ "GenSigStartValue" SG_ 476 BKL3RMET 2;
BA_ "GenSigSendType" SG_ 476 BKL3CMET 3;
BA_ "GenSigStartValue" SG_ 476 BKL3CMET 2;
BA_ "GenSigSendType" SG_ 476 DBKL_MET 3;
BA_ "GenSigStartValue" SG_ 476 DBKL_MET 2;
BA_ "GenSigSendType" SG_ 476 PBKL_MET 3;
BA_ "GenSigStartValue" SG_ 476 PBKL_MET 2;
BA_ "GenSigSendType" SG_ 476 RLBKLMET 3;
BA_ "GenSigStartValue" SG_ 476 RLBKLMET 2;
BA_ "GenSigSendType" SG_ 476 RRBKLMET 3;
BA_ "GenSigStartValue" SG_ 476 RRBKLMET 2;
BA_ "GenSigSendType" SG_ 476 RCBKLMET 3;
BA_ "GenSigStartValue" SG_ 476 RCBKLMET 2;
BA_ "GenSigSendType" SG_ 476 TRNBBSW 3;
BA_ "GenSigSendType" SG_ 781 ODO_01 3;
BA_ "GenSigStartValue" SG_ 781 ODO_01 4294967295;
BA_ "GenSigSendType" SG_ 503 IN_EC 3;
BA_ "GenSigStartValue" SG_ 503 IN_EC 65534;
BA_ "GenSigSendType" SG_ 503 M1_EC1 3;
BA_ "GenSigStartValue" SG_ 503 M1_EC1 65534;
BA_ "GenSigSendType" SG_ 503 M1_EC_R 3;
BA_ "GenSigSendType" SG_ 503 EV_RANGE 3;
BA_ "GenSigStartValue" SG_ 503 EV_RANGE 65534;
BA_ "GenSigSendType" SG_ 503 TO_EC 3;
BA_ "GenSigStartValue" SG_ 503 TO_EC 65534;
BA_ "GenSigSendType" SG_ 503 AS_EC 3;
BA_ "GenSigStartValue" SG_ 503 AS_EC 65535;
BA_ "GenSigSendType" SG_ 503 AS_TOEC 3;
BA_ "GenSigStartValue" SG_ 503 AS_TOEC 65535;
BA_ "GenSigSendType" SG_ 503 AS_EVDT 3;
BA_ "GenSigStartValue" SG_ 503 AS_EVDT 65535;
BA_ "GenSigSendType" SG_ 1050 RNGMSW 3;
BA_ "GenSigSendType" SG_ 1050 TBCSW 3;
BA_ "GenSigSendType" SG_ 1050 TBWSW 3;
BA_ "GenSigSendType" SG_ 957 MSG_NSFT 3;
BA_ "GenSigSendType" SG_ 957 MSG_CHK 3;
BA_ "GenSigSendType" SG_ 957 MSG_SFTF 3;
BA_ "GenSigSendType" SG_ 957 B_SLUP_S 3;
BA_ "GenSigSendType" SG_ 957 B_SLDN_S 3;
BA_ "GenSigSendType" SG_ 957 MSG_RI_S 3;
BA_ "GenSigSendType" SG_ 957 BZR_SFT1 3;
BA_ "GenSigSendType" SG_ 957 B_GEAR_S 3;
BA_ "GenSigSendType" SG_ 957 MSG_SFPF 3;
BA_ "GenSigSendType" SG_ 957 SFT_BLKS 3;
BA_ "GenSigSendType" SG_ 957 SFT_METS 3;
BA_ "GenSigSendType" SG_ 957 SILUASBW 3;
BA_ "GenSigSendType" SG_ 957 MSG_DAP 3;
BA_ "GenSigSendType" SG_ 957 MSG_ACCN 3;
BA_ "GenSigSendType" SG_ 460 BAOF_PDC 3;
BA_ "GenSigSendType" SG_ 1287 RLBKLPDC 3;
BA_ "GenSigStartValue" SG_ 1287 RLBKLPDC 2;
BA_ "GenSigSendType" SG_ 1287 RCBKLPDC 3;
BA_ "GenSigStartValue" SG_ 1287 RCBKLPDC 2;
BA_ "GenSigSendType" SG_ 1287 RRBKLPDC 3;
BA_ "GenSigStartValue" SG_ 1287 RRBKLPDC 2;
BA_ "GenSigSendType" SG_ 1287 PBKL_PDC 3;
BA_ "GenSigStartValue" SG_ 1287 PBKL_PDC 2;
BA_ "GenSigSendType" SG_ 1287 BAT_ADV 3;
BA_ "GenSigSendType" SG_ 1287 BATSAVE 3;
BA_ "GenSigStartValue" SG_ 1287 WASHLVSW 2;
BA_ "GenSigSendType" SG_ 661 OTACHGWT 3;
BA_ "GenSigSendType" SG_ 661 P_SPLNSO 3;
BA_ "GenSigSendType" SG_ 661 P_DVOAVA 3;
BA_ "GenSigSendType" SG_ 661 P_DVOSL1 3;
BA_ "GenSigSendType" SG_ 661 P_WLCEQP 3;
BA_ "GenSigSendType" SG_ 661 P_SETID 3;
BA_ "GenSigSendType" SG_ 661 P_SETON 3;
BA_ "GenSigSendType" SG_ 661 P_SETWKD 3;
BA_ "GenSigSendType" SG_ 661 P_SETTYP 3;
BA_ "GenSigSendType" SG_ 661 P_SETSTM 3;
BA_ "GenSigStartValue" SG_ 661 P_SETSTM 511;
BA_ "GenSigSendType" SG_ 661 P_SETNXT 3;
BA_ "GenSigStartValue" SG_ 661 P_SETNXT 63;
BA_ "GenSigSendType" SG_ 661 P_SETFTM 3;
BA_ "GenSigStartValue" SG_ 661 P_SETFTM 511;
BA_ "GenSigSendType" SG_ 661 P_TMPID 3;
BA_ "GenSigStartValue" SG_ 661 P_TMPID 63;
BA_ "GenSigSendType" SG_ 661 P_TMPSWK 3;
BA_ "GenSigSendType" SG_ 661 P_TMPSTM 3;
BA_ "GenSigStartValue" SG_ 661 P_TMPSTM 511;
BA_ "GenSigSendType" SG_ 661 P_ADDDSP 3;
BA_ "GenSigSendType" SG_ 661 PCNOWDSP 3;
BA_ "GenSigSendType" SG_ 661 P_EDTDSP 3;
BA_ "GenSigSendType" SG_ 661 P_TMPTYP 3;
BA_ "GenSigSendType" SG_ 661 P_TMPNWK 3;
BA_ "GenSigSendType" SG_ 661 P_TMPFTM 3;
BA_ "GenSigStartValue" SG_ 661 P_TMPFTM 511;
BA_ "GenSigSendType" SG_ 661 P_DPWAVA 3;
BA_ "GenSigSendType" SG_ 661 P_DPWSL 3;
BA_ "GenSigSendType" SG_ 662 PLGSTS 3;
BA_ "GenSigSendType" SG_ 662 PIINFD08 3;
BA_ "GenSigSendType" SG_ 662 PIINFDSP 3;
BA_ "GenSigSendType" SG_ 662 PSDSPRQ2 3;
BA_ "GenSigSendType" SG_ 662 PSDSPRQ 3;
BA_ "GenSigSendType" SG_ 662 P_CLCSL4 3;
BA_ "GenSigSendType" SG_ 662 P_CLCSL3 3;
BA_ "GenSigSendType" SG_ 662 P_CLCSL2 3;
BA_ "GenSigSendType" SG_ 662 P_CLCSL1 3;
BA_ "GenSigSendType" SG_ 662 P_LMDAVA 3;
BA_ "GenSigSendType" SG_ 662 PLID_DSP 3;
BA_ "GenSigSendType" SG_ 662 P_LMDNW 3;
BA_ "GenSigSendType" SG_ 662 DCRCKDSP 3;
BA_ "GenSigSendType" SG_ 662 P_SETSTS 3;
BA_ "GenSigSendType" SG_ 662 P_DPW 3;
BA_ "GenSigSendType" SG_ 662 P_NCTYP 3;
BA_ "GenSigStartValue" SG_ 662 P_NCTYP 15;
BA_ "GenSigSendType" SG_ 662 P_NCWKD 3;
BA_ "GenSigSendType" SG_ 662 P_NCSTM 3;
BA_ "GenSigStartValue" SG_ 662 P_NCSTM 511;
BA_ "GenSigSendType" SG_ 662 P_SLMSL1 3;
BA_ "GenSigSendType" SG_ 662 P_NCDSP 3;
BA_ "GenSigSendType" SG_ 662 P_NCFTM 3;
BA_ "GenSigStartValue" SG_ 662 P_NCFTM 511;
BA_ "GenSigSendType" SG_ 662 P_SLMSL3 3;
BA_ "GenSigSendType" SG_ 662 P_SLMSL2 3;
BA_ "GenSigSendType" SG_ 662 P_NCLMT 3;
BA_ "GenSigStartValue" SG_ 662 P_NCLMT 7;
BA_ "GenSigSendType" SG_ 662 P_NCCUR 3;
BA_ "GenSigStartValue" SG_ 662 P_NCCUR 7;
BA_ "GenSigSendType" SG_ 662 P_SLMSL5 3;
BA_ "GenSigSendType" SG_ 662 P_SLMSL4 3;
BA_ "GenSigSendType" SG_ 662 P_SLMNOW 3;
BA_ "GenSigStartValue" SG_ 662 PCHGTM07 65535;
BA_ "GenSigSendType" SG_ 662 P_TMRAVA 3;
BA_ "GenSigSendType" SG_ 662 P_CURAVA 3;
BA_ "GenSigSendType" SG_ 662 P_LMTAVA 3;
BA_ "GenSigSendType" SG_ 662 P_CLCAVA 3;
BA_ "GenSigSendType" SG_ 662 P_LMTDSP 3;
BA_ "GenSigSendType" SG_ 662 P_SPLAVA 3;
BA_ "GenSigSendType" SG_ 662 P_SLMAVA 3;
BA_ "GenSigSendType" SG_ 662 P_TMRSTR 3;
BA_ "GenSigSendType" SG_ 662 P_TMRSST 3;
BA_ "GenSigSendType" SG_ 662 P_SPLEVA 3;
BA_ "GenSigSendType" SG_ 662 P_SPLHVA 3;
BA_ "GenSigSendType" SG_ 662 P_LMTSEL 3;
BA_ "GenSigSendType" SG_ 662 P_LMTNOW 3;
BA_ "GenSigSendType" SG_ 662 P_SPLDSP 3;
BA_ "GenSigSendType" SG_ 662 P_SPLEVW 3;
BA_ "GenSigSendType" SG_ 662 P_SPLACA 3;
BA_ "GenSigSendType" SG_ 662 P_SPLDCA 3;
BA_ "GenSigStartValue" SG_ 1058 PWSPLT_G 1023;
BA_ "GenSigSendType" SG_ 1058 P_CUR200 3;
BA_ "GenSigSendType" SG_ 1058 PCNCTIND 3;
BA_ "GenSigSendType" SG_ 1058 P_CURSL2 3;
BA_ "GenSigSendType" SG_ 1058 P_CURSL1 3;
BA_ "GenSigSendType" SG_ 1058 CBLOCKSU 3;
BA_ "GenSigStartValue" SG_ 1058 PWSPLT_B 16383;
BA_ "GenSigSendType" SG_ 1058 P_SPLPOP 3;
BA_ "GenSigSendType" SG_ 1058 CNCTLOCK 3;
BA_ "GenSigSendType" SG_ 1058 P_CURSL4 3;
BA_ "GenSigSendType" SG_ 1058 P_CURSL3 3;
BA_ "GenSigSendType" SG_ 1073 MRMMSG 3;
BA_ "GenSigStartValue" SG_ 1074 PIEVE06 127;
BA_ "GenSigStartValue" SG_ 1074 PCHGTM06 65535;
BA_ "GenSigStartValue" SG_ 1074 PIEVD06 16383;
BA_ "GenSigStartValue" SG_ 1074 SOC_DSP 127;
BA_ "GenSigSendType" SG_ 1074 ACSTS06 3;
BA_ "GenSigSendType" SG_ 678 R_NBPSET 3;
BA_ "GenSigSendType" SG_ 678 R_NACSET 3;
BA_ "GenSigSendType" SG_ 678 R_ADDDSP 3;
BA_ "GenSigSendType" SG_ 678 R_BPEXST 3;
BA_ "GenSigSendType" SG_ 678 R_BPON 3;
BA_ "GenSigSendType" SG_ 678 R_BPSET 3;
BA_ "GenSigSendType" SG_ 678 R_ACSET 3;
BA_ "GenSigSendType" SG_ 678 R_NDEPTM 3;
BA_ "GenSigStartValue" SG_ 678 R_NDEPTM 511;
BA_ "GenSigSendType" SG_ 678 P_VPAVST 3;
BA_ "GenSigSendType" SG_ 678 R_NBPWKD 3;
BA_ "GenSigSendType" SG_ 678 R_BPID 3;
BA_ "GenSigSendType" SG_ 678 R_DEPTM 3;
BA_ "GenSigStartValue" SG_ 678 R_DEPTM 511;
BA_ "GenSigSendType" SG_ 678 R_BPWKD 3;
BA_ "GenSigSendType" SG_ 678 P_VPVGST 3;
BA_ "GenSigSendType" SG_ 678 P_OCTAVA 3;
BA_ "GenSigSendType" SG_ 678 P_OCTID 3;
BA_ "GenSigSendType" SG_ 678 P_LMTNO2 3;
BA_ "GenSigSendType" SG_ 678 P_OCTON 3;
BA_ "GenSigSendType" SG_ 678 P_OCTTYP 3;
BA_ "GenSigSendType" SG_ 678 P_OCTON2 3;
BA_ "GenSigSendType" SG_ 678 P_OCTSTM 3;
BA_ "GenSigSendType" SG_ 678 P_OCTWKD 3;
BA_ "GenSigSendType" SG_ 678 P_OCTFTM 3;
BA_ "GenSigSendType" SG_ 678 P_OCTWK2 3;
BA_ "GenSigSendType" SG_ 678 P_OCTST2 3;
BA_ "GenSigSendType" SG_ 678 P_USOC2A 3;
BA_ "GenSigSendType" SG_ 678 P_OCTFT2 3;
BA_ "GenSigSendType" SG_ 678 P_USOC1A 3;
BA_ "GenSigSendType" SG_ 678 P_LMDSTM 3;
BA_ "GenSigStartValue" SG_ 678 P_LMDSTM 511;
BA_ "GenSigSendType" SG_ 678 P_USOC0A 3;
BA_ "GenSigSendType" SG_ 678 P_LMDFTM 3;
BA_ "GenSigStartValue" SG_ 678 P_LMDFTM 511;
BA_ "GenSigSendType" SG_ 678 P_LMDLMT 3;
BA_ "GenSigStartValue" SG_ 678 P_LMDLMT 127;
BA_ "GenSigSendType" SG_ 678 P_LMDST2 3;
BA_ "GenSigStartValue" SG_ 678 P_LMDST2 511;
BA_ "GenSigSendType" SG_ 678 P_LMDWKD 3;
BA_ "GenSigSendType" SG_ 678 P_LMDFT2 3;
BA_ "GenSigStartValue" SG_ 678 P_LMDFT2 511;
BA_ "GenSigSendType" SG_ 678 P_LMDLM2 3;
BA_ "GenSigStartValue" SG_ 678 P_LMDLM2 127;
BA_ "GenSigSendType" SG_ 678 P_OCADFL 3;
BA_ "GenSigSendType" SG_ 678 P_LMDWK2 3;
BA_ "GenSigSendType" SG_ 678 P_OCFLFL 3;
BA_ "GenSigSendType" SG_ 678 P_OCTTY2 3;
BA_ "GenSigSendType" SG_ 678 P_OCRQFL 3;
BA_ "GenSigSendType" SG_ 678 P_OCNFFL 3;
BA_ "GenSigSendType" SG_ 678 P_VPSOCT 3;
BA_ "GenSigSendType" SG_ 678 P_VPSOCL 3;
BA_ "GenSigSendType" SG_ 516 P_PNC 3;
BA_ "GenSigSendType" SG_ 516 P_ACINST 3;
BA_ "GenSigSendType" SG_ 516 P_PNCAVA 3;
BA_ "GenSigSendType" SG_ 516 P_CEIBRQ 3;
BA_ "GenSigSendType" SG_ 516 P_CEEXPD 3;
BA_ "GenSigSendType" SG_ 516 CRTDSPRQ 3;
BA_ "GenSigSendType" SG_ 516 SPWDSPRQ 3;
BA_ "GenSigSendType" SG_ 516 PSPLTAVA 3;
BA_ "GenSigSendType" SG_ 516 P_CEEXPY 3;
BA_ "GenSigStartValue" SG_ 516 P_CEEXPY 255;
BA_ "GenSigSendType" SG_ 516 P_CEEXPM 3;
BA_ "GenSigSendType" SG_ 465 PSSW_PMN 3;
BA_ "GenSigSendType" SG_ 465 IGJG_EIG 3;
BA_ "GenSigSendType" SG_ 465 MOD_EIG 3;
BA_ "GenSigSendType" SG_ 465 BZRQ_EIG 3;
BA_ "GenSigSendType" SG_ 465 APOFPNRQ 3;
BA_ "GenSigSendType" SG_ 465 SMTRDYFG 3;
BA_ "GenSigSendType" SG_ 1027 P_EXTRA 3;
BA_ "GenSigSendType" SG_ 1027 P_WALKIN 3;
BA_ "GenSigSendType" SG_ 1027 P_SLDPOS 3;
BA_ "GenSigStartValue" SG_ 1027 P_SLDPOS 1023;
BA_ "GenSigSendType" SG_ 1027 P_RCLPOS 3;
BA_ "GenSigStartValue" SG_ 1027 P_RCLPOS 255;
BA_ "GenSigSendType" SG_ 1027 PST_OPAT 3;
BA_ "GenSigSendType" SG_ 1027 RSE_LMT 3;
BA_ "GenSigSendType" SG_ 1029 P_OPST 3;
BA_ "GenSigSendType" SG_ 1029 P_STM1 3;
BA_ "GenSigSendType" SG_ 1029 P_STM2 3;
BA_ "GenSigSendType" SG_ 1029 P_RF_ST 3;
BA_ "GenSigSendType" SG_ 1029 P_RF_LV 3;
BA_ "GenSigSendType" SG_ 1029 P_LIFPOS 3;
BA_ "GenSigStartValue" SG_ 1029 P_LIFPOS 255;
BA_ "GenSigStartValue" SG_ 386 RR_RC_PS 255;
BA_ "GenSigStartValue" SG_ 393 RR_SL_PS 1023;
BA_ "GenSigStartValue" SG_ 396 RR_LF_PS 255;
BA_ "GenSigStartValue" SG_ 901 OTADTYPE 3;
BA_ "GenSigStartValue" SG_ 901 OTADSTAT 13;
BA_ "GenSigSendType" SG_ 968 RSCYCL11 3;
BA_ "GenSigSendType" SG_ 968 RSCYCL12 3;
BA_ "GenSigSendType" SG_ 968 RSCYCL13 3;
BA_ "GenSigSendType" SG_ 968 RSCYCL14 3;
BA_ "GenSigSendType" SG_ 968 RSCYCL15 3;
BA_ "GenSigSendType" SG_ 968 RSCYCL16 3;
BA_ "GenSigSendType" SG_ 808 S_RTST_L 3;
BA_ "GenSigSendType" SG_ 808 S_RTST_R 3;
BA_ "GenSigSendType" SG_ 808 RR_OPST 3;
BA_ "GenSigSendType" SG_ 808 RL_OPST 3;
BA_ "GenSigSendType" SG_ 808 RR_STM1 3;
BA_ "GenSigSendType" SG_ 808 RL_STM1 3;
BA_ "GenSigSendType" SG_ 808 SEAR_ST1 3;
BA_ "GenSigSendType" SG_ 808 SEAR_ST2 3;
BA_ "GenSigSendType" SG_ 808 WIR_ST 3;
BA_ "GenSigSendType" SG_ 808 WIR_OPST 3;
BA_ "GenSigSendType" SG_ 808 WIL_ST 3;
BA_ "GenSigSendType" SG_ 808 WIL_OPST 3;
BA_ "GenSigSendType" SG_ 808 FOR_ST 3;
BA_ "GenSigSendType" SG_ 808 FOR_OPST 3;
BA_ "GenSigSendType" SG_ 808 FOL_ST 3;
BA_ "GenSigSendType" SG_ 808 FOL_OPST 3;
BA_ "GenSigStartValue" SG_ 1081 DRVCLS 1;
BA_ "GenSigSendType" SG_ 885 PARK_S 3;
BA_ "GenSigSendType" SG_ 765 ASCMINF 3;
BA_ "GenSigSendType" SG_ 765 ASCVFST 3;
BA_ "GenSigSendType" SG_ 765 ASCVHIST 3;
BA_ "GenSigSendType" SG_ 765 ASCVHCST 3;
BA_ "GenSigSendType" SG_ 765 ASCUPST 3;
BA_ "GenSigSendType" SG_ 765 ASCDNST 3;
BA_ "GenSigSendType" SG_ 765 ASCOFFST 3;
BA_ "GenSigSendType" SG_ 765 ASCMST 3;
BA_ "GenSigSendType" SG_ 765 B_LSUS10 3;
BA_ "GenSigSendType" SG_ 765 B_LSUS18 3;
BA_ "GenSigSendType" SG_ 765 LFTIND 3;
BA_ "GenSigSendType" SG_ 765 ASCCUS 3;
BA_ "GenSigSendType" SG_ 765 ASCSTOP1 3;
BA_ "GenSigSendType" SG_ 765 ASCSTOP2 3;
BA_ "GenSigSendType" SG_ 765 REGSELRQ 3;
BA_ "GenSigSendType" SG_ 765 GPSCHGRQ 3;
BA_ "GenSigSendType" SG_ 765 ALLDELRQ 3;
BA_ "GenSigSendType" SG_ 765 VHUPSWST 3;
BA_ "GenSigSendType" SG_ 765 VHDWSWST 3;
BA_ "GenSigSendType" SG_ 765 MASWST 3;
BA_ "GenSigSendType" SG_ 765 METFSIRQ 3;
BA_ "GenSigSendType" SG_ 765 VHDFSINF 3;
BA_ "GenSigSendType" SG_ 765 VHSMINF 3;
BA_ "GenSigSendType" SG_ 765 VHSVINF 3;
BA_ "GenSigSendType" SG_ 765 VEVWDTYP 3;
BA_ "GenSigSendType" SG_ 765 HCOPSD 3;
BA_ "GenSigSendType" SG_ 765 CPUPMDRQ 3;
BA_ "GenSigStartValue" SG_ 1036 SOL 1;
BA_ "GenSigSendType" SG_ 1173 TPCRTID 3;
BA_ "GenSigStartValue" SG_ 1173 TPM_DISC 7;
BA_ "GenSigSendType" SG_ 1173 TPM_VAR 3;
BA_ "GenSigStartValue" SG_ 1173 TPM_VAR 3;
BA_ "GenSigSendType" SG_ 1173 TPM_IND 3;
BA_ "GenSigSendType" SG_ 1173 TPM_DISP 3;
BA_ "GenSigStartValue" SG_ 1173 TPM_DISP 12;
BA_ "GenSigSendType" SG_ 1173 TPM_BZR 3;
BA_ "GenSigStartValue" SG_ 1173 TPM_BZR 3;
BA_ "GenSigSendType" SG_ 1173 TPM_REM 3;
BA_ "GenSigStartValue" SG_ 1173 TPM_REM 3;
BA_ "GenSigSendType" SG_ 1173 TPTSCVLD 3;
BA_ "GenSigSendType" SG_ 1173 TPM_WARI 3;
BA_ "GenSigSendType" SG_ 1174 TPM_TNUM 3;
BA_ "GenSigStartValue" SG_ 1174 TPM_TNUM 3;
BA_ "GenSigSendType" SG_ 1174 TPM_REQ0 3;
BA_ "GenSigSendType" SG_ 1174 TPM_TAN0 3;
BA_ "GenSigStartValue" SG_ 1174 TPM_TAN0 3;
BA_ "GenSigSendType" SG_ 1174 TPM_FLPR 3;
BA_ "GenSigStartValue" SG_ 1174 TPM_FLPR 127;
BA_ "GenSigSendType" SG_ 1174 TPM_FL0 3;
BA_ "GenSigSendType" SG_ 1174 TPM_FRPR 3;
BA_ "GenSigStartValue" SG_ 1174 TPM_FRPR 127;
BA_ "GenSigSendType" SG_ 1174 TPM_FR0 3;
BA_ "GenSigSendType" SG_ 1174 TPM_RLPR 3;
BA_ "GenSigStartValue" SG_ 1174 TPM_RLPR 127;
BA_ "GenSigSendType" SG_ 1174 TPM_RL0 3;
BA_ "GenSigSendType" SG_ 1174 TPM_RRPR 3;
BA_ "GenSigStartValue" SG_ 1174 TPM_RRPR 127;
BA_ "GenSigSendType" SG_ 1174 TPM_RR0 3;
BA_ "GenSigSendType" SG_ 1174 TPM_SPPR 3;
BA_ "GenSigStartValue" SG_ 1174 TPM_SPPR 127;
BA_ "GenSigSendType" SG_ 1174 TPM_SP0 3;
BA_ "GenSigStartValue" SG_ 839 TPFRSET1 127;
BA_ "GenSigStartValue" SG_ 839 TPFRSET2 127;
BA_ "GenSigStartValue" SG_ 839 TPFRSET3 127;
BA_ "GenSigStartValue" SG_ 839 TPFRSET4 127;
BA_ "GenSigStartValue" SG_ 839 TPFRSET5 127;
BA_ "GenSigStartValue" SG_ 839 TPFRSET6 127;
BA_ "GenSigStartValue" SG_ 844 TPRRSET1 127;
BA_ "GenSigStartValue" SG_ 844 TPRRSET2 127;
BA_ "GenSigStartValue" SG_ 844 TPRRSET3 127;
BA_ "GenSigStartValue" SG_ 844 TPRRSET4 127;
BA_ "GenSigStartValue" SG_ 844 TPRRSET5 127;
BA_ "GenSigStartValue" SG_ 844 TPRRSET6 127;
BA_ "GenSigSendType" SG_ 844 TPINTACK 3;
BA_ "GenSigSendType" SG_ 1047 TPMCNT1 3;
BA_ "GenSigSendType" SG_ 1047 TPMCNT2 3;
BA_ "GenSigSendType" SG_ 1047 TPMCNT3 3;
BA_ "GenSigSendType" SG_ 1047 TPMCNT4 3;
BA_ "GenSigSendType" SG_ 1047 TPMCNT5 3;
BA_ "GenSigSendType" SG_ 1047 TPM_LOC1 3;
BA_ "GenSigSendType" SG_ 1047 TPM_LOC2 3;
BA_ "GenSigSendType" SG_ 1047 TPM_LOC3 3;
BA_ "GenSigSendType" SG_ 1047 TPM_LOC4 3;
BA_ "GenSigSendType" SG_ 1047 TPM_LOC5 3;
BA_ "GenSigSendType" SG_ 879 TPTEMPFL 3;
BA_ "GenSigStartValue" SG_ 879 TPTEMPFL 255;
BA_ "GenSigSendType" SG_ 879 TPTEMPFR 3;
BA_ "GenSigStartValue" SG_ 879 TPTEMPFR 255;
BA_ "GenSigSendType" SG_ 879 TPTEMPRL 3;
BA_ "GenSigStartValue" SG_ 879 TPTEMPRL 255;
BA_ "GenSigSendType" SG_ 879 TPTEMPRR 3;
BA_ "GenSigStartValue" SG_ 879 TPTEMPRR 255;
BA_ "GenSigSendType" SG_ 879 TPTEMPSP 3;
BA_ "GenSigStartValue" SG_ 879 TPTEMPSP 255;
BA_ "GenSigSendType" SG_ 1048 TPMID1_1 3;
BA_ "GenSigStartValue" SG_ 1048 TPMID1_1 255;
BA_ "GenSigSendType" SG_ 1048 TPMID1_2 3;
BA_ "GenSigStartValue" SG_ 1048 TPMID1_2 255;
BA_ "GenSigSendType" SG_ 1048 TPMID1_3 3;
BA_ "GenSigStartValue" SG_ 1048 TPMID1_3 255;
BA_ "GenSigSendType" SG_ 1048 TPMID1_4 3;
BA_ "GenSigStartValue" SG_ 1048 TPMID1_4 255;
BA_ "GenSigSendType" SG_ 1048 TPMTEMP1 3;
BA_ "GenSigStartValue" SG_ 1048 TPMTEMP1 255;
BA_ "GenSigSendType" SG_ 1048 TPM_PR1 3;
BA_ "GenSigStartValue" SG_ 1048 TPM_PR1 255;
BA_ "GenSigSendType" SG_ 1048 TPBATLO1 3;
BA_ "GenSigSendType" SG_ 1048 TPM_TH1 3;
BA_ "GenSigStartValue" SG_ 1048 TPM_TH1 255;
BA_ "GenSigSendType" SG_ 1048 TPM_IND1 3;
BA_ "GenSigSendType" SG_ 1048 TPTGTPR1 3;
BA_ "GenSigStartValue" SG_ 1048 TPTGTPR1 255;
BA_ "GenSigSendType" SG_ 1062 TPMID2_1 3;
BA_ "GenSigStartValue" SG_ 1062 TPMID2_1 255;
BA_ "GenSigSendType" SG_ 1062 TPMID2_2 3;
BA_ "GenSigStartValue" SG_ 1062 TPMID2_2 255;
BA_ "GenSigSendType" SG_ 1062 TPMID2_3 3;
BA_ "GenSigStartValue" SG_ 1062 TPMID2_3 255;
BA_ "GenSigSendType" SG_ 1062 TPMID2_4 3;
BA_ "GenSigStartValue" SG_ 1062 TPMID2_4 255;
BA_ "GenSigSendType" SG_ 1062 TPMTEMP2 3;
BA_ "GenSigStartValue" SG_ 1062 TPMTEMP2 255;
BA_ "GenSigSendType" SG_ 1062 TPM_PR2 3;
BA_ "GenSigStartValue" SG_ 1062 TPM_PR2 255;
BA_ "GenSigSendType" SG_ 1062 TPBATLO2 3;
BA_ "GenSigSendType" SG_ 1062 TPM_TH2 3;
BA_ "GenSigStartValue" SG_ 1062 TPM_TH2 255;
BA_ "GenSigSendType" SG_ 1062 TPM_IND2 3;
BA_ "GenSigSendType" SG_ 1062 TPTGTPR2 3;
BA_ "GenSigStartValue" SG_ 1062 TPTGTPR2 255;
BA_ "GenSigSendType" SG_ 1064 TPMID3_1 3;
BA_ "GenSigStartValue" SG_ 1064 TPMID3_1 255;
BA_ "GenSigSendType" SG_ 1064 TPMID3_2 3;
BA_ "GenSigStartValue" SG_ 1064 TPMID3_2 255;
BA_ "GenSigSendType" SG_ 1064 TPMID3_3 3;
BA_ "GenSigStartValue" SG_ 1064 TPMID3_3 255;
BA_ "GenSigSendType" SG_ 1064 TPMID3_4 3;
BA_ "GenSigStartValue" SG_ 1064 TPMID3_4 255;
BA_ "GenSigSendType" SG_ 1064 TPMTEMP3 3;
BA_ "GenSigStartValue" SG_ 1064 TPMTEMP3 255;
BA_ "GenSigSendType" SG_ 1064 TPM_PR3 3;
BA_ "GenSigStartValue" SG_ 1064 TPM_PR3 255;
BA_ "GenSigSendType" SG_ 1064 TPBATLO3 3;
BA_ "GenSigSendType" SG_ 1064 TPM_TH3 3;
BA_ "GenSigStartValue" SG_ 1064 TPM_TH3 255;
BA_ "GenSigSendType" SG_ 1064 TPM_IND3 3;
BA_ "GenSigSendType" SG_ 1064 TPTGTPR3 3;
BA_ "GenSigStartValue" SG_ 1064 TPTGTPR3 255;
BA_ "GenSigSendType" SG_ 1066 TPMID4_1 3;
BA_ "GenSigStartValue" SG_ 1066 TPMID4_1 255;
BA_ "GenSigSendType" SG_ 1066 TPMID4_2 3;
BA_ "GenSigStartValue" SG_ 1066 TPMID4_2 255;
BA_ "GenSigSendType" SG_ 1066 TPMID4_3 3;
BA_ "GenSigStartValue" SG_ 1066 TPMID4_3 255;
BA_ "GenSigSendType" SG_ 1066 TPMID4_4 3;
BA_ "GenSigStartValue" SG_ 1066 TPMID4_4 255;
BA_ "GenSigSendType" SG_ 1066 TPMTEMP4 3;
BA_ "GenSigStartValue" SG_ 1066 TPMTEMP4 255;
BA_ "GenSigSendType" SG_ 1066 TPM_PR4 3;
BA_ "GenSigStartValue" SG_ 1066 TPM_PR4 255;
BA_ "GenSigSendType" SG_ 1066 TPBATLO4 3;
BA_ "GenSigSendType" SG_ 1066 TPM_TH4 3;
BA_ "GenSigStartValue" SG_ 1066 TPM_TH4 255;
BA_ "GenSigSendType" SG_ 1066 TPM_IND4 3;
BA_ "GenSigSendType" SG_ 1066 TPTGTPR4 3;
BA_ "GenSigStartValue" SG_ 1066 TPTGTPR4 255;
BA_ "GenSigSendType" SG_ 1068 TPMID5_1 3;
BA_ "GenSigStartValue" SG_ 1068 TPMID5_1 255;
BA_ "GenSigSendType" SG_ 1068 TPMID5_2 3;
BA_ "GenSigStartValue" SG_ 1068 TPMID5_2 255;
BA_ "GenSigSendType" SG_ 1068 TPMID5_3 3;
BA_ "GenSigStartValue" SG_ 1068 TPMID5_3 255;
BA_ "GenSigSendType" SG_ 1068 TPMID5_4 3;
BA_ "GenSigStartValue" SG_ 1068 TPMID5_4 255;
BA_ "GenSigSendType" SG_ 1068 TPMTEMP5 3;
BA_ "GenSigStartValue" SG_ 1068 TPMTEMP5 255;
BA_ "GenSigSendType" SG_ 1068 TPM_PR5 3;
BA_ "GenSigStartValue" SG_ 1068 TPM_PR5 255;
BA_ "GenSigSendType" SG_ 1068 TPBATLO5 3;
BA_ "GenSigSendType" SG_ 1068 TPM_TH5 3;
BA_ "GenSigStartValue" SG_ 1068 TPM_TH5 255;
BA_ "GenSigSendType" SG_ 1068 TPM_IND5 3;
BA_ "GenSigSendType" SG_ 1068 TPTGTPR5 3;
BA_ "GenSigStartValue" SG_ 1068 TPTGTPR5 255;
BA_ "GenSigSendType" SG_ 999 SPDL_SR 3;
BA_ "GenSigSendType" SG_ 999 SPDL_MR 3;
BA_ "GenSigSendType" SG_ 999 SFTL_SR 3;
BA_ "GenSigSendType" SG_ 999 SFTL_MR 3;
BA_ "GenSigSendType" SG_ 999 DOUL_SR 3;
BA_ "GenSigSendType" SG_ 999 DOUL_MR 3;
BA_ "GenSigSendType" SG_ 999 A_L_SR 3;
BA_ "GenSigSendType" SG_ 999 A_L_MR 3;
BA_ "GenSigSendType" SG_ 999 A_UL_SR 3;
BA_ "GenSigSendType" SG_ 999 A_UL_MR 3;
BA_ "GenSigSendType" SG_ 999 R2PUL_SR 3;
BA_ "GenSigSendType" SG_ 999 R2PUL_MR 3;
BA_ "GenSigSendType" SG_ 999 WLDO_SR 3;
BA_ "GenSigSendType" SG_ 999 WLDO_MR 3;
BA_ "GenSigSendType" SG_ 999 LU_FL_SR 3;
BA_ "GenSigSendType" SG_ 999 LU_FL_MR 3;
BA_ "GenSigSendType" SG_ 999 ARL_T_SR 3;
BA_ "GenSigSendType" SG_ 999 ARL_T_MR 3;
BA_ "GenSigSendType" SG_ 999 LU_FT_SR 3;
BA_ "GenSigSendType" SG_ 999 LU_FT_MR 3;
BA_ "GenSigSendType" SG_ 999 SDU_SR 3;
BA_ "GenSigSendType" SG_ 999 SDU_MR 3;
BA_ "GenSigSendType" SG_ 999 SESS_SR 3;
BA_ "GenSigSendType" SG_ 999 SESS_MR 3;
BA_ "GenSigSendType" SG_ 999 LSS_SR 3;
BA_ "GenSigSendType" SG_ 999 LSS_MR 3;
BA_ "GenSigSendType" SG_ 999 HL_T_SR 3;
BA_ "GenSigSendType" SG_ 999 HL_T_MR 3;
BA_ "GenSigSendType" SG_ 999 DRL_SR 3;
BA_ "GenSigSendType" SG_ 999 DRL_MR 3;
BA_ "GenSigSendType" SG_ 999 IL_T_SR 3;
BA_ "GenSigSendType" SG_ 999 IL_T_MR 3;
BA_ "GenSigSendType" SG_ 999 TITEC1SR 3;
BA_ "GenSigSendType" SG_ 999 TITEC1MR 3;
BA_ "GenSigSendType" SG_ 999 DSEE_SR 3;
BA_ "GenSigSendType" SG_ 999 DSEE_MR 3;
BA_ "GenSigSendType" SG_ 999 PBDOA_SR 3;
BA_ "GenSigSendType" SG_ 999 PBDOA_MR 3;
BA_ "GenSigSendType" SG_ 999 DSAL_SR 3;
BA_ "GenSigSendType" SG_ 999 DSAL_MR 3;
BA_ "GenSigSendType" SG_ 999 KPF_SR 3;
BA_ "GenSigSendType" SG_ 999 KPF_MR 3;
BA_ "GenSigSendType" SG_ 999 TEIAN1SR 3;
BA_ "GenSigSendType" SG_ 999 TEIAN1MR 3;
BA_ "GenSigSendType" SG_ 999 PSN_SR 3;
BA_ "GenSigSendType" SG_ 999 PSN_MR 3;
BA_ "GenSigSendType" SG_ 999 SFL_SR 3;
BA_ "GenSigSendType" SG_ 999 SFL_MR 3;
BA_ "GenSigSendType" SG_ 999 SFR_SR 3;
BA_ "GenSigSendType" SG_ 999 SFR_MR 3;
BA_ "GenSigSendType" SG_ 999 SHRL_SR 3;
BA_ "GenSigSendType" SG_ 999 SHRL_MR 3;
BA_ "GenSigSendType" SG_ 999 SHRR_SR 3;
BA_ "GenSigSendType" SG_ 999 SHRR_MR 3;
BA_ "GenSigSendType" SG_ 999 SWHTS_SR 3;
BA_ "GenSigSendType" SG_ 999 SWHTS_MR 3;
BA_ "GenSigSendType" SG_ 999 SSS_SR 3;
BA_ "GenSigSendType" SG_ 999 SSS_MR 3;
BA_ "GenSigSendType" SG_ 999 AACM_SR 3;
BA_ "GenSigSendType" SG_ 999 AACM_MR 3;
BA_ "GenSigSendType" SG_ 999 EVM_SR 3;
BA_ "GenSigSendType" SG_ 999 EVM_MR 3;
BA_ "GenSigSendType" SG_ 792 SPWNGMID 3;
BA_ "GenSigSendType" SG_ 792 SPWNGTT 3;
BA_ "GenSigStartValue" SG_ 106 VXFR 6767;
BA_ "GenSigStartValue" SG_ 106 VXFL 6767;
BA_ "GenSigStartValue" SG_ 106 VXRR 6767;
BA_ "GenSigStartValue" SG_ 106 VXRL 6767;
BA_ "GenSigStartValue" SG_ 105 VSC_GXIV 1;
BA_ "GenSigStartValue" SG_ 105 VSC_GYIV 1;
BA_ "GenSigStartValue" SG_ 105 VSC_YAWS 1;
BA_ "GenSigStartValue" SG_ 158 SP1S 1;
BA_ "GenSigStartValue" SG_ 158 PWCS 1;
BA_ "GenSigStartValue" SG_ 158 PMCS 1;
BA_ "GenSigSendType" SG_ 1537 PWD_EQ 3;
BA_ "GenSigSendType" SG_ 1537 PWP_EQ 3;
BA_ "GenSigSendType" SG_ 1537 PWR_EQ 3;
BA_ "GenSigSendType" SG_ 1537 PWL_EQ 3;
BA_ "GenSigSendType" SG_ 1537 SR_EQ 3;
BA_ "GenSigSendType" SG_ 1537 SR_VARI 3;
BA_ "GenSigSendType" SG_ 1537 PWD_AREA 3;
BA_ "GenSigSendType" SG_ 1537 PWP_AREA 3;
BA_ "GenSigSendType" SG_ 1537 PWR_AREA 3;
BA_ "GenSigSendType" SG_ 1537 PWL_AREA 3;
BA_ "GenSigSendType" SG_ 1537 SR_AREA 3;
BA_ "GenSigSendType" SG_ 761 FRWIPOPE 3;
BA_ "GenSigSendType" SG_ 761 FRWASH 3;
BA_ "GenSigSendType" SG_ 761 RRWIPOPE 3;
BA_ "GenSigSendType" SG_ 761 RRWASH 3;
BA_ "GenSigSendType" SG_ 638 YR_KLEG 3;
BA_ "GenSigStartValue" SG_ 895 BASEMDC1 255;
BA_ "GenSigStartValue" SG_ 895 BASEMDC2 255;
BA_ "GenSigStartValue" SG_ 895 BASEMDC3 255;
BA_ "GenSigStartValue" SG_ 895 BASEMDC4 255;
BA_ "GenSigStartValue" SG_ 895 BASEMDC5 15;
BA_ "GenSigStartValue" SG_ 895 BASEMDC6 15;
BA_ "GenSigStartValue" SG_ 895 BASEMDC7 31;
BA_ "GenSigStartValue" SG_ 906 BODY 255;
BA_ "GenSigStartValue" SG_ 906 ENGINE 255;
BA_ "GenSigStartValue" SG_ 906 GEAR 255;
BA_ "GenSigStartValue" SG_ 906 GRADE 255;
BA_ "GenSigStartValue" SG_ 906 POP_NAME 255;
BA_ "GenSigSendType" SG_ 478 ADIM2 3;
BA_ "GenSigSendType" SG_ 479 BVWRSW_V 3;
BA_ "GenSigSendType" SG_ 479 BVWRSW 3;
BA_ "GenSigSendType" SG_ 479 BPWRSW_V 3;
BA_ "GenSigSendType" SG_ 479 BPWRSW 3;
BA_ "GenSigSendType" SG_ 872 TITE_FNC 3;
BA_ "GenSigSendType" SG_ 872 TITE_VLD 3;
BA_ "GenSigSendType" SG_ 872 RES_PG 3;
BA_ "GenSigSendType" SG_ 872 HED_FNC 3;
BA_ "GenSigSendType" SG_ 872 TAL_FNC 3;
BA_ "GenSigSendType" SG_ 872 AUT_FNC 3;
BA_ "GenSigSendType" SG_ 872 DRL_FNC 3;
BA_ "GenSigSendType" SG_ 872 OFF_FNC 3;
BA_ "GenSigSendType" SG_ 872 FOG_FNC 3;
BA_ "GenSigSendType" SG_ 872 RFG_FNC 3;
BA_ "GenSigSendType" SG_ 872 HED_EN 3;
BA_ "GenSigSendType" SG_ 872 TAL_EN 3;
BA_ "GenSigSendType" SG_ 872 AUT_EN 3;
BA_ "GenSigSendType" SG_ 872 DRL_EN 3;
BA_ "GenSigSendType" SG_ 872 OFF_EN 3;
BA_ "GenSigSendType" SG_ 872 FOG_EN 3;
BA_ "GenSigSendType" SG_ 872 RFG_EN 3;
BA_ "GenSigSendType" SG_ 872 V_WIPDB 3;
BA_ "GenSigSendType" SG_ 872 LSW_STS 3;
BA_ "GenSigSendType" SG_ 872 FOG_STS 3;
BA_ "GenSigSendType" SG_ 872 RFG_STS 3;
BA_ "GenSigSendType" SG_ 872 V_WIPD 3;
BA_ "GenSigSendType" SG_ 872 PBD_PRE 3;
BA_ "GenSigSendType" SG_ 872 PBDOPPOS 3;
BA_ "GenSigSendType" SG_ 872 PBD_STS 3;
BA_ "GenSigSendType" SG_ 872 PWL_PRE 3;
BA_ "GenSigSendType" SG_ 872 PWL_VLD 3;
BA_ "GenSigSendType" SG_ 872 PWL_STS 3;
BA_ "GenSigSendType" SG_ 872 PBD_VLD 3;
BA_ "GenSigSendType" SG_ 872 WSVS_FNC 3;
BA_ "GenSigSendType" SG_ 872 WSVS_VLD 3;
BA_ "GenSigSendType" SG_ 872 WSVS_STS 3;
BA_ "GenSigSendType" SG_ 872 M_FNC 3;
BA_ "GenSigSendType" SG_ 872 M_VLD 3;
BA_ "GenSigSendType" SG_ 872 MLR_FNC 3;
BA_ "GenSigSendType" SG_ 872 MLR_VLD 3;
BA_ "GenSigSendType" SG_ 872 MLR_STS 3;
BA_ "GenSigSendType" SG_ 872 MRTR_FNC 3;
BA_ "GenSigSendType" SG_ 872 ARTR_FNC 3;
BA_ "GenSigSendType" SG_ 872 MRTR_VLD 3;
BA_ "GenSigSendType" SG_ 872 ARTR_VLD 3;
BA_ "GenSigSendType" SG_ 872 MRTR_STS 3;
BA_ "GenSigSendType" SG_ 872 RLM_FNC 3;
BA_ "GenSigSendType" SG_ 872 RLM_VLD 3;
BA_ "GenSigSendType" SG_ 872 RLM_STS 3;
BA_ "GenSigSendType" SG_ 872 ARTR_STS 3;
BA_ "GenSigSendType" SG_ 872 DRGSNABN 3;
BA_ "GenSigSendType" SG_ 872 RES_PCON 3;
BA_ "GenSigSendType" SG_ 872 SL_MRHTZ 3;
BA_ "GenSigSendType" SG_ 872 RC2OSW 3;
BA_ "GenSigStartValue" SG_ 872 RC2OSW 2;
BA_ "GenSigSendType" SG_ 872 CFOSW 3;
BA_ "GenSigStartValue" SG_ 872 CFOSW 2;
BA_ "GenSigSendType" SG_ 872 RR2OSW 3;
BA_ "GenSigStartValue" SG_ 872 RR2OSW 2;
BA_ "GenSigSendType" SG_ 872 RL3OSW 3;
BA_ "GenSigStartValue" SG_ 872 RL3OSW 2;
BA_ "GenSigSendType" SG_ 872 RL2OSW 3;
BA_ "GenSigStartValue" SG_ 872 RL2OSW 2;
BA_ "GenSigSendType" SG_ 872 RC3OSW 3;
BA_ "GenSigStartValue" SG_ 872 RC3OSW 2;
BA_ "GenSigSendType" SG_ 872 RR3OSW 3;
BA_ "GenSigStartValue" SG_ 872 RR3OSW 2;
BA_ "GenSigSendType" SG_ 920 ILEMB_MR 3;
BA_ "GenSigSendType" SG_ 920 SOCHL_MR 3;
BA_ "GenSigSendType" SG_ 920 PSDBV_MR 3;
BA_ "GenSigSendType" SG_ 920 HIDTC_MR 3;
BA_ "GenSigStartValue" SG_ 920 HIDTC_MR 1;
BA_ "GenSigSendType" SG_ 920 HIDLV_MR 3;
BA_ "GenSigStartValue" SG_ 920 HIDLV_MR 2;
BA_ "GenSigSendType" SG_ 920 APULK_MR 3;
BA_ "GenSigSendType" SG_ 920 DKYSW_MR 3;
BA_ "GenSigSendType" SG_ 920 ILANIA_M 3;
BA_ "GenSigSendType" SG_ 920 ILANIB_M 3;
BA_ "GenSigSendType" SG_ 920 ILANIC_M 3;
BA_ "GenSigSendType" SG_ 920 ILANID_M 3;
BA_ "GenSigSendType" SG_ 920 ILANIE_M 3;
BA_ "GenSigSendType" SG_ 920 ILANIF_M 3;
BA_ "GenSigSendType" SG_ 920 PBDHF_MR 3;
BA_ "GenSigSendType" SG_ 920 PBD_MR 3;
BA_ "GenSigSendType" SG_ 920 PTLHF_MR 3;
BA_ "GenSigSendType" SG_ 920 RSR_MR 3;
BA_ "GenSigSendType" SG_ 920 SDLHF_MR 3;
BA_ "GenSigSendType" SG_ 920 SDRHF_MR 3;
BA_ "GenSigSendType" SG_ 920 WALK_MR 3;
BA_ "GenSigSendType" SG_ 874 DM_M_SW 3;
BA_ "GenSigSendType" SG_ 874 DM_MVLD 3;
BA_ "GenSigSendType" SG_ 874 DM_P_SW 3;
BA_ "GenSigSendType" SG_ 874 DM_PVLD 3;
BA_ "GenSigSendType" SG_ 874 DM_SCVLD 3;
BA_ "GenSigSendType" SG_ 874 PCLMTRCA 3;
BA_ "GenSigSendType" SG_ 874 WM_STS 3;
BA_ "GenSigSendType" SG_ 874 WM_TRG 3;
BA_ "GenSigSendType" SG_ 874 DM_SC_SW 3;
BA_ "GenSigSendType" SG_ 874 WM_DSTS 3;
BA_ "GenSigSendType" SG_ 874 WVR_FNC 3;
BA_ "GenSigSendType" SG_ 874 WVR_VLD 3;
BA_ "GenSigSendType" SG_ 874 WVR_STS 3;
BA_ "GenSigSendType" SG_ 874 WRSW_FNC 3;
BA_ "GenSigSendType" SG_ 874 WCSW_FNC 3;
BA_ "GenSigSendType" SG_ 874 WRSW_VLD 3;
BA_ "GenSigSendType" SG_ 874 WRSW_STS 3;
BA_ "GenSigSendType" SG_ 874 WR_FNC 3;
BA_ "GenSigSendType" SG_ 874 WR_VLD 3;
BA_ "GenSigSendType" SG_ 874 WDI_FNC 3;
BA_ "GenSigSendType" SG_ 874 WR_STS 3;
BA_ "GenSigSendType" SG_ 874 WDI_VLD 3;
BA_ "GenSigSendType" SG_ 874 WDI_STS 3;
BA_ "GenSigSendType" SG_ 874 CFBCKL 3;
BA_ "GenSigStartValue" SG_ 874 CFBCKL 2;
BA_ "GenSigSendType" SG_ 874 CR2BCKL 3;
BA_ "GenSigStartValue" SG_ 874 CR2BCKL 2;
BA_ "GenSigSendType" SG_ 874 CR3BCKL 3;
BA_ "GenSigStartValue" SG_ 874 CR3BCKL 2;
BA_ "GenSigSendType" SG_ 874 DBKLSW 3;
BA_ "GenSigStartValue" SG_ 874 DBKLSW 2;
BA_ "GenSigSendType" SG_ 874 LR2BCKL 3;
BA_ "GenSigStartValue" SG_ 874 LR2BCKL 2;
BA_ "GenSigSendType" SG_ 874 LR3BCKL 3;
BA_ "GenSigStartValue" SG_ 874 LR3BCKL 2;
BA_ "GenSigSendType" SG_ 874 RR2BCKL 3;
BA_ "GenSigStartValue" SG_ 874 RR2BCKL 2;
BA_ "GenSigSendType" SG_ 874 RR3BCKL 3;
BA_ "GenSigStartValue" SG_ 874 RR3BCKL 2;
BA_ "GenSigSendType" SG_ 874 REVSW2 3;
BA_ "GenSigSendType" SG_ 874 HSW_PVM 3;
BA_ "GenSigSendType" SG_ 924 RECRNOFF 3;
BA_ "GenSigSendType" SG_ 924 GSNSOFF 3;
BA_ "GenSigSendType" SG_ 924 DRBDBABN 3;
BA_ "GenSigSendType" SG_ 1280 SPT_OPE 3;
BA_ "GenSigSendType" SG_ 1280 SPTWNG 3;
BA_ "GenSigSendType" SG_ 878 BZ_MSEAT 3;
BA_ "GenSigSendType" SG_ 878 KSSFAIL 3;
BA_ "GenSigSendType" SG_ 878 PCLPOSIL 3;
BA_ "GenSigSendType" SG_ 878 PCLPOSIR 3;
BA_ "GenSigSendType" SG_ 878 PCLEQPL 3;
BA_ "GenSigSendType" SG_ 878 PCLEQPR 3;
BA_ "GenSigSendType" SG_ 878 LPCL_CRQ 3;
BA_ "GenSigSendType" SG_ 878 RPCL_CRQ 3;
BA_ "GenSigSendType" SG_ 878 LPCL_ORQ 3;
BA_ "GenSigSendType" SG_ 878 RPCL_ORQ 3;
BA_ "GenSigSendType" SG_ 878 LPCL_OPE 3;
BA_ "GenSigSendType" SG_ 878 RPCL_OPE 3;
BA_ "GenSigSendType" SG_ 831 R_AC_ST 3;
BA_ "GenSigSendType" SG_ 831 R_SYS_2 3;
BA_ "GenSigSendType" SG_ 978 R_FTE_ST 3;
BA_ "GenSigSendType" SG_ 978 R_BD_ST 3;
BA_ "GenSigSendType" SG_ 978 R_TIME 3;
BA_ "GenSigSendType" SG_ 1017 R_INT_ST 3;
BA_ "GenSigSendType" SG_ 1024 R_LMP_ST 3;
BA_ "GenSigSendType" SG_ 1024 R_SDE_ST 3;
BA_ "GenSigSendType" SG_ 1024 R_SYS_3 3;
BA_ "GenSigSendType" SG_ 1028 R_ST_ST 3;
BA_ "GenSigSendType" SG_ 1028 R_SYS_1 3;
BA_ "GenSigStartValue" SG_ 963 VSI_L8A 255;
BA_ "GenSigSendType" SG_ 848 EIC_EQP 3;
BA_ "GenSigSendType" SG_ 848 EIC_FEQP 3;
BA_ "GenSigSendType" SG_ 848 EIC_SEQP 3;
BA_ "GenSigSendType" SG_ 848 EIC_IEQP 3;
BA_ "GenSigSendType" SG_ 848 EIC_BEQP 3;
BA_ "GenSigSendType" SG_ 848 QIC_BREQ 3;
BA_ "GenSigSendType" SG_ 848 QIC_DISP 3;
BA_ "GenSigSendType" SG_ 848 QIC_BVOL 3;
BA_ "GenSigSendType" SG_ 848 QIC_DIS 3;
BA_ "GenSigSendType" SG_ 848 EIC_DEQP 3;
BA_ "GenSigSendType" SG_ 848 EIC_PEQP 3;
BA_ "GenSigSendType" SG_ 848 EIC_REQP 3;
BA_ "GenSigSendType" SG_ 848 EIC_LEQP 3;
BA_ "GenSigSendType" SG_ 848 AIC_DRC 3;
BA_ "GenSigSendType" SG_ 848 AIC_DMRC 3;
BA_ "GenSigSendType" SG_ 848 AIC_DFRC 3;
BA_ "GenSigSendType" SG_ 848 AIC_DBRC 3;
BA_ "GenSigSendType" SG_ 848 AIC_DRRC 3;
BA_ "GenSigSendType" SG_ 848 SIC_DMST 3;
BA_ "GenSigSendType" SG_ 848 SIC_DCST 3;
BA_ "GenSigSendType" SG_ 848 SIC_DFFL 3;
BA_ "GenSigSendType" SG_ 848 SIC_DFFP 3;
BA_ "GenSigSendType" SG_ 848 SIC_DFRL 3;
BA_ "GenSigSendType" SG_ 848 SIC_DFRP 3;
BA_ "GenSigSendType" SG_ 848 SIC_DF5L 3;
BA_ "GenSigSendType" SG_ 848 SIC_DFDL 3;
BA_ "GenSigSendType" SG_ 848 SIC_DFDP 3;
BA_ "GenSigSendType" SG_ 848 SIC_DF4L 3;
BA_ "GenSigSendType" SG_ 848 SIC_DF4P 3;
BA_ "GenSigSendType" SG_ 848 SIC_DF5P 3;
BA_ "GenSigSendType" SG_ 848 SIC_DBFL 3;
BA_ "GenSigSendType" SG_ 848 SIC_DBFP 3;
BA_ "GenSigSendType" SG_ 848 SIC_DBRL 3;
BA_ "GenSigSendType" SG_ 848 SIC_DBRP 3;
BA_ "GenSigSendType" SG_ 848 SIC_DB5L 3;
BA_ "GenSigSendType" SG_ 848 SIC_DBDL 3;
BA_ "GenSigSendType" SG_ 848 SIC_DBDP 3;
BA_ "GenSigSendType" SG_ 848 SIC_DB4L 3;
BA_ "GenSigSendType" SG_ 848 SIC_DB4P 3;
BA_ "GenSigSendType" SG_ 848 SIC_DB5P 3;
BA_ "GenSigSendType" SG_ 848 SIC_DRFL 3;
BA_ "GenSigSendType" SG_ 848 SIC_DRRL 3;
BA_ "GenSigSendType" SG_ 848 SIC_DRDL 3;
BA_ "GenSigSendType" SG_ 848 SIC_DR4L 3;
BA_ "GenSigSendType" SG_ 848 SIC_DR5L 3;
BA_ "GenSigSendType" SG_ 848 SIC_DRFK 3;
BA_ "GenSigSendType" SG_ 848 SIC_DRRK 3;
BA_ "GenSigSendType" SG_ 848 SIC_DRDK 3;
BA_ "GenSigSendType" SG_ 848 SIC_DR4K 3;
BA_ "GenSigSendType" SG_ 848 SIC_DR5K 3;
BA_ "GenSigSendType" SG_ 848 AIC_PRC 3;
BA_ "GenSigSendType" SG_ 848 AIC_PMRC 3;
BA_ "GenSigSendType" SG_ 848 AIC_PFRC 3;
BA_ "GenSigSendType" SG_ 848 AIC_PBRC 3;
BA_ "GenSigSendType" SG_ 848 AIC_PRRC 3;
BA_ "GenSigSendType" SG_ 848 SIC_PMST 3;
BA_ "GenSigSendType" SG_ 848 SIC_PCST 3;
BA_ "GenSigSendType" SG_ 848 SIC_PFFL 3;
BA_ "GenSigSendType" SG_ 848 SIC_PFFP 3;
BA_ "GenSigSendType" SG_ 848 SIC_PFRL 3;
BA_ "GenSigSendType" SG_ 848 SIC_PFRP 3;
BA_ "GenSigSendType" SG_ 848 SIC_PF5L 3;
BA_ "GenSigSendType" SG_ 848 SIC_PFDL 3;
BA_ "GenSigSendType" SG_ 848 SIC_PFDP 3;
BA_ "GenSigSendType" SG_ 848 SIC_PF4L 3;
BA_ "GenSigSendType" SG_ 848 SIC_PF4P 3;
BA_ "GenSigSendType" SG_ 848 SIC_PF5P 3;
BA_ "GenSigSendType" SG_ 848 SIC_PBFL 3;
BA_ "GenSigSendType" SG_ 848 SIC_PBFP 3;
BA_ "GenSigSendType" SG_ 848 SIC_PBRL 3;
BA_ "GenSigSendType" SG_ 848 SIC_PBRP 3;
BA_ "GenSigSendType" SG_ 848 SIC_PB5L 3;
BA_ "GenSigSendType" SG_ 848 SIC_PBDL 3;
BA_ "GenSigSendType" SG_ 848 SIC_PBDP 3;
BA_ "GenSigSendType" SG_ 848 SIC_PB4L 3;
BA_ "GenSigSendType" SG_ 848 SIC_PB4P 3;
BA_ "GenSigSendType" SG_ 848 SIC_PB5P 3;
BA_ "GenSigSendType" SG_ 848 SIC_PRFL 3;
BA_ "GenSigSendType" SG_ 848 SIC_PRRL 3;
BA_ "GenSigSendType" SG_ 848 SIC_PRDL 3;
BA_ "GenSigSendType" SG_ 848 SIC_PR4L 3;
BA_ "GenSigSendType" SG_ 848 SIC_PR5L 3;
BA_ "GenSigSendType" SG_ 848 SIC_PRFK 3;
BA_ "GenSigSendType" SG_ 848 SIC_PRRK 3;
BA_ "GenSigSendType" SG_ 848 SIC_PRDK 3;
BA_ "GenSigSendType" SG_ 848 SIC_PR4K 3;
BA_ "GenSigSendType" SG_ 848 SIC_PR5K 3;
BA_ "GenSigSendType" SG_ 850 AIC_RRC 3;
BA_ "GenSigSendType" SG_ 850 AIC_RMRC 3;
BA_ "GenSigSendType" SG_ 850 AIC_RFRC 3;
BA_ "GenSigSendType" SG_ 850 AIC_RBRC 3;
BA_ "GenSigSendType" SG_ 850 AIC_RRRC 3;
BA_ "GenSigSendType" SG_ 850 SIC_RMST 3;
BA_ "GenSigSendType" SG_ 850 SIC_RCST 3;
BA_ "GenSigSendType" SG_ 850 SIC_RFFL 3;
BA_ "GenSigSendType" SG_ 850 SIC_RFFP 3;
BA_ "GenSigSendType" SG_ 850 SIC_RFRL 3;
BA_ "GenSigSendType" SG_ 850 SIC_RFRP 3;
BA_ "GenSigSendType" SG_ 850 SIC_RF5L 3;
BA_ "GenSigSendType" SG_ 850 SIC_RFDL 3;
BA_ "GenSigSendType" SG_ 850 SIC_RFDP 3;
BA_ "GenSigSendType" SG_ 850 SIC_RF4L 3;
BA_ "GenSigSendType" SG_ 850 SIC_RF4P 3;
BA_ "GenSigSendType" SG_ 850 SIC_RF5P 3;
BA_ "GenSigSendType" SG_ 850 SIC_RBFL 3;
BA_ "GenSigSendType" SG_ 850 SIC_RBFP 3;
BA_ "GenSigSendType" SG_ 850 SIC_RBRL 3;
BA_ "GenSigSendType" SG_ 850 SIC_RBRP 3;
BA_ "GenSigSendType" SG_ 850 SIC_RB5L 3;
BA_ "GenSigSendType" SG_ 850 SIC_RBDL 3;
BA_ "GenSigSendType" SG_ 850 SIC_RBDP 3;
BA_ "GenSigSendType" SG_ 850 SIC_RB4L 3;
BA_ "GenSigSendType" SG_ 850 SIC_RB4P 3;
BA_ "GenSigSendType" SG_ 850 SIC_RB5P 3;
BA_ "GenSigSendType" SG_ 850 SIC_RRFL 3;
BA_ "GenSigSendType" SG_ 850 SIC_RRRL 3;
BA_ "GenSigSendType" SG_ 850 SIC_RRDL 3;
BA_ "GenSigSendType" SG_ 850 SIC_RR4L 3;
BA_ "GenSigSendType" SG_ 850 SIC_RR5L 3;
BA_ "GenSigSendType" SG_ 850 SIC_RRFK 3;
BA_ "GenSigSendType" SG_ 850 SIC_RRRK 3;
BA_ "GenSigSendType" SG_ 850 SIC_RRDK 3;
BA_ "GenSigSendType" SG_ 850 SIC_RR4K 3;
BA_ "GenSigSendType" SG_ 850 SIC_RR5K 3;
BA_ "GenSigSendType" SG_ 850 AIC_LRC 3;
BA_ "GenSigSendType" SG_ 850 AIC_LMRC 3;
BA_ "GenSigSendType" SG_ 850 AIC_LFRC 3;
BA_ "GenSigSendType" SG_ 850 AIC_LBRC 3;
BA_ "GenSigSendType" SG_ 850 AIC_LRRC 3;
BA_ "GenSigSendType" SG_ 850 SIC_LMST 3;
BA_ "GenSigSendType" SG_ 850 SIC_LCST 3;
BA_ "GenSigSendType" SG_ 850 SIC_LFFL 3;
BA_ "GenSigSendType" SG_ 850 SIC_LFFP 3;
BA_ "GenSigSendType" SG_ 850 SIC_LFRL 3;
BA_ "GenSigSendType" SG_ 850 SIC_LFRP 3;
BA_ "GenSigSendType" SG_ 850 SIC_LF5L 3;
BA_ "GenSigSendType" SG_ 850 SIC_LFDL 3;
BA_ "GenSigSendType" SG_ 850 SIC_LFDP 3;
BA_ "GenSigSendType" SG_ 850 SIC_LF4L 3;
BA_ "GenSigSendType" SG_ 850 SIC_LF4P 3;
BA_ "GenSigSendType" SG_ 850 SIC_LF5P 3;
BA_ "GenSigSendType" SG_ 850 SIC_LBFL 3;
BA_ "GenSigSendType" SG_ 850 SIC_LBFP 3;
BA_ "GenSigSendType" SG_ 850 SIC_LBRL 3;
BA_ "GenSigSendType" SG_ 850 SIC_LBRP 3;
BA_ "GenSigSendType" SG_ 850 SIC_LB5L 3;
BA_ "GenSigSendType" SG_ 850 SIC_LBDL 3;
BA_ "GenSigSendType" SG_ 850 SIC_LBDP 3;
BA_ "GenSigSendType" SG_ 850 SIC_LB4L 3;
BA_ "GenSigSendType" SG_ 850 SIC_LB4P 3;
BA_ "GenSigSendType" SG_ 850 SIC_LB5P 3;
BA_ "GenSigSendType" SG_ 850 SIC_LRFL 3;
BA_ "GenSigSendType" SG_ 850 SIC_LRRL 3;
BA_ "GenSigSendType" SG_ 850 SIC_LRDL 3;
BA_ "GenSigSendType" SG_ 850 SIC_LR4L 3;
BA_ "GenSigSendType" SG_ 850 SIC_LR5L 3;
BA_ "GenSigSendType" SG_ 850 SIC_LRFK 3;
BA_ "GenSigSendType" SG_ 850 SIC_LRRK 3;
BA_ "GenSigSendType" SG_ 850 SIC_LRDK 3;
BA_ "GenSigSendType" SG_ 850 SIC_LR4K 3;
BA_ "GenSigSendType" SG_ 850 SIC_LR5K 3;
BA_ "GenSigSendType" SG_ 851 ERS_EQP 3;
BA_ "GenSigSendType" SG_ 851 ARS_RC 3;
BA_ "GenSigSendType" SG_ 851 RDK_FDAC 3;
BA_ "GenSigSendType" SG_ 851 RDK_OCAC 3;
BA_ "GenSigSendType" SG_ 851 ADK_CHGA 3;
BA_ "GenSigSendType" SG_ 851 ADK_FDWA 3;
BA_ "GenSigSendType" SG_ 851 ADK_ADLA 3;
BA_ "GenSigSendType" SG_ 851 ADK_OWDA 3;
BA_ "GenSigSendType" SG_ 851 ADK_OWNA 3;
BA_ "GenSigSendType" SG_ 851 ADK_REGA 3;
BA_ "GenSigSendType" SG_ 851 ADK_STCA 3;
BA_ "GenSigSendType" SG_ 851 EDK_EQP 3;
BA_ "GenSigSendType" SG_ 851 RDK_OCRL 3;
BA_ "GenSigSendType" SG_ 851 RDK_ADAC 3;
BA_ "GenSigSendType" SG_ 851 RDK_ADRL 3;
BA_ "GenSigSendType" SG_ 851 RDK_ODAC 3;
BA_ "GenSigSendType" SG_ 851 RDK_ODRL 3;
BA_ "GenSigSendType" SG_ 851 RDK_OGAC 3;
BA_ "GenSigSendType" SG_ 851 RDK_OGRL 3;
BA_ "GenSigSendType" SG_ 851 RDK_ORAC 3;
BA_ "GenSigSendType" SG_ 851 RDK_ORRL 3;
BA_ "GenSigSendType" SG_ 851 RDK_OWAC 3;
BA_ "GenSigSendType" SG_ 851 RDK_OWRL 3;
BA_ "GenSigSendType" SG_ 851 RDK_RACK 3;
BA_ "GenSigSendType" SG_ 851 RDK_CRL 3;
BA_ "GenSigSendType" SG_ 851 RSM_CRL 3;
BA_ "GenSigSendType" SG_ 851 RSM_LARE 3;
BA_ "GenSigSendType" SG_ 851 RSM_LCMN 3;
BA_ "GenSigSendType" SG_ 851 RSM_LRNG 3;
BA_ "GenSigSendType" SG_ 851 RSM_LTID 3;
BA_ "GenSigSendType" SG_ 851 RSM_RACK 3;
BA_ "GenSigSendType" SG_ 851 SDK_CNT 3;
BA_ "GenSigSendType" SG_ 851 SDK_PRG 3;
BA_ "GenSigSendType" SG_ 851 SDK_RGST 3;
BA_ "GenSigSendType" SG_ 851 SDK_IDME 3;
BA_ "GenSigSendType" SG_ 851 SDK_IDGR 3;
BA_ "GenSigSendType" SG_ 851 SDK_IDER 3;
BA_ "GenSigSendType" SG_ 851 SLID_RSP 3;
BA_ "GenSigSendType" SG_ 851 RDK_LTID 3;
BA_ "GenSigSendType" SG_ 851 RDK_LARE 3;
BA_ "GenSigSendType" SG_ 851 RDK_LCMN 3;
BA_ "GenSigSendType" SG_ 851 RDK_LRNG 3;
BA_ "GenSigSendType" SG_ 955 B_VOICES 3;
BA_ "GenSigSendType" SG_ 955 B_A_MUTE 3;
BA_ "GenSigSendType" SG_ 955 B_VOLDDN 3;
BA_ "GenSigSendType" SG_ 955 B_VOLUP 3;
BA_ "GenSigSendType" SG_ 955 B_SEEKDN 3;
BA_ "GenSigSendType" SG_ 955 B_SEEKUP 3;
BA_ "GenSigSendType" SG_ 955 B_VOL_LV 3;
BA_ "GenSigSendType" SG_ 955 R_PWR 3;
BA_ "GenSigSendType" SG_ 955 R_MODE_A 3;
BA_ "GenSigSendType" SG_ 955 R_VOLUP 3;
BA_ "GenSigSendType" SG_ 955 R_VOLDN 3;
BA_ "GenSigSendType" SG_ 955 R_TUNEUP 3;
BA_ "GenSigSendType" SG_ 955 R_TUNEDN 3;
BA_ "GenSigSendType" SG_ 955 R_CHUP 3;
BA_ "GenSigSendType" SG_ 955 R_CHDN 3;
BA_ "GenSigSendType" SG_ 955 R_EXIST 3;
BA_ "GenSigSendType" SG_ 481 TNLS 3;
BA_ "GenSigSendType" SG_ 481 TNLCOND 3;
BA_ "GenSigSendType" SG_ 937 TNS 3;
BA_ "GenSigSendType" SG_ 937 HZS 3;
BA_ "GenSigSendType" SG_ 937 BAONUSER 3;
BA_ "SystemSignalLongSymbol" SG_ 2564550624 S0_ServiceToolToAllFuncDiagReqMs "S0_ServiceToolToAllFuncDiagReqMsg";
BA_ "SystemSignalLongSymbol" SG_ 2564550624 S1_ServiceToolToAllFuncDiagReqMs "S1_ServiceToolToAllFuncDiagReqMsg";
BA_ "SystemSignalLongSymbol" SG_ 2564550624 S2_ServiceToolToAllFuncDiagReqMs "S2_ServiceToolToAllFuncDiagReqMsg";
BA_ "SystemSignalLongSymbol" SG_ 2564550624 S3_ServiceToolToAllFuncDiagReqMs "S3_ServiceToolToAllFuncDiagReqMsg";
BA_ "SystemSignalLongSymbol" SG_ 2564550624 S4_ServiceToolToAllFuncDiagReqMs "S4_ServiceToolToAllFuncDiagReqMsg";
BA_ "SystemSignalLongSymbol" SG_ 2564550624 S5_ServiceToolToAllFuncDiagReqMs "S5_ServiceToolToAllFuncDiagReqMsg";
BA_ "SystemSignalLongSymbol" SG_ 2564550624 S6_ServiceToolToAllFuncDiagReqMs "S6_ServiceToolToAllFuncDiagReqMsg";
BA_ "SystemSignalLongSymbol" SG_ 2564550624 S7_ServiceToolToAllFuncDiagReqMs "S7_ServiceToolToAllFuncDiagReqMsg";
BA_ "SystemSignalLongSymbol" SG_ 2564550625 S0_ServiceToolToAllFuncDiag_0000 "S0_ServiceToolToAllFuncDiagReqMsg";
BA_ "SystemSignalLongSymbol" SG_ 2564550625 S1_ServiceToolToAllFuncDiag_0000 "S1_ServiceToolToAllFuncDiagReqMsg";
BA_ "SystemSignalLongSymbol" SG_ 2564550625 S2_ServiceToolToAllFuncDiag_0000 "S2_ServiceToolToAllFuncDiagReqMsg";
BA_ "SystemSignalLongSymbol" SG_ 2564550625 S3_ServiceToolToAllFuncDiag_0000 "S3_ServiceToolToAllFuncDiagReqMsg";
BA_ "SystemSignalLongSymbol" SG_ 2564550625 S4_ServiceToolToAllFuncDiag_0000 "S4_ServiceToolToAllFuncDiagReqMsg";
BA_ "SystemSignalLongSymbol" SG_ 2564550625 S5_ServiceToolToAllFuncDiag_0000 "S5_ServiceToolToAllFuncDiagReqMsg";
BA_ "SystemSignalLongSymbol" SG_ 2564550625 S6_ServiceToolToAllFuncDiag_0000 "S6_ServiceToolToAllFuncDiagReqMsg";
BA_ "SystemSignalLongSymbol" SG_ 2564550625 S7_ServiceToolToAllFuncDiag_0000 "S7_ServiceToolToAllFuncDiagReqMsg";
